BO_ 2565900538 Cert_EOL_FA: 18 TesterMh
 SG_ Cert_EOL_FA_Unused : 0|8@1- (1,0) [-128|127] ""  PCM

BO_ 2565900362 Cert_EOL_4A: 19 PCM
 SG_ Cert_EOL_4A_Unused : 0|8@1- (1,0) [-128|127] "" Vector__XXX

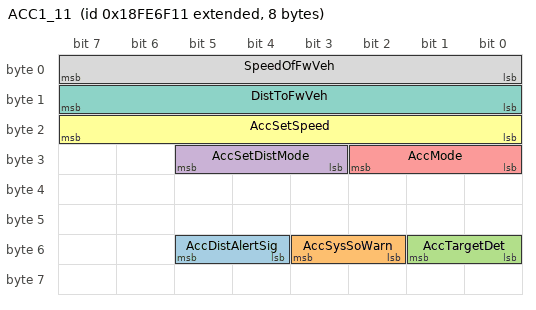
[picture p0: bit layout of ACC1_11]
BO_ 2566811409 ACC1_11: 8 NODE_11
 SG_ AccDistAlertSig : 52|2@1+ (1,0) [0|3] ""  PCM
 SG_ AccSysSoWarn : 50|2@1+ (1,0) [0|3] ""  PCM
 SG_ AccTargetDet : 48|2@1+ (1,0) [0|3] ""  PCM
 SG_ AccSetDistMode : 27|3@1+ (1,0) [0|7] ""  PCM
 SG_ AccMode : 24|3@1+ (1,0) [0|7] ""  PCM
 SG_ AccSetSpeed : 16|8@1+ (1,0) [0|250] "km/h"  PCM
 SG_ DistToFwVeh : 8|8@1+ (1,0) [0|250] "m"  PCM
 SG_ SpeedOfFwVeh : 0|8@1+ (1,0) [0|250] "km/h"  PCM

BO_ 2566803745 ACC2_21: 8 BCM
 SG_ ReqAccDistMode : 5|3@1+ (1,0) [0|7] ""  PCM
 SG_ AccUseDem : 0|2@1+ (1,0) [0|3] ""  PCM

BO_ 2565406464 ACKM_00: 8 ECM
 SG_ Pgn_Ack m0 : 40|24@1+ (1,0) [0|16777215] "binary"  PCM
 SG_ Pgn_Nack m1 : 40|24@1+ (1,0) [0|16777215] "binary"  PCM
 SG_ Pgn_Ad m2 : 40|24@1+ (1,0) [0|16777215] "binary"  PCM
 SG_ Pgn_Busy m3 : 40|24@1+ (1,0) [0|16777215] "binary"  PCM
 SG_ CtrlByte_Ackm M : 0|8@1+ (1,0) [0|255] "binary"  PCM

BO_ 2565406467 ACKM_03: 8 AI_G5_TCM
 SG_ Pgn_Ack_E8FF03 m0 : 40|24@1+ (1,0) [0|16777215] "binary"  PCM
 SG_ Pgn_Nack_E8FF03 m1 : 40|24@1+ (1,0) [0|16777215] "binary"  PCM
 SG_ Pgn_Ad_E8FF03 m2 : 40|24@1+ (1,0) [0|16777215] "binary"  PCM
 SG_ Pgn_Busy_E8FF03 m3 : 40|24@1+ (1,0) [0|16777215] "binary"  PCM
 SG_ AddrAckd m0 : 32|8@1+ (1,0) [0|255] ""  PCM
 SG_ AddrNack m1 : 32|8@1+ (1,0) [0|255] ""  PCM
 SG_ AddrAccessDenied m2 : 32|8@1+ (1,0) [0|255] ""  PCM
 SG_ AddrBusy m3 : 32|8@1+ (1,0) [0|255] ""  PCM
 SG_ GrpFunctVal_Ack m0 : 8|8@1+ (1,0) [0|250] "binary"  PCM
 SG_ GrpFunctVal_Nack m1 : 8|8@1+ (1,0) [0|250] "binary"  PCM
 SG_ CtrlByte_Ackm_E8FF03 M : 0|8@1+ (1,0) [0|255] "binary"  PCM

BO_ 2565406471 ACKM_07: 8 NODE_7
 SG_ Pgn_Ack_E8FF07 m0 : 40|24@1+ (1,0) [0|16777215] "binary"  PCM
 SG_ Pgn_Nack_E8FF07 m1 : 40|24@1+ (1,0) [0|16777215] "binary"  PCM
 SG_ Pgn_Ad_E8FF07 m2 : 40|24@1+ (1,0) [0|16777215] "binary"  PCM
 SG_ Pgn_Busy_E8FF07 m3 : 40|24@1+ (1,0) [0|16777215] "binary"  PCM
 SG_ AddrAckd_E8FF07 m0 : 32|8@1+ (1,0) [0|255] ""  PCM
 SG_ AddrNack_E8FF07 m1 : 32|8@1+ (1,0) [0|255] ""  PCM
 SG_ AddrAccessDenied_E8FF07 m2 : 32|8@1+ (1,0) [0|255] ""  PCM
 SG_ AddrBusy_E8FF07 m3 : 32|8@1+ (1,0) [0|255] ""  PCM
 SG_ CtrlByte_Ackm_E8FF07 M : 0|8@1+ (1,0) [0|255] "binary"  PCM

BO_ 2565406490 ACKM_1A: 8 ECS
 SG_ Pgn_Ack_E8FF1A m0 : 40|24@1+ (1,0) [0|16777215] "binary"  PCM
 SG_ Pgn_Nack_E8FF1A m1 : 40|24@1+ (1,0) [0|16777215] "binary"  PCM
 SG_ Pgn_Ad_E8FF1A m2 : 40|24@1+ (1,0) [0|16777215] "binary"  PCM
 SG_ Pgn_Busy_E8FF1A m3 : 40|24@1+ (1,0) [0|16777215] "binary"  PCM
 SG_ AddrAckd_E8FF1A m0 : 32|8@1+ (1,0) [0|255] ""  PCM
 SG_ AddrNack_E8FF1A m1 : 32|8@1+ (1,0) [0|255] ""  PCM
 SG_ AddrAccessDenied_E8FF1A m2 : 32|8@1+ (1,0) [0|255] ""  PCM
 SG_ AddrBusy_E8FF1A m3 : 32|8@1+ (1,0) [0|255] ""  PCM
 SG_ CtrlByte_Ackm_E8FF1A M : 0|8@1+ (1,0) [0|255] "binary"  PCM

BO_ 2565406493 ACKM_1D: 8 SGW
 SG_ Pgn_Ack_E8FF1D m0 : 40|24@1+ (1,0) [0|16777215] "binary"  PCM
 SG_ Pgn_Nack_E8FF1D m1 : 40|24@1+ (1,0) [0|16777215] "binary"  PCM
 SG_ Pgn_Ad_E8FF1D m2 : 40|24@1+ (1,0) [0|16777215] "binary"  PCM
 SG_ Pgn_Busy_E8FF1D m3 : 40|24@1+ (1,0) [0|16777215] "binary"  PCM
 SG_ AddrAckd_E8FF1D m0 : 32|8@1+ (1,0) [0|255] ""  PCM
 SG_ AddrNack_E8FF1D m1 : 32|8@1+ (1,0) [0|255] ""  PCM
 SG_ AddrAccessDenied_E8FF1D m2 : 32|8@1+ (1,0) [0|255] ""  PCM
 SG_ AddrBusy_E8FF1D m3 : 32|8@1+ (1,0) [0|255] ""  PCM
 SG_ CtrlByte_Ackm_E8FF1D M : 0|8@1+ (1,0) [0|255] "binary"  PCM

BO_ 2565406497 ACKM_21: 8 BCM
 SG_ Pgn_Ack_E8FF21 m0 : 40|24@1+ (1,0) [0|16777215] "binary"  PCM
 SG_ Pgn_Nack_E8FF21 m1 : 40|24@1+ (1,0) [0|16777215] "binary"  PCM
 SG_ Pgn_Ad_E8FF21 m2 : 40|24@1+ (1,0) [0|16777215] "binary"  PCM
 SG_ Pgn_Busy_E8FF21 m3 : 40|24@1+ (1,0) [0|16777215] "binary"  PCM
 SG_ AddrAckd_E8FF21 m0 : 32|8@1+ (1,0) [0|255] ""  PCM
 SG_ AddrNack_E8FF21 m1 : 32|8@1+ (1,0) [0|255] ""  PCM
 SG_ AddrAccessDenied_E8FF21 m2 : 32|8@1+ (1,0) [0|255] ""  PCM
 SG_ AddrBusy_E8FF21 m3 : 32|8@1+ (1,0) [0|255] ""  PCM
 SG_ CtrlByte_Ackm_E8FF21 M : 0|8@1+ (1,0) [0|255] "binary"  PCM

BO_ 2565406500 ACKM_24: 8 NODE_24
 SG_ Pgn_Ack_E8FF24 m0 : 40|24@1+ (1,0) [0|16777215] "binary"  PCM
 SG_ Pgn_Nack_E8FF24 m1 : 40|24@1+ (1,0) [0|16777215] "binary"  PCM
 SG_ Pgn_Ad_E8FF24 m2 : 40|24@1+ (1,0) [0|16777215] "binary"  PCM
 SG_ Pgn_Busy_E8FF24 m3 : 40|24@1+ (1,0) [0|16777215] "binary"  PCM
 SG_ AddrAckd_E8FF24 m0 : 32|8@1+ (1,0) [0|255] ""  PCM
 SG_ AddrNack_E8FF24 m1 : 32|8@1+ (1,0) [0|255] ""  PCM
 SG_ AddrAccessDenied_E8FF24 m2 : 32|8@1+ (1,0) [0|255] ""  PCM
 SG_ AddrBusy_E8FF24 m3 : 32|8@1+ (1,0) [0|255] ""  PCM
 SG_ CtrlByte_Ackm_E8FF24 M : 0|8@1+ (1,0) [0|255] "binary"  PCM

BO_ 2565406503 ACKM_27: 8 VCM
 SG_ Pgn_Ack_E8FF27 m0 : 40|24@1+ (1,0) [0|16777215] "binary"  PCM
 SG_ Pgn_Nack_E8FF27 m1 : 40|24@1+ (1,0) [0|16777215] "binary"  PCM
 SG_ Pgn_Ad_E8FF27 m2 : 40|24@1+ (1,0) [0|16777215] "binary"  PCM
 SG_ Pgn_Busy_E8FF27 m3 : 40|24@1+ (1,0) [0|16777215] "binary"  PCM
 SG_ AddrAckd_E8FF27 m0 : 32|8@1+ (1,0) [0|255] ""  PCM
 SG_ AddrNack_E8FF27 m1 : 32|8@1+ (1,0) [0|255] ""  PCM
 SG_ AddrAccessDenied_E8FF27 m2 : 32|8@1+ (1,0) [0|255] ""  PCM
 SG_ AddrBusy_E8FF27 m3 : 32|8@1+ (1,0) [0|255] ""  PCM
 SG_ CtrlByte_Ackm_E8FF27 M : 0|8@1+ (1,0) [0|255] "binary"  PCM

BO_ 2565406515 ACKM_33: 8 OptiTire
 SG_ Pgn_Ack_E8FF33 m0 : 40|24@1+ (1,0) [0|16777215] "binary"  PCM
 SG_ Pgn_Nack_E8FF33 m1 : 40|24@1+ (1,0) [0|16777215] "binary"  PCM
 SG_ Pgn_Ad_E8FF33 m2 : 40|24@1+ (1,0) [0|16777215] "binary"  PCM
 SG_ Pgn_Busy_E8FF33 m3 : 40|24@1+ (1,0) [0|16777215] "binary"  PCM
 SG_ CtrlByte_Ackm_E8FF33 M : 0|8@1+ (1,0) [0|255] "binary"  PCM

BO_ 2565406529 ACKM_41: 8 NIS_RDR
 SG_ Pgn_Ack_E8FF41 m0 : 40|24@1+ (1,0) [0|16777215] "binary"  PCM
 SG_ Pgn_Nack_E8FF41 m1 : 40|24@1+ (1,0) [0|16777215] "binary"  PCM
 SG_ Pgn_Ad_E8FF41 m2 : 40|24@1+ (1,0) [0|16777215] "binary"  PCM
 SG_ Pgn_Busy_E8FF41 m3 : 40|24@1+ (1,0) [0|16777215] "binary"  PCM
 SG_ AddrAckd_E8FF41 m0 : 32|8@1+ (1,0) [0|255] ""  PCM
 SG_ AddrNack_E8FF41 m1 : 32|8@1+ (1,0) [0|255] ""  PCM
 SG_ AddrAccessDenied_E8FF41 m2 : 32|8@1+ (1,0) [0|255] ""  PCM
 SG_ AddrBusy_E8FF41 m3 : 32|8@1+ (1,0) [0|255] ""  PCM
 SG_ CtrlByte_Ackm_E8FF41 M : 0|8@1+ (1,0) [0|255] "binary"  PCM

BO_ 2565406537 ACKM_49: 8 NODE_49
 SG_ Pgn_Ack_E8FF49 m0 : 40|24@1+ (1,0) [0|16777215] "binary"  PCM
 SG_ Pgn_Nack_E8FF49 m1 : 40|24@1+ (1,0) [0|16777215] "binary"  PCM
 SG_ Pgn_Ad_E8FF49 m2 : 40|24@1+ (1,0) [0|16777215] "binary"  PCM
 SG_ Pgn_Busy_E8FF49 m3 : 40|24@1+ (1,0) [0|16777215] "binary"  PCM
 SG_ AddrAckd_E8FF49 m0 : 32|8@1+ (1,0) [0|255] ""  PCM
 SG_ AddrNack_E8FF49 m1 : 32|8@1+ (1,0) [0|255] ""  PCM
 SG_ AddrAccessDenied_E8FF49 m2 : 32|8@1+ (1,0) [0|255] ""  PCM
 SG_ AddrBusy_E8FF49 m3 : 32|8@1+ (1,0) [0|255] ""  PCM
 SG_ CtrlByte_Ackm_E8FF49 M : 0|8@1+ (1,0) [0|255] "binary"  PCM

BO_ 2565406538 ACKM_4A: 8 PCM
 SG_ Pgn_Ack_E8FF4A m0 : 40|24@1+ (1,0) [0|16777215] "binary" Vector__XXX
 SG_ Pgn_Nack_E8FF4A m1 : 40|24@1+ (1,0) [0|16777215] "binary" Vector__XXX
 SG_ Pgn_Ad_E8FF4A m2 : 40|24@1+ (1,0) [0|16777215] "binary" Vector__XXX
 SG_ Pgn_Busy_E8FF4A m3 : 40|24@1+ (1,0) [0|16777215] "binary" Vector__XXX
 SG_ AddrAckd_E8FF4A m0 : 32|8@1+ (1,0) [0|255] "" Vector__XXX
 SG_ AddrNack_E8FF4A m1 : 32|8@1+ (1,0) [0|255] "" Vector__XXX
 SG_ AddrAccessDenied_E8FF4A m2 : 32|8@1+ (1,0) [0|255] "" Vector__XXX
 SG_ AddrBusy_E8FF4A m3 : 32|8@1+ (1,0) [0|255] "" Vector__XXX
 SG_ CtrlByte_Ackm_E8FF4A M : 0|8@1+ (1,0) [0|255] "binary" Vector__XXX

BO_ 2565406588 ACKM_7C: 8 NODE_7C
 SG_ Pgn_Ack_E8FF7C m0 : 40|24@1+ (1,0) [0|16777215] "binary"  PCM
 SG_ Pgn_Nack_E8FF7C m1 : 40|24@1+ (1,0) [0|16777215] "binary"  PCM
 SG_ Pgn_Ad_E8FF7C m2 : 40|24@1+ (1,0) [0|16777215] "binary"  PCM
 SG_ Pgn_Busy_E8FF7C m3 : 40|24@1+ (1,0) [0|16777215] "binary"  PCM
 SG_ AddrAckd_E8FF7C m0 : 32|8@1+ (1,0) [0|255] ""  PCM
 SG_ AddrNack_E8FF7C m1 : 32|8@1+ (1,0) [0|255] ""  PCM
 SG_ AddrAccessDenied_E8FF7C m2 : 32|8@1+ (1,0) [0|255] ""  PCM
 SG_ AddrBusy_E8FF7C m3 : 32|8@1+ (1,0) [0|255] ""  PCM
 SG_ CtrlByte_Ackm_E8FF7C M : 0|8@1+ (1,0) [0|255] "binary"  PCM

BO_ 2565406598 ACKM_86: 8 NODE_86
 SG_ Pgn_Ack_E8FF86 m0 : 40|24@1+ (1,0) [0|16777215] "binary"  PCM
 SG_ Pgn_Nack_E8FF86 m1 : 40|24@1+ (1,0) [0|16777215] "binary"  PCM
 SG_ Pgn_Ad_E8FF86 m2 : 40|24@1+ (1,0) [0|16777215] "binary"  PCM
 SG_ Pgn_Busy_E8FF86 m3 : 40|24@1+ (1,0) [0|16777215] "binary"  PCM
 SG_ AddrAckd_E8FF86 m0 : 32|8@1+ (1,0) [0|255] ""  PCM
 SG_ AddrNack_E8FF86 m1 : 32|8@1+ (1,0) [0|255] ""  PCM
 SG_ AddrAccessDenied_E8FF86 m2 : 32|8@1+ (1,0) [0|255] ""  PCM
 SG_ AddrBusy_E8FF86 m3 : 32|8@1+ (1,0) [0|255] ""  PCM
 SG_ CtrlByte_Ackm_E8FF86 M : 0|8@1+ (1,0) [0|255] "binary"  PCM

BO_ 2565406599 ACKM_87: 8 NODE_87
 SG_ Pgn_Ack_E8FF87 m0 : 40|24@1+ (1,0) [0|16777215] "binary"  PCM
 SG_ Pgn_Nack_E8FF87 m1 : 40|24@1+ (1,0) [0|16777215] "binary"  PCM
 SG_ Pgn_Ad_E8FF87 m2 : 40|24@1+ (1,0) [0|16777215] "binary"  PCM
 SG_ Pgn_Busy_E8FF87 m3 : 40|24@1+ (1,0) [0|16777215] "binary"  PCM
 SG_ AddrAckd_E8FF87 m0 : 32|8@1+ (1,0) [0|255] ""  PCM
 SG_ AddrNack_E8FF87 m1 : 32|8@1+ (1,0) [0|255] ""  PCM
 SG_ AddrAccessDenied_E8FF87 m2 : 32|8@1+ (1,0) [0|255] ""  PCM
 SG_ AddrBusy_E8FF87 m3 : 32|8@1+ (1,0) [0|255] ""  PCM
 SG_ CtrlByte_Ackm_E8FF87 M : 0|8@1+ (1,0) [0|255] "binary"  PCM

BO_ 2565406702 ACKM_EE: 8 DTCO
 SG_ Pgn_Ack_E8FFEE m0 : 40|24@1+ (1,0) [0|16777215] "binary"  PCM
 SG_ Pgn_Nack_E8FFEE m1 : 40|24@1+ (1,0) [0|16777215] "binary"  PCM
 SG_ Pgn_Ad_E8FFEE m2 : 40|24@1+ (1,0) [0|16777215] "binary"  PCM
 SG_ Pgn_Busy_E8FFEE m3 : 40|24@1+ (1,0) [0|16777215] "binary"  PCM
 SG_ AddrAckd_E8FFEE m0 : 32|8@1+ (1,0) [0|255] ""  PCM
 SG_ AddrNack_E8FFEE m1 : 32|8@1+ (1,0) [0|255] ""  PCM
 SG_ AddrAccessDenied_E8FFEE m2 : 32|8@1+ (1,0) [0|255] ""  PCM
 SG_ AddrBusy_E8FFEE m3 : 32|8@1+ (1,0) [0|255] ""  PCM
 SG_ CtrlByte_Ackm_E8FFEE M : 0|8@1+ (1,0) [0|255] "binary"  PCM

BO_ 2565406703 ACKM_EF: 8 NODE_EF
 SG_ Pgn_Ack_E8FFEF m0 : 40|24@1+ (1,0) [0|16777215] "binary"  PCM
 SG_ Pgn_Nack_E8FFEF m1 : 40|24@1+ (1,0) [0|16777215] "binary"  PCM
 SG_ Pgn_Ad_E8FFEF m2 : 40|24@1+ (1,0) [0|16777215] "binary"  PCM
 SG_ Pgn_Busy_E8FFEF m3 : 40|24@1+ (1,0) [0|16777215] "binary"  PCM
 SG_ AddrAckd_E8FFEF m0 : 32|8@1+ (1,0) [0|255] ""  PCM
 SG_ AddrNack_E8FFEF m1 : 32|8@1+ (1,0) [0|255] ""  PCM
 SG_ AddrAccessDenied_E8FFEF m2 : 32|8@1+ (1,0) [0|255] ""  PCM
 SG_ AddrBusy_E8FFEF m3 : 32|8@1+ (1,0) [0|255] ""  PCM
 SG_ CtrlByte_Ackm_E8FFEF M : 0|8@1+ (1,0) [0|255] "binary"  PCM

BO_ 2565406706 ACKM_F2: 8 NODE_F2
 SG_ Pgn_Ack_E8FFF2 m0 : 40|24@1+ (1,0) [0|16777215] "binary"  PCM
 SG_ Pgn_Nack_E8FFF2 m1 : 40|24@1+ (1,0) [0|16777215] "binary"  PCM
 SG_ Pgn_Ad_E8FFF2 m2 : 40|24@1+ (1,0) [0|16777215] "binary"  PCM
 SG_ Pgn_Busy_E8FFF2 m3 : 40|24@1+ (1,0) [0|16777215] "binary"  PCM
 SG_ AddrAckd_E8FFF2 m0 : 32|8@1+ (1,0) [0|255] ""  PCM
 SG_ AddrNack_E8FFF2 m1 : 32|8@1+ (1,0) [0|255] ""  PCM
 SG_ AddrAccessDenied_E8FFF2 m2 : 32|8@1+ (1,0) [0|255] ""  PCM
 SG_ AddrBusy_E8FFF2 m3 : 32|8@1+ (1,0) [0|255] ""  PCM
 SG_ CtrlByte_Ackm_E8FFF2 M : 0|8@1+ (1,0) [0|255] "binary"  PCM

BO_ 2565406707 ACKM_F3: 8 NODE_F3
 SG_ Pgn_Ack_E8FFF3 m0 : 40|24@1+ (1,0) [0|16777215] "binary"  PCM
 SG_ Pgn_Nack_E8FFF3 m1 : 40|24@1+ (1,0) [0|16777215] "binary"  PCM
 SG_ Pgn_Ad_E8FFF3 m2 : 40|24@1+ (1,0) [0|16777215] "binary"  PCM
 SG_ Pgn_Busy_E8FFF3 m3 : 40|24@1+ (1,0) [0|16777215] "binary"  PCM
 SG_ AddrAckd_E8FFF3 m0 : 32|8@1+ (1,0) [0|255] ""  PCM
 SG_ AddrNack_E8FFF3 m1 : 32|8@1+ (1,0) [0|255] ""  PCM
 SG_ AddrAccessDenied_E8FFF3 m2 : 32|8@1+ (1,0) [0|255] ""  PCM
 SG_ AddrBusy_E8FFF3 m3 : 32|8@1+ (1,0) [0|255] ""  PCM
 SG_ CtrlByte_Ackm_E8FFF3 M : 0|8@1+ (1,0) [0|255] "binary"  PCM

BO_ 2565406708 ACKM_F4: 8 NODE_F4
 SG_ Pgn_Ack_E8FFF4 m0 : 40|24@1+ (1,0) [0|16777215] "binary"  PCM
 SG_ Pgn_Nack_E8FFF4 m1 : 40|24@1+ (1,0) [0|16777215] "binary"  PCM
 SG_ Pgn_Ad_E8FFF4 m2 : 40|24@1+ (1,0) [0|16777215] "binary"  PCM
 SG_ Pgn_Busy_E8FFF4 m3 : 40|24@1+ (1,0) [0|16777215] "binary"  PCM
 SG_ AddrAckd_E8FFF4 m0 : 32|8@1+ (1,0) [0|255] ""  PCM
 SG_ AddrNack_E8FFF4 m1 : 32|8@1+ (1,0) [0|255] ""  PCM
 SG_ AddrAccessDenied_E8FFF4 m2 : 32|8@1+ (1,0) [0|255] ""  PCM
 SG_ AddrBusy_E8FFF4 m3 : 32|8@1+ (1,0) [0|255] ""  PCM
 SG_ CtrlByte_Ackm_E8FFF4 M : 0|8@1+ (1,0) [0|255] "binary"  PCM

CM_ SG_ 2566811409 AccSetDistMode "- 101b when ACC is not selected
-  Used Distance Modes #1 (000b), #3 (010b), #5 (100b)";
CM_ SG_ 2566803745 ReqAccDistMode "- Memorisation and toggle logic in the source device
-  Used Distance Modes #1 (000b), #3 (010b), #5 (100b)";
CM_ SG_ 2566803745 AccUseDem "- 10b used for Error Indicator
-  Memorisation and toggle logic in the source device";
CM_ BO_ 2565406464 "- NACK required as a response to a destination specific request that cannot be served, ACK/NACK not permitted for a global request (SAE J1939/21).";
CM_ SG_ 2565406464 Pgn_Ack "- Value Table filled with the most commonly used PGNs in Iveco applications, ECU implementation may differ";
CM_ SG_ 2565406464 Pgn_Nack "- Value Table filled with the most commonly used PGNs in Iveco applications, ECU implementation may differ";
CM_ SG_ 2565406464 Pgn_Ad "- Value Table filled with the most commonly used PGNs in Iveco applications, ECU implementation may differ";
CM_ SG_ 2565406464 Pgn_Busy "- Value Table filled with the most commonly used PGNs in Iveco applications, ECU implementation may differ";
CM_ BO_ 2565406467 "- NACK required as a response to a destination specific request that cannot be served, ACK/NACK not permitted for a global request (SAE J1939/21).";
CM_ SG_ 2565406467 Pgn_Ack_E8FF03 "- Value Table filled with the most commonly used PGNs in Iveco applications, ECU implementation may differ";
CM_ SG_ 2565406467 Pgn_Nack_E8FF03 "- Value Table filled with the most commonly used PGNs in Iveco applications, ECU implementation may differ";
CM_ SG_ 2565406467 Pgn_Ad_E8FF03 "- Value Table filled with the most commonly used PGNs in Iveco applications, ECU implementation may differ";
CM_ SG_ 2565406467 Pgn_Busy_E8FF03 "- Value Table filled with the most commonly used PGNs in Iveco applications, ECU implementation may differ";
CM_ BO_ 2565406490 "- NACK required as a response to a destination specific request that cannot be served, ACK/NACK not permitted for a global request (SAE J1939/21).";
CM_ SG_ 2565406490 Pgn_Ack_E8FF1A "- Value Table filled with the most commonly used PGNs in Iveco applications, ECU implementation may differ";
CM_ SG_ 2565406490 Pgn_Nack_E8FF1A "- Value Table filled with the most commonly used PGNs in Iveco applications, ECU implementation may differ";
CM_ SG_ 2565406490 Pgn_Ad_E8FF1A "- Value Table filled with the most commonly used PGNs in Iveco applications, ECU implementation may differ";
CM_ SG_ 2565406490 Pgn_Busy_E8FF1A "- Value Table filled with the most commonly used PGNs in Iveco applications, ECU implementation may differ";
CM_ BO_ 2565406493 "- NACK required as a response to a destination specific request that cannot be served, ACK/NACK not permitted for a global request (SAE J1939/21).";
CM_ SG_ 2565406493 Pgn_Ack_E8FF1D "- Value Table filled with the most commonly used PGNs in Iveco applications, ECU implementation may differ";
CM_ SG_ 2565406493 Pgn_Nack_E8FF1D "- Value Table filled with the most commonly used PGNs in Iveco applications, ECU implementation may differ";
CM_ SG_ 2565406493 Pgn_Ad_E8FF1D "- Value Table filled with the most commonly used PGNs in Iveco applications, ECU implementation may differ";
CM_ SG_ 2565406493 Pgn_Busy_E8FF1D "- Value Table filled with the most commonly used PGNs in Iveco applications, ECU implementation may differ";
CM_ BO_ 2565406497 "- NACK required as a response to a destination specific request that cannot be served, ACK/NACK not permitted for a global request (SAE J1939/21).";
CM_ SG_ 2565406497 Pgn_Ack_E8FF21 "- Value Table filled with the most commonly used PGNs in Iveco applications, ECU implementation may differ";
CM_ SG_ 2565406497 Pgn_Nack_E8FF21 "- Value Table filled with the most commonly used PGNs in Iveco applications, ECU implementation may differ";
CM_ SG_ 2565406497 Pgn_Ad_E8FF21 "- Value Table filled with the most commonly used PGNs in Iveco applications, ECU implementation may differ";
CM_ SG_ 2565406497 Pgn_Busy_E8FF21 "- Value Table filled with the most commonly used PGNs in Iveco applications, ECU implementation may differ";
CM_ BO_ 2565406503 "- NACK required as a response to a destination specific request that cannot be served, ACK/NACK not permitted for a global request (SAE J1939/21).";
CM_ SG_ 2565406503 Pgn_Ack_E8FF27 "- Value Table filled with the most commonly used PGNs in Iveco applications, ECU implementation may differ";
CM_ SG_ 2565406503 Pgn_Nack_E8FF27 "- Value Table filled with the most commonly used PGNs in Iveco applications, ECU implementation may differ";
CM_ SG_ 2565406503 Pgn_Ad_E8FF27 "- Value Table filled with the most commonly used PGNs in Iveco applications, ECU implementation may differ";
CM_ SG_ 2565406503 Pgn_Busy_E8FF27 "- Value Table filled with the most commonly used PGNs in Iveco applications, ECU implementation may differ";
CM_ BO_ 2565406515 "- NACK required as a response to a destination specific request that cannot be served, ACK/NACK not permitted for a global request (SAE J1939/21).";
CM_ SG_ 2565406515 Pgn_Ack_E8FF33 "- Value Table filled with the most commonly used PGNs in Iveco applications, ECU implementation may differ";
CM_ SG_ 2565406515 Pgn_Nack_E8FF33 "- Value Table filled with the most commonly used PGNs in Iveco applications, ECU implementation may differ";
CM_ SG_ 2565406515 Pgn_Ad_E8FF33 "- Value Table filled with the most commonly used PGNs in Iveco applications, ECU implementation may differ";
CM_ SG_ 2565406515 Pgn_Busy_E8FF33 "- Value Table filled with the most commonly used PGNs in Iveco applications, ECU implementation may differ";
CM_ BO_ 2565406538 "- NACK required as a response to a destination specific request that cannot be served, ACK/NACK not permitted for a global request (SAE J1939/21).";
CM_ SG_ 2565406538 Pgn_Ack_E8FF4A "- Value Table filled with the most commonly used PGNs in Iveco applications, ECU implementation may differ";
CM_ SG_ 2565406538 Pgn_Nack_E8FF4A "- Value Table filled with the most commonly used PGNs in Iveco applications, ECU implementation may differ";
CM_ SG_ 2565406538 Pgn_Ad_E8FF4A "- Value Table filled with the most commonly used PGNs in Iveco applications, ECU implementation may differ";
CM_ SG_ 2565406538 Pgn_Busy_E8FF4A "- Value Table filled with the most commonly used PGNs in Iveco applications, ECU implementation may differ";
CM_ SG_ 2565406588 Pgn_Ack_E8FF7C "- Value Table filled with the most commonly used PGNs in Iveco applications, ECU implementation may differ";
CM_ SG_ 2565406588 Pgn_Nack_E8FF7C "- Value Table filled with the most commonly used PGNs in Iveco applications, ECU implementation may differ";
CM_ SG_ 2565406588 Pgn_Ad_E8FF7C "- Value Table filled with the most commonly used PGNs in Iveco applications, ECU implementation may differ";
CM_ SG_ 2565406588 Pgn_Busy_E8FF7C "- Value Table filled with the most commonly used PGNs in Iveco applications, ECU implementation may differ";
CM_ BO_ 2565406702 "- NACK required as a response to a destination specific request that cannot be served, ACK/NACK not permitted for a global request (SAE J1939/21).";
CM_ SG_ 2565406702 Pgn_Ack_E8FFEE "- Value Table filled with the most commonly used PGNs in Iveco applications, ECU implementation may differ";
CM_ SG_ 2565406702 Pgn_Nack_E8FFEE "- Value Table filled with the most commonly used PGNs in Iveco applications, ECU implementation may differ";
CM_ SG_ 2565406702 Pgn_Ad_E8FFEE "- Value Table filled with the most commonly used PGNs in Iveco applications, ECU implementation may differ";
CM_ SG_ 2565406702 Pgn_Busy_E8FFEE "- Value Table filled with the most commonly used PGNs in Iveco applications, ECU implementation may differ";
CM_ BO_ 2565406703 "- NACK required as a response to a destination specific request that cannot be served, ACK/NACK not permitted for a global request (SAE J1939/21).";
CM_ SG_ 2565406703 Pgn_Ack_E8FFEF "- Value Table filled with the most commonly used PGNs in Iveco applications, ECU implementation may differ";
CM_ SG_ 2565406703 Pgn_Nack_E8FFEF "- Value Table filled with the most commonly used PGNs in Iveco applications, ECU implementation may differ";
CM_ SG_ 2565406703 Pgn_Ad_E8FFEF "- Value Table filled with the most commonly used PGNs in Iveco applications, ECU implementation may differ";
CM_ SG_ 2565406703 Pgn_Busy_E8FFEF "- Value Table filled with the most commonly used PGNs in Iveco applications, ECU implementation may differ";
CM_ BO_ 2565406706 "- NACK required as a response to a destination specific request that cannot be served, ACK/NACK not permitted for a global request (SAE J1939/21).";
CM_ SG_ 2565406706 Pgn_Ack_E8FFF2 "- Value Table filled with the most commonly used PGNs in Iveco applications, ECU implementation may differ";
CM_ SG_ 2565406706 Pgn_Nack_E8FFF2 "- Value Table filled with the most commonly used PGNs in Iveco applications, ECU implementation may differ";
CM_ SG_ 2565406706 Pgn_Ad_E8FFF2 "- Value Table filled with the most commonly used PGNs in Iveco applications, ECU implementation may differ";
CM_ SG_ 2565406706 Pgn_Busy_E8FFF2 "- Value Table filled with the most commonly used PGNs in Iveco applications, ECU implementation may differ";
CM_ BO_ 2565406707 "- NACK required as a response to a destination specific request that cannot be served, ACK/NACK not permitted for a global request (SAE J1939/21).";
CM_ SG_ 2565406707 Pgn_Ack_E8FFF3 "- Value Table filled with the most commonly used PGNs in Iveco applications, ECU implementation may differ";
CM_ SG_ 2565406707 Pgn_Nack_E8FFF3 "- Value Table filled with the most commonly used PGNs in Iveco applications, ECU implementation may differ";
CM_ SG_ 2565406707 Pgn_Ad_E8FFF3 "- Value Table filled with the most commonly used PGNs in Iveco applications, ECU implementation may differ";
CM_ SG_ 2565406707 Pgn_Busy_E8FFF3 "- Value Table filled with the most commonly used PGNs in Iveco applications, ECU implementation may differ";
CM_ BO_ 2565406708 "- NACK required as a response to a destination specific request that cannot be served, ACK/NACK not permitted for a global request (SAE J1939/21).";
CM_ SG_ 2565406708 Pgn_Ack_E8FFF4 "- Value Table filled with the most commonly used PGNs in Iveco applications, ECU implementation may differ";
CM_ SG_ 2565406708 Pgn_Nack_E8FFF4 "- Value Table filled with the most commonly used PGNs in Iveco applications, ECU implementation may differ";
CM_ SG_ 2565406708 Pgn_Ad_E8FFF4 "- Value Table filled with the most commonly used PGNs in Iveco applications, ECU implementation may differ";
CM_ SG_ 2565406708 Pgn_Busy_E8FFF4 "- Value Table filled with the most commonly used PGNs in Iveco applications, ECU implementation may differ";
BA_DEF_ BO_  "CI_MsgDefinition" STRING ;
BA_DEF_ BO_  "CI_MsgId" INT 0 2147483647;
BA_DEF_ BO_  "CI_MsgName" STRING ;
BA_DEF_ BO_  "GenMsgCycleTime" INT 0 3600000;
BA_DEF_ BO_  "GenMsgCycleTimeFast" INT 0 3600000;
BA_DEF_ BO_  "GenMsgDelayTime" INT 0 3600000;
BA_DEF_ BO_  "GenMsgILSupport" ENUM  "No","Yes";
BA_DEF_ BO_  "GenMsgNrOfRepetition" INT 0 1000000;
BA_DEF_ BO_  "GenMsgRequestable" INT 0 1;
BA_DEF_ BO_  "GenMsgSendType" ENUM  "cyclic","NotUsed","NotUsed","NotUsed","NotUsed","NotUsed","NotUsed","IfActive","noMsgSendType";
BA_DEF_ BO_  "GenMsgStartDelayTime" INT 0 100000;
BA_DEF_ BO_  "TpJ1939VarDlc" ENUM  "No","Yes";
BA_DEF_ BO_  "VFrameFormat" ENUM  "StandardCAN","ExtendedCAN","reserved","J1939PG";
BA_DEF_ SG_  "CI_ParId" STRING ;
BA_DEF_ SG_  "CI_SigId" INT 0 2147483647;
BA_DEF_ SG_  "CI_SigName" STRING ;
BA_DEF_ SG_  "GenSigEVName" STRING ;
BA_DEF_ SG_  "GenSigILSupport" ENUM  "No","Yes";
BA_DEF_ SG_  "GenSigInactiveValue" INT 0 2147483647;
BA_DEF_ SG_  "GenSigSendType" ENUM  "Cyclic","OnWrite","OnWriteWithRepetition","OnChange","OnChangeWithRepetition","IfActive","IfActiveWithRepetition","NoSigSendType";
BA_DEF_ SG_  "GenSigStartValue" INT 0 2147483647;
BA_DEF_ SG_  "GenSigTimeoutTime_PCM" INT 0 3600000;
BA_DEF_ SG_  "GenSigTimeoutTime_SGW" INT 0 3600000;
BA_DEF_ SG_  "SPN" INT 0 524287;
BA_DEF_ SG_  "SigType" ENUM  "Default","Range","RangeSigned","ASCII","Discrete","Control","ReferencePGN","DTC","StringDelimiter","StringLength","StringLengthControl";
BA_DEF_ BU_  "ECU" STRING ;
BA_DEF_ BU_  "ILUsed" ENUM  "No","Yes";
BA_DEF_ BU_  "NmJ1939ECUInstance" INT 0 7;
BA_DEF_ BU_  "NmJ1939IdentityNumber" INT 0 2097151;
BA_DEF_ BU_  "NmStationAddress" INT 0 255;
BA_DEF_ BU_  "NodeLayerModules" STRING ;
BA_DEF_  "Baudrate" INT 0 1000000;
BA_DEF_  "BusType" STRING ;
BA_DEF_  "CI_CcdVersion" STRING ;
BA_DEF_  "Manufacturer" STRING ;
BA_DEF_  "ProtocolType" STRING ;
BA_DEF_DEF_  "CI_MsgDefinition" "";
BA_DEF_DEF_  "CI_MsgId" 0;
BA_DEF_DEF_  "CI_MsgName" "";
BA_DEF_DEF_  "GenMsgCycleTime" 0;
BA_DEF_DEF_  "GenMsgCycleTimeFast" 0;
BA_DEF_DEF_  "GenMsgDelayTime" 1;
BA_DEF_DEF_  "GenMsgILSupport" "Yes";
BA_DEF_DEF_  "GenMsgNrOfRepetition" 0;
BA_DEF_DEF_  "GenMsgRequestable" 0;
BA_DEF_DEF_  "GenMsgSendType" "noMsgSendType";
BA_DEF_DEF_  "GenMsgStartDelayTime" 0;
BA_DEF_DEF_  "TpJ1939VarDlc" "No";
BA_DEF_DEF_  "VFrameFormat" "J1939PG";
BA_DEF_DEF_  "CI_ParId" "";
BA_DEF_DEF_  "CI_SigId" 0;
BA_DEF_DEF_  "CI_SigName" "";
BA_DEF_DEF_  "GenSigEVName" "Env@Nodename_@Signame";
BA_DEF_DEF_  "GenSigILSupport" "Yes";
BA_DEF_DEF_  "GenSigInactiveValue" 0;
BA_DEF_DEF_  "GenSigSendType" "NoSigSendType";
BA_DEF_DEF_  "GenSigStartValue" 0;
BA_DEF_DEF_  "GenSigTimeoutTime_PCM" 0;
BA_DEF_DEF_  "GenSigTimeoutTime_SGW" 0;
BA_DEF_DEF_  "SPN" 0;
BA_DEF_DEF_  "SigType" "Default";
BA_DEF_DEF_  "ECU" "";
BA_DEF_DEF_  "ILUsed" "Yes";
BA_DEF_DEF_  "NmJ1939ECUInstance" 0;
BA_DEF_DEF_  "NmJ1939IdentityNumber" 0;
BA_DEF_DEF_  "NmStationAddress" 254;
BA_DEF_DEF_  "NodeLayerModules" "J1939_IL.dll";
BA_DEF_DEF_  "Baudrate" 0;
BA_DEF_DEF_  "BusType" "";
BA_DEF_DEF_  "CI_CcdVersion" "";
BA_DEF_DEF_  "Manufacturer" "";
BA_DEF_DEF_  "ProtocolType" "";
BA_ "Baudrate" 500000;
BA_ "BusType" "CAN";
BA_ "CI_CcdVersion" "AE";
BA_ "Manufacturer" "Vector";
BA_ "ProtocolType" "J1939";
BA_ "ECU" BU_ PCM "PCM";
BA_ "NmJ1939ECUInstance" BU_ PCM 1;
BA_ "NmJ1939IdentityNumber" BU_ PCM 74;
BA_ "NmStationAddress" BU_ PCM 74;
BA_ "NmStationAddress" BU_ SGW 29;
BA_ "NmStationAddress" BU_ NODE_11 17;
BA_ "NmStationAddress" BU_ BCM 33;
BA_ "NmStationAddress" BU_ ECM 0;
BA_ "NmStationAddress" BU_ AI_G5_TCM 3;
BA_ "NmStationAddress" BU_ NODE_7 7;
BA_ "NmStationAddress" BU_ ECS 26;
BA_ "NmStationAddress" BU_ NODE_24 36;
BA_ "NmStationAddress" BU_ VCM 39;
BA_ "NmStationAddress" BU_ OptiTire 51;
BA_ "NmStationAddress" BU_ NIS_RDR 65;
BA_ "NmStationAddress" BU_ NODE_49 73;
BA_ "NmStationAddress" BU_ NODE_7C 124;
BA_ "NmStationAddress" BU_ NODE_86 134;
BA_ "NmStationAddress" BU_ NODE_87 135;
BA_ "NmStationAddress" BU_ DTCO 238;
BA_ "NmStationAddress" BU_ NODE_EF 239;
BA_ "NmStationAddress" BU_ NODE_F2 242;
BA_ "NmStationAddress" BU_ NODE_F3 243;
BA_ "NmStationAddress" BU_ NODE_F4 244;
BA_ "NmStationAddress" BU_ NODE_F5 245;
BA_ "NmStationAddress" BU_ NODE_F6 246;
BA_ "NmStationAddress" BU_ LDW 42;
BA_ "NmStationAddress" BU_ ICC 23;
BA_ "NmStationAddress" BU_ ECAS 47;
BA_ "NmStationAddress" BU_ NODE_6 6;
BA_ "NmStationAddress" BU_ AEBS 160;
BA_ "NmStationAddress" BU_ PCM_ISA 28;
BA_ "NmStationAddress" BU_ Airbag 83;
BA_ "NmStationAddress" BU_ BSM 11;
BA_ "NmStationAddress" BU_ NODE_5 5;
BA_ "NmStationAddress" BU_ CDC 48;
BA_ "NmStationAddress" BU_ SCU 77;
BA_ "NmStationAddress" BU_ PAM 120;
BA_ "NmStationAddress" BU_ ACM 25;
BA_ "NmStationAddress" BU_ EST54_IRCS 16;
BA_ "NmStationAddress" BU_ NODE_13 19;
BA_ "NmStationAddress" BU_ EM_PTO 114;
BA_ "NmStationAddress" BU_ NODE_81 129;
BA_ "NmStationAddress" BU_ RSRRM 156;
BA_ "NmStationAddress" BU_ ADCU 158;
BA_ "NmStationAddress" BU_ NODE_9F 159;
BA_ "NmStationAddress" BU_ ALM 201;
BA_ "NmStationAddress" BU_ BC2 229;
BA_ "NmStationAddress" BU_ NODE_F1 241;
BA_ "NmStationAddress" BU_ TesterMh 250;
BA_ "NmStationAddress" BU_ NODE_3D 61;
BA_ "NmStationAddress" BU_ AHW 68;
BA_ "NmStationAddress" BU_ NODE_54 84;
BA_ "NmStationAddress" BU_ Mirror 233;
BA_ "NmStationAddress" BU_ NODE_ED 237;
BA_ "NmStationAddress" BU_ NODE_FB 251;
BA_ "NmStationAddress" BU_ NODE_96 150;
BA_ "NmStationAddress" BU_ Tbox 125;
BA_ "NmStationAddress" BU_ NODE_40 64;
BA_ "NmStationAddress" BU_ NODE_1 1;
BA_ "NmStationAddress" BU_ NODE_18 24;
BA_ "NmStationAddress" BU_ NODE_FD 253;
BA_ "NmStationAddress" BU_ RADAR_ACC 252;
BA_ "NmStationAddress" BU_ MCDS 236;
BA_ "NmStationAddress" BU_ NODE_EB 235;
BA_ "NmStationAddress" BU_ MCSL 234;
BA_ "NmStationAddress" BU_ NODE_E8 232;
BA_ "NmStationAddress" BU_ NODE_E7 231;
BA_ "NmStationAddress" BU_ NODE_BF 191;
BA_ "NmStationAddress" BU_ NODE_C8 200;
BA_ "NmStationAddress" BU_ SAS 228;
BA_ "NmStationAddress" BU_ NODE_E3 227;
BA_ "NmStationAddress" BU_ NODE_E2 226;
BA_ "NmStationAddress" BU_ NODE_E1 225;
BA_ "NmStationAddress" BU_ NODE_E0 224;
BA_ "NmStationAddress" BU_ NODE_DF 223;
BA_ "NmStationAddress" BU_ NODE_DE 222;
BA_ "NmStationAddress" BU_ NODE_DD 221;
BA_ "NmStationAddress" BU_ NODE_DC 220;
BA_ "NmStationAddress" BU_ NODE_DB 219;
BA_ "NmStationAddress" BU_ NODE_DA 218;
BA_ "NmStationAddress" BU_ NODE_D9 217;
BA_ "NmStationAddress" BU_ NODE_D8 216;
BA_ "NmStationAddress" BU_ NODE_D7 215;
BA_ "NmStationAddress" BU_ NODE_D6 214;
BA_ "NmStationAddress" BU_ NODE_D5 213;
BA_ "NmStationAddress" BU_ NODE_D4 212;
BA_ "NmStationAddress" BU_ NODE_D1 209;
BA_ "NmStationAddress" BU_ NODE_D0 208;
BA_ "NmStationAddress" BU_ NODE_CF 207;
BA_ "NmStationAddress" BU_ NODE_CB 203;
BA_ "NmStationAddress" BU_ NODE_CA 202;
BA_ "NmStationAddress" BU_ NODE_C7 199;
BA_ "NmStationAddress" BU_ NODE_C6 198;
BA_ "NmStationAddress" BU_ NODE_C4 196;
BA_ "NmStationAddress" BU_ NODE_C3 195;
BA_ "NmStationAddress" BU_ NODE_C2 194;
BA_ "NmStationAddress" BU_ NODE_C1 193;
BA_ "NmStationAddress" BU_ NODE_C0 192;
BA_ "NmStationAddress" BU_ NODE_BD 189;
BA_ "NmStationAddress" BU_ NODE_BB 187;
BA_ "NmStationAddress" BU_ NODE_BA 186;
BA_ "NmStationAddress" BU_ NODE_B9 185;
BA_ "NmStationAddress" BU_ NODE_B8 184;
BA_ "NmStationAddress" BU_ NODE_B7 183;
BA_ "NmStationAddress" BU_ NODE_B6 182;
BA_ "NmStationAddress" BU_ NODE_B2 178;
BA_ "NmStationAddress" BU_ NODE_B5 181;
BA_ "NmStationAddress" BU_ NODE_B1 177;
BA_ "NmStationAddress" BU_ NODE_BC 188;
BA_ "NmStationAddress" BU_ NODE_D3 211;
BA_ "NmStationAddress" BU_ NODE_D2 210;
BA_ "NmStationAddress" BU_ NODE_C5 197;
BA_ "NmStationAddress" BU_ NODE_E6 230;
BA_ "NmStationAddress" BU_ NODE_CE 206;
BA_ "NmStationAddress" BU_ NODE_CD 205;
BA_ "NmStationAddress" BU_ NODE_B4 180;
BA_ "NmStationAddress" BU_ NODE_B3 179;
BA_ "CI_MsgDefinition" BO_ 2566811409 "J1939DA";
BA_ "CI_MsgId" BO_ 2566811409 10666;
BA_ "CI_MsgName" BO_ 2566811409 "ACC1_11 - Adaptive Cruise Control 1";
BA_ "GenMsgCycleTime" BO_ 2566811409 100;
BA_ "GenMsgCycleTimeFast" BO_ 2566811409 100;
BA_ "GenMsgDelayTime" BO_ 2566811409 20;
BA_ "GenMsgSendType" BO_ 2566811409 0;
BA_ "GenMsgStartDelayTime" BO_ 2566811409 76;
BA_ "CI_MsgDefinition" BO_ 2566803745 "J1939DA";
BA_ "CI_MsgId" BO_ 2566803745 10714;
BA_ "CI_MsgName" BO_ 2566803745 "ACC2_21 - Adaptive Cruise Control, Operator Input";
BA_ "GenMsgCycleTime" BO_ 2566803745 250;
BA_ "GenMsgCycleTimeFast" BO_ 2566803745 250;
BA_ "GenMsgDelayTime" BO_ 2566803745 125;
BA_ "GenMsgSendType" BO_ 2566803745 0;
BA_ "GenMsgStartDelayTime" BO_ 2566803745 108;
BA_ "CI_MsgDefinition" BO_ 2565406464 "J1939-21";
BA_ "CI_MsgId" BO_ 2565406464 27077;
BA_ "CI_MsgName" BO_ 2565406464 "ACKM_00 - Acknowledgment Message";
BA_ "CI_MsgDefinition" BO_ 2565406467 "J1939-21";
BA_ "CI_MsgId" BO_ 2565406467 27103;
BA_ "CI_MsgName" BO_ 2565406467 "ACKM_03 - Acknowledgment Message";
BA_ "CI_MsgDefinition" BO_ 2565406471 "J1939-21";
BA_ "CI_MsgId" BO_ 2565406471 38572;
BA_ "CI_MsgName" BO_ 2565406471 "ACKM_07 - Acknowledgment Message";
BA_ "CI_MsgDefinition" BO_ 2565406490 "J1939-21";
BA_ "CI_MsgId" BO_ 2565406490 35151;
BA_ "CI_MsgName" BO_ 2565406490 "ACKM_1A - Acknowledgment Message";
BA_ "CI_MsgDefinition" BO_ 2565406493 "J1939-21";
BA_ "CI_MsgId" BO_ 2565406493 27247;
BA_ "CI_MsgName" BO_ 2565406493 "ACKM_1D - Acknowledgment Message";
BA_ "CI_MsgDefinition" BO_ 2565406497 "J1939-21";
BA_ "CI_MsgId" BO_ 2565406497 27261;
BA_ "CI_MsgName" BO_ 2565406497 "ACKM_21 - Acknowledgment Message";
BA_ "CI_MsgDefinition" BO_ 2565406500 "J1939-21";
BA_ "CI_MsgId" BO_ 2565406500 38586;
BA_ "CI_MsgName" BO_ 2565406500 "ACKM_24 - Acknowledgment Message";
BA_ "CI_MsgDefinition" BO_ 2565406503 "J1939-21";
BA_ "CI_MsgId" BO_ 2565406503 27281;
BA_ "CI_MsgName" BO_ 2565406503 "ACKM_27 - Acknowledgment Message";
BA_ "CI_MsgDefinition" BO_ 2565406515 "J1939-21";
BA_ "CI_MsgId" BO_ 2565406515 27329;
BA_ "CI_MsgName" BO_ 2565406515 "ACKM_33 - Acknowledgment Message";
BA_ "CI_MsgDefinition" BO_ 2565406529 "J1939-21";
BA_ "CI_MsgId" BO_ 2565406529 27357;
BA_ "CI_MsgName" BO_ 2565406529 "ACKM_41 - Acknowledgment Message";
BA_ "CI_MsgDefinition" BO_ 2565406537 "J1939-21";
BA_ "CI_MsgId" BO_ 2565406537 35165;
BA_ "CI_MsgName" BO_ 2565406537 "ACKM_49 - Acknowledgment Message";
BA_ "CI_MsgDefinition" BO_ 2565406538 "J1939-21";
BA_ "CI_MsgId" BO_ 2565406538 27433;
BA_ "CI_MsgName" BO_ 2565406538 "ACKM_4A - Acknowledgment Message";
BA_ "CI_MsgDefinition" BO_ 2565406588 "J1939-21";
BA_ "CI_MsgId" BO_ 2565406588 36834;
BA_ "CI_MsgName" BO_ 2565406588 "ACKM_7C - Acknowledgment Message";
BA_ "CI_MsgDefinition" BO_ 2565406598 "J1939-21";
BA_ "CI_MsgId" BO_ 2565406598 40597;
BA_ "CI_MsgName" BO_ 2565406598 "ACKM_86 - Acknowledgment Message";
BA_ "CI_MsgDefinition" BO_ 2565406599 "J1939-21";
BA_ "CI_MsgId" BO_ 2565406599 40611;
BA_ "CI_MsgName" BO_ 2565406599 "ACKM_87 - Acknowledgment Message";
BA_ "CI_MsgDefinition" BO_ 2565406702 "J1939-21";
BA_ "CI_MsgId" BO_ 2565406702 27609;
BA_ "CI_MsgName" BO_ 2565406702 "ACKM_EE - Acknowledgment Message";
BA_ "CI_MsgDefinition" BO_ 2565406703 "J1939-21";
BA_ "CI_MsgId" BO_ 2565406703 34514;
BA_ "CI_MsgName" BO_ 2565406703 "ACKM_EF - Acknowledgment Message";
BA_ "CI_MsgDefinition" BO_ 2565406706 "J1939-21";
BA_ "CI_MsgId" BO_ 2565406706 39089;
BA_ "CI_MsgName" BO_ 2565406706 "ACKM_F2 - Acknowledgment Message";
BA_ "CI_MsgDefinition" BO_ 2565406707 "J1939-21";
BA_ "CI_MsgId" BO_ 2565406707 32891;
BA_ "CI_MsgName" BO_ 2565406707 "ACKM_F3 - Acknowledgment Message";
BA_ "CI_MsgDefinition" BO_ 2565406708 "J1939-21";
BA_ "CI_MsgId" BO_ 2565406708 32905;
BA_ "CI_MsgName" BO_ 2565406708 "ACKM_F4 - Acknowledgment Message";
BA_ "CI_ParId" SG_ 2566811409 AccDistAlertSig "1796";
BA_ "CI_SigId" SG_ 2566811409 AccDistAlertSig 10673;
BA_ "CI_SigName" SG_ 2566811409 AccDistAlertSig "ACC Distance Alert Signal";
BA_ "GenSigSendType" SG_ 2566811409 AccDistAlertSig 3;
BA_ "GenSigTimeoutTime_PCM" SG_ 2566811409 AccDistAlertSig 500;
BA_ "SPN" SG_ 2566811409 AccDistAlertSig 1796;
BA_ "SigType" SG_ 2566811409 AccDistAlertSig 4;
BA_ "CI_ParId" SG_ 2566811409 AccSysSoWarn "1797";
BA_ "CI_SigId" SG_ 2566811409 AccSysSoWarn 10674;
BA_ "CI_SigName" SG_ 2566811409 AccSysSoWarn "ACC System Shutoff Warning";
BA_ "GenSigSendType" SG_ 2566811409 AccSysSoWarn 3;
BA_ "GenSigTimeoutTime_PCM" SG_ 2566811409 AccSysSoWarn 500;
BA_ "SPN" SG_ 2566811409 AccSysSoWarn 1797;
BA_ "SigType" SG_ 2566811409 AccSysSoWarn 4;
BA_ "CI_ParId" SG_ 2566811409 AccTargetDet "1798";
BA_ "CI_SigId" SG_ 2566811409 AccTargetDet 10675;
BA_ "CI_SigName" SG_ 2566811409 AccTargetDet "ACC Target Detected";
BA_ "GenSigSendType" SG_ 2566811409 AccTargetDet 3;
BA_ "GenSigTimeoutTime_PCM" SG_ 2566811409 AccTargetDet 500;
BA_ "SPN" SG_ 2566811409 AccTargetDet 1798;
BA_ "SigType" SG_ 2566811409 AccTargetDet 4;
BA_ "CI_ParId" SG_ 2566811409 AccSetDistMode "1589";
BA_ "CI_SigId" SG_ 2566811409 AccSetDistMode 10671;
BA_ "CI_SigName" SG_ 2566811409 AccSetDistMode "Adaptive cruise control set distance mode";
BA_ "GenSigSendType" SG_ 2566811409 AccSetDistMode 3;
BA_ "GenSigTimeoutTime_PCM" SG_ 2566811409 AccSetDistMode 500;
BA_ "SPN" SG_ 2566811409 AccSetDistMode 1589;
BA_ "CI_ParId" SG_ 2566811409 AccMode "1590";
BA_ "CI_SigId" SG_ 2566811409 AccMode 10670;
BA_ "CI_SigName" SG_ 2566811409 AccMode "Adaptive Cruise Control Mode";
BA_ "GenSigSendType" SG_ 2566811409 AccMode 3;
BA_ "GenSigTimeoutTime_PCM" SG_ 2566811409 AccMode 500;
BA_ "SPN" SG_ 2566811409 AccMode 1590;
BA_ "CI_ParId" SG_ 2566811409 AccSetSpeed "1588";
BA_ "CI_SigId" SG_ 2566811409 AccSetSpeed 10669;
BA_ "CI_SigName" SG_ 2566811409 AccSetSpeed "Adaptive Cruise Control Set Speed";
BA_ "GenSigSendType" SG_ 2566811409 AccSetSpeed 3;
BA_ "GenSigTimeoutTime_PCM" SG_ 2566811409 AccSetSpeed 500;
BA_ "SPN" SG_ 2566811409 AccSetSpeed 1588;
BA_ "SigType" SG_ 2566811409 AccSetSpeed 1;
BA_ "CI_ParId" SG_ 2566811409 DistToFwVeh "1587";
BA_ "CI_SigId" SG_ 2566811409 DistToFwVeh 10668;
BA_ "CI_SigName" SG_ 2566811409 DistToFwVeh "Distance to forward vehicle";
BA_ "GenSigSendType" SG_ 2566811409 DistToFwVeh 3;
BA_ "GenSigTimeoutTime_PCM" SG_ 2566811409 DistToFwVeh 500;
BA_ "SPN" SG_ 2566811409 DistToFwVeh 1587;
BA_ "SigType" SG_ 2566811409 DistToFwVeh 1;
BA_ "CI_ParId" SG_ 2566811409 SpeedOfFwVeh "1586";
BA_ "CI_SigId" SG_ 2566811409 SpeedOfFwVeh 10667;
BA_ "CI_SigName" SG_ 2566811409 SpeedOfFwVeh "Speed of forward vehicle";
BA_ "GenSigSendType" SG_ 2566811409 SpeedOfFwVeh 3;
BA_ "GenSigTimeoutTime_PCM" SG_ 2566811409 SpeedOfFwVeh 500;
BA_ "SPN" SG_ 2566811409 SpeedOfFwVeh 1586;
BA_ "SigType" SG_ 2566811409 SpeedOfFwVeh 1;
BA_ "CI_ParId" SG_ 2566803745 ReqAccDistMode "1799";
BA_ "CI_SigId" SG_ 2566803745 ReqAccDistMode 10716;
BA_ "CI_SigName" SG_ 2566803745 ReqAccDistMode "Requested ACC Distance Mode";
BA_ "GenSigTimeoutTime_PCM" SG_ 2566803745 ReqAccDistMode 1250;
BA_ "SPN" SG_ 2566803745 ReqAccDistMode 1799;
BA_ "CI_ParId" SG_ 2566803745 AccUseDem "5023";
BA_ "CI_SigId" SG_ 2566803745 AccUseDem 10715;
BA_ "CI_SigName" SG_ 2566803745 AccUseDem "ACC usage demand";
BA_ "GenSigTimeoutTime_PCM" SG_ 2566803745 AccUseDem 1250;
BA_ "SPN" SG_ 2566803745 AccUseDem 5023;
BA_ "SigType" SG_ 2566803745 AccUseDem 4;
BA_ "CI_ParId" SG_ 2565406464 Pgn_Ack "2543";
BA_ "CI_SigId" SG_ 2565406464 Pgn_Ack 27087;
BA_ "CI_SigName" SG_ 2565406464 Pgn_Ack "Parameter Group Number (ACK)";
BA_ "SPN" SG_ 2565406464 Pgn_Ack 2543;
BA_ "CI_ParId" SG_ 2565406464 Pgn_Nack "2545";
BA_ "CI_SigId" SG_ 2565406464 Pgn_Nack 27088;
BA_ "CI_SigName" SG_ 2565406464 Pgn_Nack "Parameter Group Number (NACK)";
BA_ "SPN" SG_ 2565406464 Pgn_Nack 2545;
BA_ "CI_ParId" SG_ 2565406464 Pgn_Ad "2547";
BA_ "CI_SigId" SG_ 2565406464 Pgn_Ad 27089;
BA_ "CI_SigName" SG_ 2565406464 Pgn_Ad "Parameter Group Number (NACK_AD)";
BA_ "SPN" SG_ 2565406464 Pgn_Ad 2547;
BA_ "CI_ParId" SG_ 2565406464 Pgn_Busy "2549";
BA_ "CI_SigId" SG_ 2565406464 Pgn_Busy 27090;
BA_ "CI_SigName" SG_ 2565406464 Pgn_Busy "Parameter Group Number (NACK_Busy)";
BA_ "SPN" SG_ 2565406464 Pgn_Busy 2549;
BA_ "CI_ParId" SG_ 2565406464 CtrlByte_Ackm "2541";
BA_ "CI_SigId" SG_ 2565406464 CtrlByte_Ackm 27078;
BA_ "CI_SigName" SG_ 2565406464 CtrlByte_Ackm "Control Byte (ACKM)";
BA_ "SPN" SG_ 2565406464 CtrlByte_Ackm 2541;
BA_ "CI_ParId" SG_ 2565406467 Pgn_Ack_E8FF03 "2543";
BA_ "CI_SigId" SG_ 2565406467 Pgn_Ack_E8FF03 27113;
BA_ "CI_SigName" SG_ 2565406467 Pgn_Ack_E8FF03 "Parameter Group Number (ACK)";
BA_ "SPN" SG_ 2565406467 Pgn_Ack_E8FF03 2543;
BA_ "CI_ParId" SG_ 2565406467 Pgn_Nack_E8FF03 "2545";
BA_ "CI_SigId" SG_ 2565406467 Pgn_Nack_E8FF03 27114;
BA_ "CI_SigName" SG_ 2565406467 Pgn_Nack_E8FF03 "Parameter Group Number (NACK)";
BA_ "SPN" SG_ 2565406467 Pgn_Nack_E8FF03 2545;
BA_ "CI_ParId" SG_ 2565406467 Pgn_Ad_E8FF03 "2547";
BA_ "CI_SigId" SG_ 2565406467 Pgn_Ad_E8FF03 27115;
BA_ "CI_SigName" SG_ 2565406467 Pgn_Ad_E8FF03 "Parameter Group Number (NACK_AD)";
BA_ "SPN" SG_ 2565406467 Pgn_Ad_E8FF03 2547;
BA_ "CI_ParId" SG_ 2565406467 Pgn_Busy_E8FF03 "2549";
BA_ "CI_SigId" SG_ 2565406467 Pgn_Busy_E8FF03 27116;
BA_ "CI_SigName" SG_ 2565406467 Pgn_Busy_E8FF03 "Parameter Group Number (NACK_Busy)";
BA_ "SPN" SG_ 2565406467 Pgn_Busy_E8FF03 2549;
BA_ "CI_ParId" SG_ 2565406467 AddrAckd "3290";
BA_ "CI_SigId" SG_ 2565406467 AddrAckd 27109;
BA_ "CI_SigName" SG_ 2565406467 AddrAckd "Address Acknowledged";
BA_ "SPN" SG_ 2565406467 AddrAckd 3290;
BA_ "CI_ParId" SG_ 2565406467 AddrNack "3291";
BA_ "CI_SigId" SG_ 2565406467 AddrNack 27110;
BA_ "CI_SigName" SG_ 2565406467 AddrNack "Address Negative Acknowledgement";
BA_ "SPN" SG_ 2565406467 AddrNack 3291;
BA_ "CI_ParId" SG_ 2565406467 AddrAccessDenied "3292";
BA_ "CI_SigId" SG_ 2565406467 AddrAccessDenied 27111;
BA_ "CI_SigName" SG_ 2565406467 AddrAccessDenied "Address Access Denied";
BA_ "SPN" SG_ 2565406467 AddrAccessDenied 3292;
BA_ "CI_ParId" SG_ 2565406467 AddrBusy "3293";
BA_ "CI_SigId" SG_ 2565406467 AddrBusy 27112;
BA_ "CI_SigName" SG_ 2565406467 AddrBusy "Address Busy";
BA_ "SPN" SG_ 2565406467 AddrBusy 3293;
BA_ "CI_ParId" SG_ 2565406467 GrpFunctVal_Ack "2542";
BA_ "CI_SigId" SG_ 2565406467 GrpFunctVal_Ack 27105;
BA_ "CI_SigName" SG_ 2565406467 GrpFunctVal_Ack "Group Function Value (ACK)";
BA_ "SPN" SG_ 2565406467 GrpFunctVal_Ack 2542;
BA_ "CI_ParId" SG_ 2565406467 GrpFunctVal_Nack "2544";
BA_ "CI_SigId" SG_ 2565406467 GrpFunctVal_Nack 27106;
BA_ "CI_SigName" SG_ 2565406467 GrpFunctVal_Nack "Group Function Value (NACK)";
BA_ "SPN" SG_ 2565406467 GrpFunctVal_Nack 2544;
BA_ "CI_ParId" SG_ 2565406467 CtrlByte_Ackm_E8FF03 "2541";
BA_ "CI_SigId" SG_ 2565406467 CtrlByte_Ackm_E8FF03 27104;
BA_ "CI_SigName" SG_ 2565406467 CtrlByte_Ackm_E8FF03 "Control Byte (ACKM)";
BA_ "SPN" SG_ 2565406467 CtrlByte_Ackm_E8FF03 2541;
BA_ "CI_ParId" SG_ 2565406471 Pgn_Ack_E8FF07 "2543";
BA_ "CI_SigId" SG_ 2565406471 Pgn_Ack_E8FF07 38582;
BA_ "CI_SigName" SG_ 2565406471 Pgn_Ack_E8FF07 "Parameter Group Number (ACK)";
BA_ "SPN" SG_ 2565406471 Pgn_Ack_E8FF07 2543;
BA_ "CI_ParId" SG_ 2565406471 Pgn_Nack_E8FF07 "2545";
BA_ "CI_SigId" SG_ 2565406471 Pgn_Nack_E8FF07 38583;
BA_ "CI_SigName" SG_ 2565406471 Pgn_Nack_E8FF07 "Parameter Group Number (NACK)";
BA_ "SPN" SG_ 2565406471 Pgn_Nack_E8FF07 2545;
BA_ "CI_ParId" SG_ 2565406471 Pgn_Ad_E8FF07 "2547";
BA_ "CI_SigId" SG_ 2565406471 Pgn_Ad_E8FF07 38584;
BA_ "CI_SigName" SG_ 2565406471 Pgn_Ad_E8FF07 "Parameter Group Number (NACK_AD)";
BA_ "SPN" SG_ 2565406471 Pgn_Ad_E8FF07 2547;
BA_ "CI_ParId" SG_ 2565406471 Pgn_Busy_E8FF07 "2549";
BA_ "CI_SigId" SG_ 2565406471 Pgn_Busy_E8FF07 38585;
BA_ "CI_SigName" SG_ 2565406471 Pgn_Busy_E8FF07 "Parameter Group Number (NACK_Busy)";
BA_ "SPN" SG_ 2565406471 Pgn_Busy_E8FF07 2549;
BA_ "CI_ParId" SG_ 2565406471 AddrAckd_E8FF07 "3290";
BA_ "CI_SigId" SG_ 2565406471 AddrAckd_E8FF07 38578;
BA_ "CI_SigName" SG_ 2565406471 AddrAckd_E8FF07 "Address Acknowledged";
BA_ "SPN" SG_ 2565406471 AddrAckd_E8FF07 3290;
BA_ "CI_ParId" SG_ 2565406471 AddrNack_E8FF07 "3291";
BA_ "CI_SigId" SG_ 2565406471 AddrNack_E8FF07 38579;
BA_ "CI_SigName" SG_ 2565406471 AddrNack_E8FF07 "Address Negative Acknowledgement";
BA_ "SPN" SG_ 2565406471 AddrNack_E8FF07 3291;
BA_ "CI_ParId" SG_ 2565406471 AddrAccessDenied_E8FF07 "3292";
BA_ "CI_SigId" SG_ 2565406471 AddrAccessDenied_E8FF07 38580;
BA_ "CI_SigName" SG_ 2565406471 AddrAccessDenied_E8FF07 "Address Access Denied";
BA_ "SPN" SG_ 2565406471 AddrAccessDenied_E8FF07 3292;
BA_ "CI_ParId" SG_ 2565406471 AddrBusy_E8FF07 "3293";
BA_ "CI_SigId" SG_ 2565406471 AddrBusy_E8FF07 38581;
BA_ "CI_SigName" SG_ 2565406471 AddrBusy_E8FF07 "Address Busy";
BA_ "SPN" SG_ 2565406471 AddrBusy_E8FF07 3293;
BA_ "CI_ParId" SG_ 2565406471 CtrlByte_Ackm_E8FF07 "2541";
BA_ "CI_SigId" SG_ 2565406471 CtrlByte_Ackm_E8FF07 38573;
BA_ "CI_SigName" SG_ 2565406471 CtrlByte_Ackm_E8FF07 "Control Byte (ACKM)";
BA_ "SPN" SG_ 2565406471 CtrlByte_Ackm_E8FF07 2541;
BA_ "CI_ParId" SG_ 2565406490 Pgn_Ack_E8FF1A "2543";
BA_ "CI_SigId" SG_ 2565406490 Pgn_Ack_E8FF1A 35161;
BA_ "CI_SigName" SG_ 2565406490 Pgn_Ack_E8FF1A "Parameter Group Number (ACK)";
BA_ "SPN" SG_ 2565406490 Pgn_Ack_E8FF1A 2543;
BA_ "CI_ParId" SG_ 2565406490 Pgn_Nack_E8FF1A "2545";
BA_ "CI_SigId" SG_ 2565406490 Pgn_Nack_E8FF1A 35162;
BA_ "CI_SigName" SG_ 2565406490 Pgn_Nack_E8FF1A "Parameter Group Number (NACK)";
BA_ "SPN" SG_ 2565406490 Pgn_Nack_E8FF1A 2545;
BA_ "CI_ParId" SG_ 2565406490 Pgn_Ad_E8FF1A "2547";
BA_ "CI_SigId" SG_ 2565406490 Pgn_Ad_E8FF1A 35163;
BA_ "CI_SigName" SG_ 2565406490 Pgn_Ad_E8FF1A "Parameter Group Number (NACK_AD)";
BA_ "SPN" SG_ 2565406490 Pgn_Ad_E8FF1A 2547;
BA_ "CI_ParId" SG_ 2565406490 Pgn_Busy_E8FF1A "2549";
BA_ "CI_SigId" SG_ 2565406490 Pgn_Busy_E8FF1A 35164;
BA_ "CI_SigName" SG_ 2565406490 Pgn_Busy_E8FF1A "Parameter Group Number (NACK_Busy)";
BA_ "SPN" SG_ 2565406490 Pgn_Busy_E8FF1A 2549;
BA_ "CI_ParId" SG_ 2565406490 AddrAckd_E8FF1A "3290";
BA_ "CI_SigId" SG_ 2565406490 AddrAckd_E8FF1A 35157;
BA_ "CI_SigName" SG_ 2565406490 AddrAckd_E8FF1A "Address Acknowledged";
BA_ "SPN" SG_ 2565406490 AddrAckd_E8FF1A 3290;
BA_ "CI_ParId" SG_ 2565406490 AddrNack_E8FF1A "3291";
BA_ "CI_SigId" SG_ 2565406490 AddrNack_E8FF1A 35158;
BA_ "CI_SigName" SG_ 2565406490 AddrNack_E8FF1A "Address Negative Acknowledgement";
BA_ "SPN" SG_ 2565406490 AddrNack_E8FF1A 3291;
BA_ "CI_ParId" SG_ 2565406490 AddrAccessDenied_E8FF1A "3292";
BA_ "CI_SigId" SG_ 2565406490 AddrAccessDenied_E8FF1A 35159;
BA_ "CI_SigName" SG_ 2565406490 AddrAccessDenied_E8FF1A "Address Access Denied";
BA_ "SPN" SG_ 2565406490 AddrAccessDenied_E8FF1A 3292;
BA_ "CI_ParId" SG_ 2565406490 AddrBusy_E8FF1A "3293";
BA_ "CI_SigId" SG_ 2565406490 AddrBusy_E8FF1A 35160;
BA_ "CI_SigName" SG_ 2565406490 AddrBusy_E8FF1A "Address Busy";
BA_ "SPN" SG_ 2565406490 AddrBusy_E8FF1A 3293;
BA_ "CI_ParId" SG_ 2565406490 CtrlByte_Ackm_E8FF1A "2541";
BA_ "CI_SigId" SG_ 2565406490 CtrlByte_Ackm_E8FF1A 35152;
BA_ "CI_SigName" SG_ 2565406490 CtrlByte_Ackm_E8FF1A "Control Byte (ACKM)";
BA_ "SPN" SG_ 2565406490 CtrlByte_Ackm_E8FF1A 2541;
BA_ "CI_ParId" SG_ 2565406493 Pgn_Ack_E8FF1D "2543";
BA_ "CI_SigId" SG_ 2565406493 Pgn_Ack_E8FF1D 27257;
BA_ "CI_SigName" SG_ 2565406493 Pgn_Ack_E8FF1D "Parameter Group Number (ACK)";
BA_ "SPN" SG_ 2565406493 Pgn_Ack_E8FF1D 2543;
BA_ "CI_ParId" SG_ 2565406493 Pgn_Nack_E8FF1D "2545";
BA_ "CI_SigId" SG_ 2565406493 Pgn_Nack_E8FF1D 27258;
BA_ "CI_SigName" SG_ 2565406493 Pgn_Nack_E8FF1D "Parameter Group Number (NACK)";
BA_ "SPN" SG_ 2565406493 Pgn_Nack_E8FF1D 2545;
BA_ "CI_ParId" SG_ 2565406493 Pgn_Ad_E8FF1D "2547";
BA_ "CI_SigId" SG_ 2565406493 Pgn_Ad_E8FF1D 27259;
BA_ "CI_SigName" SG_ 2565406493 Pgn_Ad_E8FF1D "Parameter Group Number (NACK_AD)";
BA_ "SPN" SG_ 2565406493 Pgn_Ad_E8FF1D 2547;
BA_ "CI_ParId" SG_ 2565406493 Pgn_Busy_E8FF1D "2549";
BA_ "CI_SigId" SG_ 2565406493 Pgn_Busy_E8FF1D 27260;
BA_ "CI_SigName" SG_ 2565406493 Pgn_Busy_E8FF1D "Parameter Group Number (NACK_Busy)";
BA_ "SPN" SG_ 2565406493 Pgn_Busy_E8FF1D 2549;
BA_ "CI_ParId" SG_ 2565406493 AddrAckd_E8FF1D "3290";
BA_ "CI_SigId" SG_ 2565406493 AddrAckd_E8FF1D 27253;
BA_ "CI_SigName" SG_ 2565406493 AddrAckd_E8FF1D "Address Acknowledged";
BA_ "SPN" SG_ 2565406493 AddrAckd_E8FF1D 3290;
BA_ "CI_ParId" SG_ 2565406493 AddrNack_E8FF1D "3291";
BA_ "CI_SigId" SG_ 2565406493 AddrNack_E8FF1D 27254;
BA_ "CI_SigName" SG_ 2565406493 AddrNack_E8FF1D "Address Negative Acknowledgement";
BA_ "SPN" SG_ 2565406493 AddrNack_E8FF1D 3291;
BA_ "CI_ParId" SG_ 2565406493 AddrAccessDenied_E8FF1D "3292";
BA_ "CI_SigId" SG_ 2565406493 AddrAccessDenied_E8FF1D 27255;
BA_ "CI_SigName" SG_ 2565406493 AddrAccessDenied_E8FF1D "Address Access Denied";
BA_ "SPN" SG_ 2565406493 AddrAccessDenied_E8FF1D 3292;
BA_ "CI_ParId" SG_ 2565406493 AddrBusy_E8FF1D "3293";
BA_ "CI_SigId" SG_ 2565406493 AddrBusy_E8FF1D 27256;
BA_ "CI_SigName" SG_ 2565406493 AddrBusy_E8FF1D "Address Busy";
BA_ "SPN" SG_ 2565406493 AddrBusy_E8FF1D 3293;
BA_ "CI_ParId" SG_ 2565406493 CtrlByte_Ackm_E8FF1D "2541";
BA_ "CI_SigId" SG_ 2565406493 CtrlByte_Ackm_E8FF1D 27248;
BA_ "CI_SigName" SG_ 2565406493 CtrlByte_Ackm_E8FF1D "Control Byte (ACKM)";
BA_ "SPN" SG_ 2565406493 CtrlByte_Ackm_E8FF1D 2541;
BA_ "CI_ParId" SG_ 2565406497 Pgn_Ack_E8FF21 "2543";
BA_ "CI_SigId" SG_ 2565406497 Pgn_Ack_E8FF21 27271;
BA_ "CI_SigName" SG_ 2565406497 Pgn_Ack_E8FF21 "Parameter Group Number (ACK)";
BA_ "SPN" SG_ 2565406497 Pgn_Ack_E8FF21 2543;
BA_ "CI_ParId" SG_ 2565406497 Pgn_Nack_E8FF21 "2545";
BA_ "CI_SigId" SG_ 2565406497 Pgn_Nack_E8FF21 27272;
BA_ "CI_SigName" SG_ 2565406497 Pgn_Nack_E8FF21 "Parameter Group Number (NACK)";
BA_ "SPN" SG_ 2565406497 Pgn_Nack_E8FF21 2545;
BA_ "CI_ParId" SG_ 2565406497 Pgn_Ad_E8FF21 "2547";
BA_ "CI_SigId" SG_ 2565406497 Pgn_Ad_E8FF21 27273;
BA_ "CI_SigName" SG_ 2565406497 Pgn_Ad_E8FF21 "Parameter Group Number (NACK_AD)";
BA_ "SPN" SG_ 2565406497 Pgn_Ad_E8FF21 2547;
BA_ "CI_ParId" SG_ 2565406497 Pgn_Busy_E8FF21 "2549";
BA_ "CI_SigId" SG_ 2565406497 Pgn_Busy_E8FF21 27274;
BA_ "CI_SigName" SG_ 2565406497 Pgn_Busy_E8FF21 "Parameter Group Number (NACK_Busy)";
BA_ "SPN" SG_ 2565406497 Pgn_Busy_E8FF21 2549;
BA_ "CI_ParId" SG_ 2565406497 AddrAckd_E8FF21 "3290";
BA_ "CI_SigId" SG_ 2565406497 AddrAckd_E8FF21 27267;
BA_ "CI_SigName" SG_ 2565406497 AddrAckd_E8FF21 "Address Acknowledged";
BA_ "SPN" SG_ 2565406497 AddrAckd_E8FF21 3290;
BA_ "CI_ParId" SG_ 2565406497 AddrNack_E8FF21 "3291";
BA_ "CI_SigId" SG_ 2565406497 AddrNack_E8FF21 27268;
BA_ "CI_SigName" SG_ 2565406497 AddrNack_E8FF21 "Address Negative Acknowledgement";
BA_ "SPN" SG_ 2565406497 AddrNack_E8FF21 3291;
BA_ "CI_ParId" SG_ 2565406497 AddrAccessDenied_E8FF21 "3292";
BA_ "CI_SigId" SG_ 2565406497 AddrAccessDenied_E8FF21 27269;
BA_ "CI_SigName" SG_ 2565406497 AddrAccessDenied_E8FF21 "Address Access Denied";
BA_ "SPN" SG_ 2565406497 AddrAccessDenied_E8FF21 3292;
BA_ "CI_ParId" SG_ 2565406497 AddrBusy_E8FF21 "3293";
BA_ "CI_SigId" SG_ 2565406497 AddrBusy_E8FF21 27270;
BA_ "CI_SigName" SG_ 2565406497 AddrBusy_E8FF21 "Address Busy";
BA_ "SPN" SG_ 2565406497 AddrBusy_E8FF21 3293;
BA_ "CI_ParId" SG_ 2565406497 CtrlByte_Ackm_E8FF21 "2541";
BA_ "CI_SigId" SG_ 2565406497 CtrlByte_Ackm_E8FF21 27262;
BA_ "CI_SigName" SG_ 2565406497 CtrlByte_Ackm_E8FF21 "Control Byte (ACKM)";
BA_ "SPN" SG_ 2565406497 CtrlByte_Ackm_E8FF21 2541;
BA_ "CI_ParId" SG_ 2565406500 Pgn_Ack_E8FF24 "2543";
BA_ "CI_SigId" SG_ 2565406500 Pgn_Ack_E8FF24 38596;
BA_ "CI_SigName" SG_ 2565406500 Pgn_Ack_E8FF24 "Parameter Group Number (ACK)";
BA_ "SPN" SG_ 2565406500 Pgn_Ack_E8FF24 2543;
BA_ "CI_ParId" SG_ 2565406500 Pgn_Nack_E8FF24 "2545";
BA_ "CI_SigId" SG_ 2565406500 Pgn_Nack_E8FF24 38597;
BA_ "CI_SigName" SG_ 2565406500 Pgn_Nack_E8FF24 "Parameter Group Number (NACK)";
BA_ "SPN" SG_ 2565406500 Pgn_Nack_E8FF24 2545;
BA_ "CI_ParId" SG_ 2565406500 Pgn_Ad_E8FF24 "2547";
BA_ "CI_SigId" SG_ 2565406500 Pgn_Ad_E8FF24 38598;
BA_ "CI_SigName" SG_ 2565406500 Pgn_Ad_E8FF24 "Parameter Group Number (NACK_AD)";
BA_ "SPN" SG_ 2565406500 Pgn_Ad_E8FF24 2547;
BA_ "CI_ParId" SG_ 2565406500 Pgn_Busy_E8FF24 "2549";
BA_ "CI_SigId" SG_ 2565406500 Pgn_Busy_E8FF24 38599;
BA_ "CI_SigName" SG_ 2565406500 Pgn_Busy_E8FF24 "Parameter Group Number (NACK_Busy)";
BA_ "SPN" SG_ 2565406500 Pgn_Busy_E8FF24 2549;
BA_ "CI_ParId" SG_ 2565406500 AddrAckd_E8FF24 "3290";
BA_ "CI_SigId" SG_ 2565406500 AddrAckd_E8FF24 38592;
BA_ "CI_SigName" SG_ 2565406500 AddrAckd_E8FF24 "Address Acknowledged";
BA_ "SPN" SG_ 2565406500 AddrAckd_E8FF24 3290;
BA_ "CI_ParId" SG_ 2565406500 AddrNack_E8FF24 "3291";
BA_ "CI_SigId" SG_ 2565406500 AddrNack_E8FF24 38593;
BA_ "CI_SigName" SG_ 2565406500 AddrNack_E8FF24 "Address Negative Acknowledgement";
BA_ "SPN" SG_ 2565406500 AddrNack_E8FF24 3291;
BA_ "CI_ParId" SG_ 2565406500 AddrAccessDenied_E8FF24 "3292";
BA_ "CI_SigId" SG_ 2565406500 AddrAccessDenied_E8FF24 38594;
BA_ "CI_SigName" SG_ 2565406500 AddrAccessDenied_E8FF24 "Address Access Denied";
BA_ "SPN" SG_ 2565406500 AddrAccessDenied_E8FF24 3292;
BA_ "CI_ParId" SG_ 2565406500 AddrBusy_E8FF24 "3293";
BA_ "CI_SigId" SG_ 2565406500 AddrBusy_E8FF24 38595;
BA_ "CI_SigName" SG_ 2565406500 AddrBusy_E8FF24 "Address Busy";
BA_ "SPN" SG_ 2565406500 AddrBusy_E8FF24 3293;
BA_ "CI_ParId" SG_ 2565406500 CtrlByte_Ackm_E8FF24 "2541";
BA_ "CI_SigId" SG_ 2565406500 CtrlByte_Ackm_E8FF24 38587;
BA_ "CI_SigName" SG_ 2565406500 CtrlByte_Ackm_E8FF24 "Control Byte (ACKM)";
BA_ "SPN" SG_ 2565406500 CtrlByte_Ackm_E8FF24 2541;
BA_ "CI_ParId" SG_ 2565406503 Pgn_Ack_E8FF27 "2543";
BA_ "CI_SigId" SG_ 2565406503 Pgn_Ack_E8FF27 27291;
BA_ "CI_SigName" SG_ 2565406503 Pgn_Ack_E8FF27 "Parameter Group Number (ACK)";
BA_ "SPN" SG_ 2565406503 Pgn_Ack_E8FF27 2543;
BA_ "CI_ParId" SG_ 2565406503 Pgn_Nack_E8FF27 "2545";
BA_ "CI_SigId" SG_ 2565406503 Pgn_Nack_E8FF27 27292;
BA_ "CI_SigName" SG_ 2565406503 Pgn_Nack_E8FF27 "Parameter Group Number (NACK)";
BA_ "SPN" SG_ 2565406503 Pgn_Nack_E8FF27 2545;
BA_ "CI_ParId" SG_ 2565406503 Pgn_Ad_E8FF27 "2547";
BA_ "CI_SigId" SG_ 2565406503 Pgn_Ad_E8FF27 27293;
BA_ "CI_SigName" SG_ 2565406503 Pgn_Ad_E8FF27 "Parameter Group Number (NACK_AD)";
BA_ "SPN" SG_ 2565406503 Pgn_Ad_E8FF27 2547;
BA_ "CI_ParId" SG_ 2565406503 Pgn_Busy_E8FF27 "2549";
BA_ "CI_SigId" SG_ 2565406503 Pgn_Busy_E8FF27 27294;
BA_ "CI_SigName" SG_ 2565406503 Pgn_Busy_E8FF27 "Parameter Group Number (NACK_Busy)";
BA_ "SPN" SG_ 2565406503 Pgn_Busy_E8FF27 2549;
BA_ "CI_ParId" SG_ 2565406503 AddrAckd_E8FF27 "3290";
BA_ "CI_SigId" SG_ 2565406503 AddrAckd_E8FF27 27287;
BA_ "CI_SigName" SG_ 2565406503 AddrAckd_E8FF27 "Address Acknowledged";
BA_ "SPN" SG_ 2565406503 AddrAckd_E8FF27 3290;
BA_ "CI_ParId" SG_ 2565406503 AddrNack_E8FF27 "3291";
BA_ "CI_SigId" SG_ 2565406503 AddrNack_E8FF27 27288;
BA_ "CI_SigName" SG_ 2565406503 AddrNack_E8FF27 "Address Negative Acknowledgement";
BA_ "SPN" SG_ 2565406503 AddrNack_E8FF27 3291;
BA_ "CI_ParId" SG_ 2565406503 AddrAccessDenied_E8FF27 "3292";
BA_ "CI_SigId" SG_ 2565406503 AddrAccessDenied_E8FF27 27289;
BA_ "CI_SigName" SG_ 2565406503 AddrAccessDenied_E8FF27 "Address Access Denied";
BA_ "SPN" SG_ 2565406503 AddrAccessDenied_E8FF27 3292;
BA_ "CI_ParId" SG_ 2565406503 AddrBusy_E8FF27 "3293";
BA_ "CI_SigId" SG_ 2565406503 AddrBusy_E8FF27 27290;
BA_ "CI_SigName" SG_ 2565406503 AddrBusy_E8FF27 "Address Busy";
BA_ "SPN" SG_ 2565406503 AddrBusy_E8FF27 3293;
BA_ "CI_ParId" SG_ 2565406503 CtrlByte_Ackm_E8FF27 "2541";
BA_ "CI_SigId" SG_ 2565406503 CtrlByte_Ackm_E8FF27 27282;
BA_ "CI_SigName" SG_ 2565406503 CtrlByte_Ackm_E8FF27 "Control Byte (ACKM)";
BA_ "SPN" SG_ 2565406503 CtrlByte_Ackm_E8FF27 2541;
BA_ "CI_ParId" SG_ 2565406515 Pgn_Ack_E8FF33 "2543";
BA_ "CI_SigId" SG_ 2565406515 Pgn_Ack_E8FF33 27339;
BA_ "CI_SigName" SG_ 2565406515 Pgn_Ack_E8FF33 "Parameter Group Number (ACK)";
BA_ "SPN" SG_ 2565406515 Pgn_Ack_E8FF33 2543;
BA_ "CI_ParId" SG_ 2565406515 Pgn_Nack_E8FF33 "2545";
BA_ "CI_SigId" SG_ 2565406515 Pgn_Nack_E8FF33 27340;
BA_ "CI_SigName" SG_ 2565406515 Pgn_Nack_E8FF33 "Parameter Group Number (NACK)";
BA_ "SPN" SG_ 2565406515 Pgn_Nack_E8FF33 2545;
BA_ "CI_ParId" SG_ 2565406515 Pgn_Ad_E8FF33 "2547";
BA_ "CI_SigId" SG_ 2565406515 Pgn_Ad_E8FF33 27341;
BA_ "CI_SigName" SG_ 2565406515 Pgn_Ad_E8FF33 "Parameter Group Number (NACK_AD)";
BA_ "SPN" SG_ 2565406515 Pgn_Ad_E8FF33 2547;
BA_ "CI_ParId" SG_ 2565406515 Pgn_Busy_E8FF33 "2549";
BA_ "CI_SigId" SG_ 2565406515 Pgn_Busy_E8FF33 27342;
BA_ "CI_SigName" SG_ 2565406515 Pgn_Busy_E8FF33 "Parameter Group Number (NACK_Busy)";
BA_ "SPN" SG_ 2565406515 Pgn_Busy_E8FF33 2549;
BA_ "CI_ParId" SG_ 2565406515 CtrlByte_Ackm_E8FF33 "2541";
BA_ "CI_SigId" SG_ 2565406515 CtrlByte_Ackm_E8FF33 27330;
BA_ "CI_SigName" SG_ 2565406515 CtrlByte_Ackm_E8FF33 "Control Byte (ACKM)";
BA_ "SPN" SG_ 2565406515 CtrlByte_Ackm_E8FF33 2541;
BA_ "CI_ParId" SG_ 2565406529 Pgn_Ack_E8FF41 "2543";
BA_ "CI_SigId" SG_ 2565406529 Pgn_Ack_E8FF41 27367;
BA_ "CI_SigName" SG_ 2565406529 Pgn_Ack_E8FF41 "Parameter Group Number (ACK)";
BA_ "SPN" SG_ 2565406529 Pgn_Ack_E8FF41 2543;
BA_ "CI_ParId" SG_ 2565406529 Pgn_Nack_E8FF41 "2545";
BA_ "CI_SigId" SG_ 2565406529 Pgn_Nack_E8FF41 27368;
BA_ "CI_SigName" SG_ 2565406529 Pgn_Nack_E8FF41 "Parameter Group Number (NACK)";
BA_ "SPN" SG_ 2565406529 Pgn_Nack_E8FF41 2545;
BA_ "CI_ParId" SG_ 2565406529 Pgn_Ad_E8FF41 "2547";
BA_ "CI_SigId" SG_ 2565406529 Pgn_Ad_E8FF41 27369;
BA_ "CI_SigName" SG_ 2565406529 Pgn_Ad_E8FF41 "Parameter Group Number (NACK_AD)";
BA_ "SPN" SG_ 2565406529 Pgn_Ad_E8FF41 2547;
BA_ "CI_ParId" SG_ 2565406529 Pgn_Busy_E8FF41 "2549";
BA_ "CI_SigId" SG_ 2565406529 Pgn_Busy_E8FF41 27370;
BA_ "CI_SigName" SG_ 2565406529 Pgn_Busy_E8FF41 "Parameter Group Number (NACK_Busy)";
BA_ "SPN" SG_ 2565406529 Pgn_Busy_E8FF41 2549;
BA_ "CI_ParId" SG_ 2565406529 AddrAckd_E8FF41 "3290";
BA_ "CI_SigId" SG_ 2565406529 AddrAckd_E8FF41 27363;
BA_ "CI_SigName" SG_ 2565406529 AddrAckd_E8FF41 "Address Acknowledged";
BA_ "SPN" SG_ 2565406529 AddrAckd_E8FF41 3290;
BA_ "CI_ParId" SG_ 2565406529 AddrNack_E8FF41 "3291";
BA_ "CI_SigId" SG_ 2565406529 AddrNack_E8FF41 27364;
BA_ "CI_SigName" SG_ 2565406529 AddrNack_E8FF41 "Address Negative Acknowledgement";
BA_ "SPN" SG_ 2565406529 AddrNack_E8FF41 3291;
BA_ "CI_ParId" SG_ 2565406529 AddrAccessDenied_E8FF41 "3292";
BA_ "CI_SigId" SG_ 2565406529 AddrAccessDenied_E8FF41 27365;
BA_ "CI_SigName" SG_ 2565406529 AddrAccessDenied_E8FF41 "Address Access Denied";
BA_ "SPN" SG_ 2565406529 AddrAccessDenied_E8FF41 3292;
BA_ "CI_ParId" SG_ 2565406529 AddrBusy_E8FF41 "3293";
BA_ "CI_SigId" SG_ 2565406529 AddrBusy_E8FF41 27366;
BA_ "CI_SigName" SG_ 2565406529 AddrBusy_E8FF41 "Address Busy";
BA_ "SPN" SG_ 2565406529 AddrBusy_E8FF41 3293;
BA_ "CI_ParId" SG_ 2565406529 CtrlByte_Ackm_E8FF41 "2541";
BA_ "CI_SigId" SG_ 2565406529 CtrlByte_Ackm_E8FF41 27358;
BA_ "CI_SigName" SG_ 2565406529 CtrlByte_Ackm_E8FF41 "Control Byte (ACKM)";
BA_ "SPN" SG_ 2565406529 CtrlByte_Ackm_E8FF41 2541;
BA_ "CI_ParId" SG_ 2565406537 Pgn_Ack_E8FF49 "2543";
BA_ "CI_SigId" SG_ 2565406537 Pgn_Ack_E8FF49 35175;
BA_ "CI_SigName" SG_ 2565406537 Pgn_Ack_E8FF49 "Parameter Group Number (ACK)";
BA_ "SPN" SG_ 2565406537 Pgn_Ack_E8FF49 2543;
BA_ "CI_ParId" SG_ 2565406537 Pgn_Nack_E8FF49 "2545";
BA_ "CI_SigId" SG_ 2565406537 Pgn_Nack_E8FF49 35176;
BA_ "CI_SigName" SG_ 2565406537 Pgn_Nack_E8FF49 "Parameter Group Number (NACK)";
BA_ "SPN" SG_ 2565406537 Pgn_Nack_E8FF49 2545;
BA_ "CI_ParId" SG_ 2565406537 Pgn_Ad_E8FF49 "2547";
BA_ "CI_SigId" SG_ 2565406537 Pgn_Ad_E8FF49 35177;
BA_ "CI_SigName" SG_ 2565406537 Pgn_Ad_E8FF49 "Parameter Group Number (NACK_AD)";
BA_ "SPN" SG_ 2565406537 Pgn_Ad_E8FF49 2547;
BA_ "CI_ParId" SG_ 2565406537 Pgn_Busy_E8FF49 "2549";
BA_ "CI_SigId" SG_ 2565406537 Pgn_Busy_E8FF49 35178;
BA_ "CI_SigName" SG_ 2565406537 Pgn_Busy_E8FF49 "Parameter Group Number (NACK_Busy)";
BA_ "SPN" SG_ 2565406537 Pgn_Busy_E8FF49 2549;
BA_ "CI_ParId" SG_ 2565406537 AddrAckd_E8FF49 "3290";
BA_ "CI_SigId" SG_ 2565406537 AddrAckd_E8FF49 35171;
BA_ "CI_SigName" SG_ 2565406537 AddrAckd_E8FF49 "Address Acknowledged";
BA_ "SPN" SG_ 2565406537 AddrAckd_E8FF49 3290;
BA_ "CI_ParId" SG_ 2565406537 AddrNack_E8FF49 "3291";
BA_ "CI_SigId" SG_ 2565406537 AddrNack_E8FF49 35172;
BA_ "CI_SigName" SG_ 2565406537 AddrNack_E8FF49 "Address Negative Acknowledgement";
BA_ "SPN" SG_ 2565406537 AddrNack_E8FF49 3291;
BA_ "CI_ParId" SG_ 2565406537 AddrAccessDenied_E8FF49 "3292";
BA_ "CI_SigId" SG_ 2565406537 AddrAccessDenied_E8FF49 35173;
BA_ "CI_SigName" SG_ 2565406537 AddrAccessDenied_E8FF49 "Address Access Denied";
BA_ "SPN" SG_ 2565406537 AddrAccessDenied_E8FF49 3292;
BA_ "CI_ParId" SG_ 2565406537 AddrBusy_E8FF49 "3293";
BA_ "CI_SigId" SG_ 2565406537 AddrBusy_E8FF49 35174;
BA_ "CI_SigName" SG_ 2565406537 AddrBusy_E8FF49 "Address Busy";
BA_ "SPN" SG_ 2565406537 AddrBusy_E8FF49 3293;
BA_ "CI_ParId" SG_ 2565406537 CtrlByte_Ackm_E8FF49 "2541";
BA_ "CI_SigId" SG_ 2565406537 CtrlByte_Ackm_E8FF49 35166;
BA_ "CI_SigName" SG_ 2565406537 CtrlByte_Ackm_E8FF49 "Control Byte (ACKM)";
BA_ "SPN" SG_ 2565406537 CtrlByte_Ackm_E8FF49 2541;
BA_ "CI_ParId" SG_ 2565406538 Pgn_Ack_E8FF4A "2543";
BA_ "CI_SigId" SG_ 2565406538 Pgn_Ack_E8FF4A 27443;
BA_ "CI_SigName" SG_ 2565406538 Pgn_Ack_E8FF4A "Parameter Group Number (ACK)";
BA_ "SPN" SG_ 2565406538 Pgn_Ack_E8FF4A 2543;
BA_ "CI_ParId" SG_ 2565406538 Pgn_Nack_E8FF4A "2545";
BA_ "CI_SigId" SG_ 2565406538 Pgn_Nack_E8FF4A 27444;
BA_ "CI_SigName" SG_ 2565406538 Pgn_Nack_E8FF4A "Parameter Group Number (NACK)";
BA_ "SPN" SG_ 2565406538 Pgn_Nack_E8FF4A 2545;
BA_ "CI_ParId" SG_ 2565406538 Pgn_Ad_E8FF4A "2547";
BA_ "CI_SigId" SG_ 2565406538 Pgn_Ad_E8FF4A 27445;
BA_ "CI_SigName" SG_ 2565406538 Pgn_Ad_E8FF4A "Parameter Group Number (NACK_AD)";
BA_ "SPN" SG_ 2565406538 Pgn_Ad_E8FF4A 2547;
BA_ "CI_ParId" SG_ 2565406538 Pgn_Busy_E8FF4A "2549";
BA_ "CI_SigId" SG_ 2565406538 Pgn_Busy_E8FF4A 27446;
BA_ "CI_SigName" SG_ 2565406538 Pgn_Busy_E8FF4A "Parameter Group Number (NACK_Busy)";
BA_ "SPN" SG_ 2565406538 Pgn_Busy_E8FF4A 2549;
BA_ "CI_ParId" SG_ 2565406538 AddrAckd_E8FF4A "3290";
BA_ "CI_SigId" SG_ 2565406538 AddrAckd_E8FF4A 27439;
BA_ "CI_SigName" SG_ 2565406538 AddrAckd_E8FF4A "Address Acknowledged";
BA_ "SPN" SG_ 2565406538 AddrAckd_E8FF4A 3290;
BA_ "CI_ParId" SG_ 2565406538 AddrNack_E8FF4A "3291";
BA_ "CI_SigId" SG_ 2565406538 AddrNack_E8FF4A 27440;
BA_ "CI_SigName" SG_ 2565406538 AddrNack_E8FF4A "Address Negative Acknowledgement";
BA_ "SPN" SG_ 2565406538 AddrNack_E8FF4A 3291;
BA_ "CI_ParId" SG_ 2565406538 AddrAccessDenied_E8FF4A "3292";
BA_ "CI_SigId" SG_ 2565406538 AddrAccessDenied_E8FF4A 27441;
BA_ "CI_SigName" SG_ 2565406538 AddrAccessDenied_E8FF4A "Address Access Denied";
BA_ "SPN" SG_ 2565406538 AddrAccessDenied_E8FF4A 3292;
BA_ "CI_ParId" SG_ 2565406538 AddrBusy_E8FF4A "3293";
BA_ "CI_SigId" SG_ 2565406538 AddrBusy_E8FF4A 27442;
BA_ "CI_SigName" SG_ 2565406538 AddrBusy_E8FF4A "Address Busy";
BA_ "SPN" SG_ 2565406538 AddrBusy_E8FF4A 3293;
BA_ "CI_ParId" SG_ 2565406538 CtrlByte_Ackm_E8FF4A "2541";
BA_ "CI_SigId" SG_ 2565406538 CtrlByte_Ackm_E8FF4A 27434;
BA_ "CI_SigName" SG_ 2565406538 CtrlByte_Ackm_E8FF4A "Control Byte (ACKM)";
BA_ "SPN" SG_ 2565406538 CtrlByte_Ackm_E8FF4A 2541;
BA_ "CI_ParId" SG_ 2565406588 Pgn_Ack_E8FF7C "2543";
BA_ "CI_SigId" SG_ 2565406588 Pgn_Ack_E8FF7C 36844;
BA_ "CI_SigName" SG_ 2565406588 Pgn_Ack_E8FF7C "Parameter Group Number (ACK)";
BA_ "SPN" SG_ 2565406588 Pgn_Ack_E8FF7C 2543;
BA_ "CI_ParId" SG_ 2565406588 Pgn_Nack_E8FF7C "2545";
BA_ "CI_SigId" SG_ 2565406588 Pgn_Nack_E8FF7C 36845;
BA_ "CI_SigName" SG_ 2565406588 Pgn_Nack_E8FF7C "Parameter Group Number (NACK)";
BA_ "SPN" SG_ 2565406588 Pgn_Nack_E8FF7C 2545;
BA_ "CI_ParId" SG_ 2565406588 Pgn_Ad_E8FF7C "2547";
BA_ "CI_SigId" SG_ 2565406588 Pgn_Ad_E8FF7C 36846;
BA_ "CI_SigName" SG_ 2565406588 Pgn_Ad_E8FF7C "Parameter Group Number (NACK_AD)";
BA_ "SPN" SG_ 2565406588 Pgn_Ad_E8FF7C 2547;
BA_ "CI_ParId" SG_ 2565406588 Pgn_Busy_E8FF7C "2549";
BA_ "CI_SigId" SG_ 2565406588 Pgn_Busy_E8FF7C 36847;
BA_ "CI_SigName" SG_ 2565406588 Pgn_Busy_E8FF7C "Parameter Group Number (NACK_Busy)";
BA_ "SPN" SG_ 2565406588 Pgn_Busy_E8FF7C 2549;
BA_ "CI_ParId" SG_ 2565406588 AddrAckd_E8FF7C "3290";
BA_ "CI_SigId" SG_ 2565406588 AddrAckd_E8FF7C 36840;
BA_ "CI_SigName" SG_ 2565406588 AddrAckd_E8FF7C "Address Acknowledged";
BA_ "SPN" SG_ 2565406588 AddrAckd_E8FF7C 3290;
BA_ "CI_ParId" SG_ 2565406588 AddrNack_E8FF7C "3291";
BA_ "CI_SigId" SG_ 2565406588 AddrNack_E8FF7C 36841;
BA_ "CI_SigName" SG_ 2565406588 AddrNack_E8FF7C "Address Negative Acknowledgement";
BA_ "SPN" SG_ 2565406588 AddrNack_E8FF7C 3291;
BA_ "CI_ParId" SG_ 2565406588 AddrAccessDenied_E8FF7C "3292";
BA_ "CI_SigId" SG_ 2565406588 AddrAccessDenied_E8FF7C 36842;
BA_ "CI_SigName" SG_ 2565406588 AddrAccessDenied_E8FF7C "Address Access Denied";
BA_ "SPN" SG_ 2565406588 AddrAccessDenied_E8FF7C 3292;
BA_ "CI_ParId" SG_ 2565406588 AddrBusy_E8FF7C "3293";
BA_ "CI_SigId" SG_ 2565406588 AddrBusy_E8FF7C 36843;
BA_ "CI_SigName" SG_ 2565406588 AddrBusy_E8FF7C "Address Busy";
BA_ "SPN" SG_ 2565406588 AddrBusy_E8FF7C 3293;
BA_ "CI_ParId" SG_ 2565406588 CtrlByte_Ackm_E8FF7C "2541";
BA_ "CI_SigId" SG_ 2565406588 CtrlByte_Ackm_E8FF7C 36835;
BA_ "CI_SigName" SG_ 2565406588 CtrlByte_Ackm_E8FF7C "Control Byte (ACKM)";
BA_ "SPN" SG_ 2565406588 CtrlByte_Ackm_E8FF7C 2541;
BA_ "CI_ParId" SG_ 2565406598 Pgn_Ack_E8FF86 "2543";
BA_ "CI_SigId" SG_ 2565406598 Pgn_Ack_E8FF86 40607;
BA_ "CI_SigName" SG_ 2565406598 Pgn_Ack_E8FF86 "Parameter Group Number (ACK)";
BA_ "SPN" SG_ 2565406598 Pgn_Ack_E8FF86 2543;
BA_ "CI_ParId" SG_ 2565406598 Pgn_Nack_E8FF86 "2545";
BA_ "CI_SigId" SG_ 2565406598 Pgn_Nack_E8FF86 40608;
BA_ "CI_SigName" SG_ 2565406598 Pgn_Nack_E8FF86 "Parameter Group Number (NACK)";
BA_ "SPN" SG_ 2565406598 Pgn_Nack_E8FF86 2545;
BA_ "CI_ParId" SG_ 2565406598 Pgn_Ad_E8FF86 "2547";
BA_ "CI_SigId" SG_ 2565406598 Pgn_Ad_E8FF86 40609;
BA_ "CI_SigName" SG_ 2565406598 Pgn_Ad_E8FF86 "Parameter Group Number (NACK_AD)";
BA_ "SPN" SG_ 2565406598 Pgn_Ad_E8FF86 2547;
BA_ "CI_ParId" SG_ 2565406598 Pgn_Busy_E8FF86 "2549";
BA_ "CI_SigId" SG_ 2565406598 Pgn_Busy_E8FF86 40610;
BA_ "CI_SigName" SG_ 2565406598 Pgn_Busy_E8FF86 "Parameter Group Number (NACK_Busy)";
BA_ "SPN" SG_ 2565406598 Pgn_Busy_E8FF86 2549;
BA_ "CI_ParId" SG_ 2565406598 AddrAckd_E8FF86 "3290";
BA_ "CI_SigId" SG_ 2565406598 AddrAckd_E8FF86 40603;
BA_ "CI_SigName" SG_ 2565406598 AddrAckd_E8FF86 "Address Acknowledged";
BA_ "SPN" SG_ 2565406598 AddrAckd_E8FF86 3290;
BA_ "CI_ParId" SG_ 2565406598 AddrNack_E8FF86 "3291";
BA_ "CI_SigId" SG_ 2565406598 AddrNack_E8FF86 40604;
BA_ "CI_SigName" SG_ 2565406598 AddrNack_E8FF86 "Address Negative Acknowledgement";
BA_ "SPN" SG_ 2565406598 AddrNack_E8FF86 3291;
BA_ "CI_ParId" SG_ 2565406598 AddrAccessDenied_E8FF86 "3292";
BA_ "CI_SigId" SG_ 2565406598 AddrAccessDenied_E8FF86 40605;
BA_ "CI_SigName" SG_ 2565406598 AddrAccessDenied_E8FF86 "Address Access Denied";
BA_ "SPN" SG_ 2565406598 AddrAccessDenied_E8FF86 3292;
BA_ "CI_ParId" SG_ 2565406598 AddrBusy_E8FF86 "3293";
BA_ "CI_SigId" SG_ 2565406598 AddrBusy_E8FF86 40606;
BA_ "CI_SigName" SG_ 2565406598 AddrBusy_E8FF86 "Address Busy";
BA_ "SPN" SG_ 2565406598 AddrBusy_E8FF86 3293;
BA_ "CI_ParId" SG_ 2565406598 CtrlByte_Ackm_E8FF86 "2541";
BA_ "CI_SigId" SG_ 2565406598 CtrlByte_Ackm_E8FF86 40598;
BA_ "CI_SigName" SG_ 2565406598 CtrlByte_Ackm_E8FF86 "Control Byte (ACKM)";
BA_ "SPN" SG_ 2565406598 CtrlByte_Ackm_E8FF86 2541;
BA_ "CI_ParId" SG_ 2565406599 Pgn_Ack_E8FF87 "2543";
BA_ "CI_SigId" SG_ 2565406599 Pgn_Ack_E8FF87 40621;
BA_ "CI_SigName" SG_ 2565406599 Pgn_Ack_E8FF87 "Parameter Group Number (ACK)";
BA_ "SPN" SG_ 2565406599 Pgn_Ack_E8FF87 2543;
BA_ "CI_ParId" SG_ 2565406599 Pgn_Nack_E8FF87 "2545";
BA_ "CI_SigId" SG_ 2565406599 Pgn_Nack_E8FF87 40622;
BA_ "CI_SigName" SG_ 2565406599 Pgn_Nack_E8FF87 "Parameter Group Number (NACK)";
BA_ "SPN" SG_ 2565406599 Pgn_Nack_E8FF87 2545;
BA_ "CI_ParId" SG_ 2565406599 Pgn_Ad_E8FF87 "2547";
BA_ "CI_SigId" SG_ 2565406599 Pgn_Ad_E8FF87 40623;
BA_ "CI_SigName" SG_ 2565406599 Pgn_Ad_E8FF87 "Parameter Group Number (NACK_AD)";
BA_ "SPN" SG_ 2565406599 Pgn_Ad_E8FF87 2547;
BA_ "CI_ParId" SG_ 2565406599 Pgn_Busy_E8FF87 "2549";
BA_ "CI_SigId" SG_ 2565406599 Pgn_Busy_E8FF87 40624;
BA_ "CI_SigName" SG_ 2565406599 Pgn_Busy_E8FF87 "Parameter Group Number (NACK_Busy)";
BA_ "SPN" SG_ 2565406599 Pgn_Busy_E8FF87 2549;
BA_ "CI_ParId" SG_ 2565406599 AddrAckd_E8FF87 "3290";
BA_ "CI_SigId" SG_ 2565406599 AddrAckd_E8FF87 40617;
BA_ "CI_SigName" SG_ 2565406599 AddrAckd_E8FF87 "Address Acknowledged";
BA_ "SPN" SG_ 2565406599 AddrAckd_E8FF87 3290;
BA_ "CI_ParId" SG_ 2565406599 AddrNack_E8FF87 "3291";
BA_ "CI_SigId" SG_ 2565406599 AddrNack_E8FF87 40618;
BA_ "CI_SigName" SG_ 2565406599 AddrNack_E8FF87 "Address Negative Acknowledgement";
BA_ "SPN" SG_ 2565406599 AddrNack_E8FF87 3291;
BA_ "CI_ParId" SG_ 2565406599 AddrAccessDenied_E8FF87 "3292";
BA_ "CI_SigId" SG_ 2565406599 AddrAccessDenied_E8FF87 40619;
BA_ "CI_SigName" SG_ 2565406599 AddrAccessDenied_E8FF87 "Address Access Denied";
BA_ "SPN" SG_ 2565406599 AddrAccessDenied_E8FF87 3292;
BA_ "CI_ParId" SG_ 2565406599 AddrBusy_E8FF87 "3293";
BA_ "CI_SigId" SG_ 2565406599 AddrBusy_E8FF87 40620;
BA_ "CI_SigName" SG_ 2565406599 AddrBusy_E8FF87 "Address Busy";
BA_ "SPN" SG_ 2565406599 AddrBusy_E8FF87 3293;
BA_ "CI_ParId" SG_ 2565406599 CtrlByte_Ackm_E8FF87 "2541";
BA_ "CI_SigId" SG_ 2565406599 CtrlByte_Ackm_E8FF87 40612;
BA_ "CI_SigName" SG_ 2565406599 CtrlByte_Ackm_E8FF87 "Control Byte (ACKM)";
BA_ "SPN" SG_ 2565406599 CtrlByte_Ackm_E8FF87 2541;
BA_ "CI_ParId" SG_ 2565406702 Pgn_Ack_E8FFEE "2543";
BA_ "CI_SigId" SG_ 2565406702 Pgn_Ack_E8FFEE 27619;
BA_ "CI_SigName" SG_ 2565406702 Pgn_Ack_E8FFEE "Parameter Group Number (ACK)";
BA_ "SPN" SG_ 2565406702 Pgn_Ack_E8FFEE 2543;
BA_ "CI_ParId" SG_ 2565406702 Pgn_Nack_E8FFEE "2545";
BA_ "CI_SigId" SG_ 2565406702 Pgn_Nack_E8FFEE 27620;
BA_ "CI_SigName" SG_ 2565406702 Pgn_Nack_E8FFEE "Parameter Group Number (NACK)";
BA_ "SPN" SG_ 2565406702 Pgn_Nack_E8FFEE 2545;
BA_ "CI_ParId" SG_ 2565406702 Pgn_Ad_E8FFEE "2547";
BA_ "CI_SigId" SG_ 2565406702 Pgn_Ad_E8FFEE 27621;
BA_ "CI_SigName" SG_ 2565406702 Pgn_Ad_E8FFEE "Parameter Group Number (NACK_AD)";
BA_ "SPN" SG_ 2565406702 Pgn_Ad_E8FFEE 2547;
BA_ "CI_ParId" SG_ 2565406702 Pgn_Busy_E8FFEE "2549";
BA_ "CI_SigId" SG_ 2565406702 Pgn_Busy_E8FFEE 27622;
BA_ "CI_SigName" SG_ 2565406702 Pgn_Busy_E8FFEE "Parameter Group Number (NACK_Busy)";
BA_ "SPN" SG_ 2565406702 Pgn_Busy_E8FFEE 2549;
BA_ "CI_ParId" SG_ 2565406702 AddrAckd_E8FFEE "3290";
BA_ "CI_SigId" SG_ 2565406702 AddrAckd_E8FFEE 27615;
BA_ "CI_SigName" SG_ 2565406702 AddrAckd_E8FFEE "Address Acknowledged";
BA_ "SPN" SG_ 2565406702 AddrAckd_E8FFEE 3290;
BA_ "CI_ParId" SG_ 2565406702 AddrNack_E8FFEE "3291";
BA_ "CI_SigId" SG_ 2565406702 AddrNack_E8FFEE 27616;
BA_ "CI_SigName" SG_ 2565406702 AddrNack_E8FFEE "Address Negative Acknowledgement";
BA_ "SPN" SG_ 2565406702 AddrNack_E8FFEE 3291;
BA_ "CI_ParId" SG_ 2565406702 AddrAccessDenied_E8FFEE "3292";
BA_ "CI_SigId" SG_ 2565406702 AddrAccessDenied_E8FFEE 27617;
BA_ "CI_SigName" SG_ 2565406702 AddrAccessDenied_E8FFEE "Address Access Denied";
BA_ "SPN" SG_ 2565406702 AddrAccessDenied_E8FFEE 3292;
BA_ "CI_ParId" SG_ 2565406702 AddrBusy_E8FFEE "3293";
BA_ "CI_SigId" SG_ 2565406702 AddrBusy_E8FFEE 27618;
BA_ "CI_SigName" SG_ 2565406702 AddrBusy_E8FFEE "Address Busy";
BA_ "SPN" SG_ 2565406702 AddrBusy_E8FFEE 3293;
BA_ "CI_ParId" SG_ 2565406702 CtrlByte_Ackm_E8FFEE "2541";
BA_ "CI_SigId" SG_ 2565406702 CtrlByte_Ackm_E8FFEE 27610;
BA_ "CI_SigName" SG_ 2565406702 CtrlByte_Ackm_E8FFEE "Control Byte (ACKM)";
BA_ "SPN" SG_ 2565406702 CtrlByte_Ackm_E8FFEE 2541;
BA_ "CI_ParId" SG_ 2565406703 Pgn_Ack_E8FFEF "2543";
BA_ "CI_SigId" SG_ 2565406703 Pgn_Ack_E8FFEF 34524;
BA_ "CI_SigName" SG_ 2565406703 Pgn_Ack_E8FFEF "Parameter Group Number (ACK)";
BA_ "SPN" SG_ 2565406703 Pgn_Ack_E8FFEF 2543;
BA_ "CI_ParId" SG_ 2565406703 Pgn_Nack_E8FFEF "2545";
BA_ "CI_SigId" SG_ 2565406703 Pgn_Nack_E8FFEF 34525;
BA_ "CI_SigName" SG_ 2565406703 Pgn_Nack_E8FFEF "Parameter Group Number (NACK)";
BA_ "SPN" SG_ 2565406703 Pgn_Nack_E8FFEF 2545;
BA_ "CI_ParId" SG_ 2565406703 Pgn_Ad_E8FFEF "2547";
BA_ "CI_SigId" SG_ 2565406703 Pgn_Ad_E8FFEF 34526;
BA_ "CI_SigName" SG_ 2565406703 Pgn_Ad_E8FFEF "Parameter Group Number (NACK_AD)";
BA_ "SPN" SG_ 2565406703 Pgn_Ad_E8FFEF 2547;
BA_ "CI_ParId" SG_ 2565406703 Pgn_Busy_E8FFEF "2549";
BA_ "CI_SigId" SG_ 2565406703 Pgn_Busy_E8FFEF 34527;
BA_ "CI_SigName" SG_ 2565406703 Pgn_Busy_E8FFEF "Parameter Group Number (NACK_Busy)";
BA_ "SPN" SG_ 2565406703 Pgn_Busy_E8FFEF 2549;
BA_ "CI_ParId" SG_ 2565406703 AddrAckd_E8FFEF "3290";
BA_ "CI_SigId" SG_ 2565406703 AddrAckd_E8FFEF 34520;
BA_ "CI_SigName" SG_ 2565406703 AddrAckd_E8FFEF "Address Acknowledged";
BA_ "SPN" SG_ 2565406703 AddrAckd_E8FFEF 3290;
BA_ "CI_ParId" SG_ 2565406703 AddrNack_E8FFEF "3291";
BA_ "CI_SigId" SG_ 2565406703 AddrNack_E8FFEF 34521;
BA_ "CI_SigName" SG_ 2565406703 AddrNack_E8FFEF "Address Negative Acknowledgement";
BA_ "SPN" SG_ 2565406703 AddrNack_E8FFEF 3291;
BA_ "CI_ParId" SG_ 2565406703 AddrAccessDenied_E8FFEF "3292";
BA_ "CI_SigId" SG_ 2565406703 AddrAccessDenied_E8FFEF 34522;
BA_ "CI_SigName" SG_ 2565406703 AddrAccessDenied_E8FFEF "Address Access Denied";
BA_ "SPN" SG_ 2565406703 AddrAccessDenied_E8FFEF 3292;
BA_ "CI_ParId" SG_ 2565406703 AddrBusy_E8FFEF "3293";
BA_ "CI_SigId" SG_ 2565406703 AddrBusy_E8FFEF 34523;
BA_ "CI_SigName" SG_ 2565406703 AddrBusy_E8FFEF "Address Busy";
BA_ "SPN" SG_ 2565406703 AddrBusy_E8FFEF 3293;
BA_ "CI_ParId" SG_ 2565406703 CtrlByte_Ackm_E8FFEF "2541";
BA_ "CI_SigId" SG_ 2565406703 CtrlByte_Ackm_E8FFEF 34515;
BA_ "CI_SigName" SG_ 2565406703 CtrlByte_Ackm_E8FFEF "Control Byte (ACKM)";
BA_ "SPN" SG_ 2565406703 CtrlByte_Ackm_E8FFEF 2541;
BA_ "CI_ParId" SG_ 2565406706 Pgn_Ack_E8FFF2 "2543";
BA_ "CI_SigId" SG_ 2565406706 Pgn_Ack_E8FFF2 39099;
BA_ "CI_SigName" SG_ 2565406706 Pgn_Ack_E8FFF2 "Parameter Group Number (ACK)";
BA_ "SPN" SG_ 2565406706 Pgn_Ack_E8FFF2 2543;
BA_ "CI_ParId" SG_ 2565406706 Pgn_Nack_E8FFF2 "2545";
BA_ "CI_SigId" SG_ 2565406706 Pgn_Nack_E8FFF2 39100;
BA_ "CI_SigName" SG_ 2565406706 Pgn_Nack_E8FFF2 "Parameter Group Number (NACK)";
BA_ "SPN" SG_ 2565406706 Pgn_Nack_E8FFF2 2545;
BA_ "CI_ParId" SG_ 2565406706 Pgn_Ad_E8FFF2 "2547";
BA_ "CI_SigId" SG_ 2565406706 Pgn_Ad_E8FFF2 39101;
BA_ "CI_SigName" SG_ 2565406706 Pgn_Ad_E8FFF2 "Parameter Group Number (NACK_AD)";
BA_ "SPN" SG_ 2565406706 Pgn_Ad_E8FFF2 2547;
BA_ "CI_ParId" SG_ 2565406706 Pgn_Busy_E8FFF2 "2549";
BA_ "CI_SigId" SG_ 2565406706 Pgn_Busy_E8FFF2 39102;
BA_ "CI_SigName" SG_ 2565406706 Pgn_Busy_E8FFF2 "Parameter Group Number (NACK_Busy)";
BA_ "SPN" SG_ 2565406706 Pgn_Busy_E8FFF2 2549;
BA_ "CI_ParId" SG_ 2565406706 AddrAckd_E8FFF2 "3290";
BA_ "CI_SigId" SG_ 2565406706 AddrAckd_E8FFF2 39095;
BA_ "CI_SigName" SG_ 2565406706 AddrAckd_E8FFF2 "Address Acknowledged";
BA_ "SPN" SG_ 2565406706 AddrAckd_E8FFF2 3290;
BA_ "CI_ParId" SG_ 2565406706 AddrNack_E8FFF2 "3291";
BA_ "CI_SigId" SG_ 2565406706 AddrNack_E8FFF2 39096;
BA_ "CI_SigName" SG_ 2565406706 AddrNack_E8FFF2 "Address Negative Acknowledgement";
BA_ "SPN" SG_ 2565406706 AddrNack_E8FFF2 3291;
BA_ "CI_ParId" SG_ 2565406706 AddrAccessDenied_E8FFF2 "3292";
BA_ "CI_SigId" SG_ 2565406706 AddrAccessDenied_E8FFF2 39097;
BA_ "CI_SigName" SG_ 2565406706 AddrAccessDenied_E8FFF2 "Address Access Denied";
BA_ "SPN" SG_ 2565406706 AddrAccessDenied_E8FFF2 3292;
BA_ "CI_ParId" SG_ 2565406706 AddrBusy_E8FFF2 "3293";
BA_ "CI_SigId" SG_ 2565406706 AddrBusy_E8FFF2 39098;
BA_ "CI_SigName" SG_ 2565406706 AddrBusy_E8FFF2 "Address Busy";
BA_ "SPN" SG_ 2565406706 AddrBusy_E8FFF2 3293;
BA_ "CI_ParId" SG_ 2565406706 CtrlByte_Ackm_E8FFF2 "2541";
BA_ "CI_SigId" SG_ 2565406706 CtrlByte_Ackm_E8FFF2 39090;
BA_ "CI_SigName" SG_ 2565406706 CtrlByte_Ackm_E8FFF2 "Control Byte (ACKM)";
BA_ "SPN" SG_ 2565406706 CtrlByte_Ackm_E8FFF2 2541;
BA_ "CI_ParId" SG_ 2565406707 Pgn_Ack_E8FFF3 "2543";
BA_ "CI_SigId" SG_ 2565406707 Pgn_Ack_E8FFF3 32901;
BA_ "CI_SigName" SG_ 2565406707 Pgn_Ack_E8FFF3 "Parameter Group Number (ACK)";
BA_ "SPN" SG_ 2565406707 Pgn_Ack_E8FFF3 2543;
BA_ "CI_ParId" SG_ 2565406707 Pgn_Nack_E8FFF3 "2545";
BA_ "CI_SigId" SG_ 2565406707 Pgn_Nack_E8FFF3 32902;
BA_ "CI_SigName" SG_ 2565406707 Pgn_Nack_E8FFF3 "Parameter Group Number (NACK)";
BA_ "SPN" SG_ 2565406707 Pgn_Nack_E8FFF3 2545;
BA_ "CI_ParId" SG_ 2565406707 Pgn_Ad_E8FFF3 "2547";
BA_ "CI_SigId" SG_ 2565406707 Pgn_Ad_E8FFF3 32903;
BA_ "CI_SigName" SG_ 2565406707 Pgn_Ad_E8FFF3 "Parameter Group Number (NACK_AD)";
BA_ "SPN" SG_ 2565406707 Pgn_Ad_E8FFF3 2547;
BA_ "CI_ParId" SG_ 2565406707 Pgn_Busy_E8FFF3 "2549";
BA_ "CI_SigId" SG_ 2565406707 Pgn_Busy_E8FFF3 32904;
BA_ "CI_SigName" SG_ 2565406707 Pgn_Busy_E8FFF3 "Parameter Group Number (NACK_Busy)";
BA_ "SPN" SG_ 2565406707 Pgn_Busy_E8FFF3 2549;
BA_ "CI_ParId" SG_ 2565406707 AddrAckd_E8FFF3 "3290";
BA_ "CI_SigId" SG_ 2565406707 AddrAckd_E8FFF3 32897;
BA_ "CI_SigName" SG_ 2565406707 AddrAckd_E8FFF3 "Address Acknowledged";
BA_ "SPN" SG_ 2565406707 AddrAckd_E8FFF3 3290;
BA_ "CI_ParId" SG_ 2565406707 AddrNack_E8FFF3 "3291";
BA_ "CI_SigId" SG_ 2565406707 AddrNack_E8FFF3 32898;
BA_ "CI_SigName" SG_ 2565406707 AddrNack_E8FFF3 "Address Negative Acknowledgement";
BA_ "SPN" SG_ 2565406707 AddrNack_E8FFF3 3291;
BA_ "CI_ParId" SG_ 2565406707 AddrAccessDenied_E8FFF3 "3292";
BA_ "CI_SigId" SG_ 2565406707 AddrAccessDenied_E8FFF3 32899;
BA_ "CI_SigName" SG_ 2565406707 AddrAccessDenied_E8FFF3 "Address Access Denied";
BA_ "SPN" SG_ 2565406707 AddrAccessDenied_E8FFF3 3292;
BA_ "CI_ParId" SG_ 2565406707 AddrBusy_E8FFF3 "3293";
BA_ "CI_SigId" SG_ 2565406707 AddrBusy_E8FFF3 32900;
BA_ "CI_SigName" SG_ 2565406707 AddrBusy_E8FFF3 "Address Busy";
BA_ "SPN" SG_ 2565406707 AddrBusy_E8FFF3 3293;
BA_ "CI_ParId" SG_ 2565406707 CtrlByte_Ackm_E8FFF3 "2541";
BA_ "CI_SigId" SG_ 2565406707 CtrlByte_Ackm_E8FFF3 32892;
BA_ "CI_SigName" SG_ 2565406707 CtrlByte_Ackm_E8FFF3 "Control Byte (ACKM)";
BA_ "SPN" SG_ 2565406707 CtrlByte_Ackm_E8FFF3 2541;
BA_ "CI_ParId" SG_ 2565406708 Pgn_Ack_E8FFF4 "2543";
BA_ "CI_SigId" SG_ 2565406708 Pgn_Ack_E8FFF4 32915;
BA_ "CI_SigName" SG_ 2565406708 Pgn_Ack_E8FFF4 "Parameter Group Number (ACK)";
BA_ "SPN" SG_ 2565406708 Pgn_Ack_E8FFF4 2543;
BA_ "CI_ParId" SG_ 2565406708 Pgn_Nack_E8FFF4 "2545";
BA_ "CI_SigId" SG_ 2565406708 Pgn_Nack_E8FFF4 32916;
BA_ "CI_SigName" SG_ 2565406708 Pgn_Nack_E8FFF4 "Parameter Group Number (NACK)";
BA_ "SPN" SG_ 2565406708 Pgn_Nack_E8FFF4 2545;
BA_ "CI_ParId" SG_ 2565406708 Pgn_Ad_E8FFF4 "2547";
BA_ "CI_SigId" SG_ 2565406708 Pgn_Ad_E8FFF4 32917;
BA_ "CI_SigName" SG_ 2565406708 Pgn_Ad_E8FFF4 "Parameter Group Number (NACK_AD)";
BA_ "SPN" SG_ 2565406708 Pgn_Ad_E8FFF4 2547;
BA_ "CI_ParId" SG_ 2565406708 Pgn_Busy_E8FFF4 "2549";
BA_ "CI_SigId" SG_ 2565406708 Pgn_Busy_E8FFF4 32918;
BA_ "CI_SigName" SG_ 2565406708 Pgn_Busy_E8FFF4 "Parameter Group Number (NACK_Busy)";
BA_ "SPN" SG_ 2565406708 Pgn_Busy_E8FFF4 2549;
BA_ "CI_ParId" SG_ 2565406708 AddrAckd_E8FFF4 "3290";
BA_ "CI_SigId" SG_ 2565406708 AddrAckd_E8FFF4 32911;
BA_ "CI_SigName" SG_ 2565406708 AddrAckd_E8FFF4 "Address Acknowledged";
BA_ "SPN" SG_ 2565406708 AddrAckd_E8FFF4 3290;
BA_ "CI_ParId" SG_ 2565406708 AddrNack_E8FFF4 "3291";
BA_ "CI_SigId" SG_ 2565406708 AddrNack_E8FFF4 32912;
BA_ "CI_SigName" SG_ 2565406708 AddrNack_E8FFF4 "Address Negative Acknowledgement";
BA_ "SPN" SG_ 2565406708 AddrNack_E8FFF4 3291;
BA_ "CI_ParId" SG_ 2565406708 AddrAccessDenied_E8FFF4 "3292";
BA_ "CI_SigId" SG_ 2565406708 AddrAccessDenied_E8FFF4 32913;
BA_ "CI_SigName" SG_ 2565406708 AddrAccessDenied_E8FFF4 "Address Access Denied";
BA_ "SPN" SG_ 2565406708 AddrAccessDenied_E8FFF4 3292;
BA_ "CI_ParId" SG_ 2565406708 AddrBusy_E8FFF4 "3293";
BA_ "CI_SigId" SG_ 2565406708 AddrBusy_E8FFF4 32914;
BA_ "CI_SigName" SG_ 2565406708 AddrBusy_E8FFF4 "Address Busy";
BA_ "SPN" SG_ 2565406708 AddrBusy_E8FFF4 3293;
BA_ "CI_ParId" SG_ 2565406708 CtrlByte_Ackm_E8FFF4 "2541";
BA_ "CI_SigId" SG_ 2565406708 CtrlByte_Ackm_E8FFF4 32906;
BA_ "CI_SigName" SG_ 2565406708 CtrlByte_Ackm_E8FFF4 "Control Byte (ACKM)";
BA_ "SPN" SG_ 2565406708 CtrlByte_Ackm_E8FFF4 2541;
VAL_ 2566811409 AccDistAlertSig 0 "ACC DAS Not Active" 1 "ACC DAS Active" 2 "Reserved" 3 "Take no action" ;
VAL_ 2566811409 AccSysSoWarn 0 "ACC SSOW Not Active" 1 "ACC SSOW Active" 2 "Reserved" 3 "Take no action" ;
VAL_ 2566811409 AccTargetDet 0 "No targets detected" 1 "Target detected" 2 "Reserved" 3 "Take no action" ;
VAL_ 2566811409 AccSetDistMode 0 "Mode #1, largest distance" 1 "Mode #2" 2 "Mode #3" 3 "Mode #4" 4 "Mode #5,shortest distance" 5 "Conventional CC mode" 6 "Error condition" 7 "Not Available/not valid" ;
VAL_ 2566811409 AccMode 0 "Off, Standby, enabled" 1 "Speed control active" 2 "Distance control active" 3 "Overtake mode" 4 "Hold mode" 5 "Finish mode" 6 "Disabled or error condition" 7 "Not Available/not valid" ;
VAL_ 2566811409 DistToFwVeh 255 "no vehicle detected" ;
VAL_ 2566811409 SpeedOfFwVeh 255 "no vehicle detected" ;
VAL_ 2566803745 ReqAccDistMode 0 "Mode #1, largest distance" 1 "Mode #2" 2 "Mode #3" 3 "Mode #4" 4 "Mode #5, shortest distance" 5 "Not defined" 6 "Error condition" 7 "Not Available" ;
VAL_ 2566803745 AccUseDem 0 "Not using ACC keeping" 1 "Using ACC distance keeping" 2 "Reserved" 3 "Don't Care" ;
VAL_ 2565406464 Pgn_Ack 37120 "VLSI1" 40448 "DM29" 41216 "DM33" 41728 "DM31" 41984 "DM30" 47360 "PLLT (Plan List Lifetime)" 47872 "PLD (Plan List Distance)" 49408 "DM21" 49664 "DM20" 49920 "DM22" 53504 "MaintBcIc" 54016 "DM19" 60928 "ACL" 61184 "STOD" 64341 "HVESP3HIST" 64342 "HVESP3CFG" 64343 "HVESP2HIST" 64344 "HVESP2CFG" 64345 "HVESP1HIST" 64346 "HVESP1CFG" 64529 "TGFI" 64579 "TCSI" 64582 "TSIS" 64583 "MTI" 64605 "HVESSCFG" 64606 "HVESSHIST" 64653 "PII" 64701 "A1SCRSI2" 64782 "AT1OGC2" 64784 "AT1IGC2" 64839 "TML" 64879 "EEC8" 64896 "DM28" 64905 "VDS2" 64906 "J2012" 64912 "AETC" 64920 "AT1HI1" 64949 "DM23" 64950 "DM24" 64951 "DM25" 64952 "DM26" 64953 "TPRI" 64965 "ECUID" 64981 "EEC5" 65039 "LC" 65099 "TCFG2" 65109 "GFD" 65127 "CCC" 65131 "DI" 65136 "CVW" 65144 "TP1" 65145 "TP2" 65146 "TP3" 65195 "ETC6" 65196 "EBC4" 65199 "GFC" 65201 "EH" 65202 "GFI1" 65203 "LFI1" 65208 "GTFI" 65212 "CBI" 65214 "EEC4" 65216 "SERV" 65219 "ETC5" 65221 "ETC4" 65223 "ETC3" 65227 "DM02" 65228 "DM03" 65229 "DM04" 65230 "DM05" 65231 "DM06" 65234 "DM10" 65235 "DM11" 65236 "DM12" 65242 "SOFT" 65244 "IO" 65248 "VD" 65250 "TCFG" 65253 "HOURS" 65254 "TD" 65255 "VH" 65256 "VDS" 65257 "LFC1" 65258 "VW" 65259 "CI" 65260 "VI" 65261 "CCSS" 65284 "PB_DriversConsentOnPersonalData" 65340 "PB_HVESSCFG" 65376 "VehCfg" 65413 "PB_3CT" 65482 "PB_ID1" 65484 "PB_VNS" 65502 "Av2" 65520 "SCh" 65521 "DIS" 65524 "PB_IVA" ;
VAL_ 2565406464 Pgn_Nack 37120 "VLSI1" 40448 "DM29" 41216 "DM33" 41728 "DM31" 41984 "DM30" 47360 "PLLT (Plan List Lifetime)" 47872 "PLD (Plan List Distance)" 49408 "DM21" 49664 "DM20" 49920 "DM22" 53504 "MaintBcIc" 54016 "DM19" 60928 "ACL" 61184 "STOD" 64341 "HVESP3HIST" 64342 "HVESP3CFG" 64343 "HVESP2HIST" 64344 "HVESP2CFG" 64345 "HVESP1HIST" 64346 "HVESP1CFG" 64529 "TGFI" 64579 "TCSI" 64582 "TSIS" 64583 "MTI" 64605 "HVESSCFG" 64606 "HVESSHIST" 64653 "PII" 64701 "A1SCRSI2" 64782 "AT1OGC2" 64784 "AT1IGC2" 64839 "TML" 64879 "EEC8" 64896 "DM28" 64905 "VDS2" 64906 "J2012" 64912 "AETC" 64920 "AT1HI1" 64949 "DM23" 64950 "DM24" 64951 "DM25" 64952 "DM26" 64953 "TPRI" 64965 "ECUID" 64981 "EEC5" 65039 "LC" 65099 "TCFG2" 65109 "GFD" 65127 "CCC" 65131 "DI" 65136 "CVW" 65144 "TP1" 65145 "TP2" 65146 "TP3" 65195 "ETC6" 65196 "EBC4" 65199 "GFC" 65201 "EH" 65202 "GFI1" 65203 "LFI1" 65208 "GTFI" 65212 "CBI" 65214 "EEC4" 65216 "SERV" 65219 "ETC5" 65221 "ETC4" 65223 "ETC3" 65227 "DM02" 65228 "DM03" 65229 "DM04" 65230 "DM05" 65231 "DM06" 65234 "DM10" 65235 "DM11" 65236 "DM12" 65242 "SOFT" 65244 "IO" 65248 "VD" 65250 "TCFG" 65253 "HOURS" 65254 "TD" 65255 "VH" 65256 "VDS" 65257 "LFC1" 65258 "VW" 65259 "CI" 65260 "VI" 65261 "CCSS" 65284 "PB_DriversConsentOnPersonalData" 65340 "PB_HVESSCFG" 65376 "VehCfg" 65413 "PB_3CT" 65482 "PB_ID1" 65484 "PB_VNS" 65502 "Av2" 65520 "SCh" 65521 "DIS" 65524 "PB_IVA" ;
VAL_ 2565406464 Pgn_Ad 37120 "VLSI1" 40448 "DM29" 41216 "DM33" 41728 "DM31" 41984 "DM30" 47360 "PLLT (Plan List Lifetime)" 47872 "PLD (Plan List Distance)" 49408 "DM21" 49664 "DM20" 49920 "DM22" 53504 "MaintBcIc" 54016 "DM19" 60928 "ACL" 61184 "STOD" 64341 "HVESP3HIST" 64342 "HVESP3CFG" 64343 "HVESP2HIST" 64344 "HVESP2CFG" 64345 "HVESP1HIST" 64346 "HVESP1CFG" 64529 "TGFI" 64579 "TCSI" 64582 "TSIS" 64583 "MTI" 64605 "HVESSCFG" 64606 "HVESSHIST" 64653 "PII" 64701 "A1SCRSI2" 64782 "AT1OGC2" 64784 "AT1IGC2" 64839 "TML" 64879 "EEC8" 64896 "DM28" 64905 "VDS2" 64906 "J2012" 64912 "AETC" 64920 "AT1HI1" 64949 "DM23" 64950 "DM24" 64951 "DM25" 64952 "DM26" 64953 "TPRI" 64965 "ECUID" 64981 "EEC5" 65039 "LC" 65099 "TCFG2" 65109 "GFD" 65127 "CCC" 65131 "DI" 65136 "CVW" 65144 "TP1" 65145 "TP2" 65146 "TP3" 65195 "ETC6" 65196 "EBC4" 65199 "GFC" 65201 "EH" 65202 "GFI1" 65203 "LFI1" 65208 "GTFI" 65212 "CBI" 65214 "EEC4" 65216 "SERV" 65219 "ETC5" 65221 "ETC4" 65223 "ETC3" 65227 "DM02" 65228 "DM03" 65229 "DM04" 65230 "DM05" 65231 "DM06" 65234 "DM10" 65235 "DM11" 65236 "DM12" 65242 "SOFT" 65244 "IO" 65248 "VD" 65250 "TCFG" 65253 "HOURS" 65254 "TD" 65255 "VH" 65256 "VDS" 65257 "LFC1" 65258 "VW" 65259 "CI" 65260 "VI" 65261 "CCSS" 65284 "PB_DriversConsentOnPersonalData" 65340 "PB_HVESSCFG" 65376 "VehCfg" 65413 "PB_3CT" 65482 "PB_ID1" 65484 "PB_VNS" 65502 "Av2" 65520 "SCh" 65521 "DIS" 65524 "PB_IVA" ;
VAL_ 2565406464 Pgn_Busy 37120 "VLSI1" 40448 "DM29" 41216 "DM33" 41728 "DM31" 41984 "DM30" 47360 "PLLT (Plan List Lifetime)" 47872 "PLD (Plan List Distance)" 49408 "DM21" 49664 "DM20" 49920 "DM22" 53504 "MaintBcIc" 54016 "DM19" 60928 "ACL" 61184 "STOD" 64341 "HVESP3HIST" 64342 "HVESP3CFG" 64343 "HVESP2HIST" 64344 "HVESP2CFG" 64345 "HVESP1HIST" 64346 "HVESP1CFG" 64529 "TGFI" 64579 "TCSI" 64582 "TSIS" 64583 "MTI" 64605 "HVESSCFG" 64606 "HVESSHIST" 64653 "PII" 64701 "A1SCRSI2" 64782 "AT1OGC2" 64784 "AT1IGC2" 64839 "TML" 64879 "EEC8" 64896 "DM28" 64905 "VDS2" 64906 "J2012" 64912 "AETC" 64920 "AT1HI1" 64949 "DM23" 64950 "DM24" 64951 "DM25" 64952 "DM26" 64953 "TPRI" 64965 "ECUID" 64981 "EEC5" 65039 "LC" 65099 "TCFG2" 65109 "GFD" 65127 "CCC" 65131 "DI" 65136 "CVW" 65144 "TP1" 65145 "TP2" 65146 "TP3" 65195 "ETC6" 65196 "EBC4" 65199 "GFC" 65201 "EH" 65202 "GFI1" 65203 "LFI1" 65208 "GTFI" 65212 "CBI" 65214 "EEC4" 65216 "SERV" 65219 "ETC5" 65221 "ETC4" 65223 "ETC3" 65227 "DM02" 65228 "DM03" 65229 "DM04" 65230 "DM05" 65231 "DM06" 65234 "DM10" 65235 "DM11" 65236 "DM12" 65242 "SOFT" 65244 "IO" 65248 "VD" 65250 "TCFG" 65253 "HOURS" 65254 "TD" 65255 "VH" 65256 "VDS" 65257 "LFC1" 65258 "VW" 65259 "CI" 65260 "VI" 65261 "CCSS" 65284 "PB_DriversConsentOnPersonalData" 65340 "PB_HVESSCFG" 65376 "VehCfg" 65413 "PB_3CT" 65482 "PB_ID1" 65484 "PB_VNS" 65502 "Av2" 65520 "SCh" 65521 "DIS" 65524 "PB_IVA" ;
VAL_ 2565406467 Pgn_Ack_E8FF03 37120 "VLSI1" 40448 "DM29" 41216 "DM33" 41728 "DM31" 41984 "DM30" 47360 "PLLT (Plan List Lifetime)" 47872 "PLD (Plan List Distance)" 49408 "DM21" 49664 "DM20" 49920 "DM22" 53504 "MaintBcIc" 54016 "DM19" 60928 "ACL" 61184 "STOD" 64341 "HVESP3HIST" 64342 "HVESP3CFG" 64343 "HVESP2HIST" 64344 "HVESP2CFG" 64345 "HVESP1HIST" 64346 "HVESP1CFG" 64529 "TGFI" 64579 "TCSI" 64582 "TSIS" 64583 "MTI" 64605 "HVESSCFG" 64606 "HVESSHIST" 64653 "PII" 64701 "A1SCRSI2" 64782 "AT1OGC2" 64784 "AT1IGC2" 64839 "TML" 64879 "EEC8" 64896 "DM28" 64905 "VDS2" 64906 "J2012" 64912 "AETC" 64920 "AT1HI1" 64949 "DM23" 64950 "DM24" 64951 "DM25" 64952 "DM26" 64953 "TPRI" 64965 "ECUID" 64981 "EEC5" 65039 "LC" 65099 "TCFG2" 65109 "GFD" 65127 "CCC" 65131 "DI" 65136 "CVW" 65144 "TP1" 65145 "TP2" 65146 "TP3" 65195 "ETC6" 65196 "EBC4" 65199 "GFC" 65201 "EH" 65202 "GFI1" 65203 "LFI1" 65208 "GTFI" 65212 "CBI" 65214 "EEC4" 65216 "SERV" 65219 "ETC5" 65221 "ETC4" 65223 "ETC3" 65227 "DM02" 65228 "DM03" 65229 "DM04" 65230 "DM05" 65231 "DM06" 65234 "DM10" 65235 "DM11" 65236 "DM12" 65242 "SOFT" 65244 "IO" 65248 "VD" 65250 "TCFG" 65253 "HOURS" 65254 "TD" 65255 "VH" 65256 "VDS" 65257 "LFC1" 65258 "VW" 65259 "CI" 65260 "VI" 65261 "CCSS" 65284 "PB_DriversConsentOnPersonalData" 65340 "PB_HVESSCFG" 65376 "VehCfg" 65413 "PB_3CT" 65482 "PB_ID1" 65484 "PB_VNS" 65502 "Av2" 65520 "SCh" 65521 "DIS" 65524 "PB_IVA" ;
VAL_ 2565406467 Pgn_Nack_E8FF03 37120 "VLSI1" 40448 "DM29" 41216 "DM33" 41728 "DM31" 41984 "DM30" 47360 "PLLT (Plan List Lifetime)" 47872 "PLD (Plan List Distance)" 49408 "DM21" 49664 "DM20" 49920 "DM22" 53504 "MaintBcIc" 54016 "DM19" 60928 "ACL" 61184 "STOD" 64341 "HVESP3HIST" 64342 "HVESP3CFG" 64343 "HVESP2HIST" 64344 "HVESP2CFG" 64345 "HVESP1HIST" 64346 "HVESP1CFG" 64529 "TGFI" 64579 "TCSI" 64582 "TSIS" 64583 "MTI" 64605 "HVESSCFG" 64606 "HVESSHIST" 64653 "PII" 64701 "A1SCRSI2" 64782 "AT1OGC2" 64784 "AT1IGC2" 64839 "TML" 64879 "EEC8" 64896 "DM28" 64905 "VDS2" 64906 "J2012" 64912 "AETC" 64920 "AT1HI1" 64949 "DM23" 64950 "DM24" 64951 "DM25" 64952 "DM26" 64953 "TPRI" 64965 "ECUID" 64981 "EEC5" 65039 "LC" 65099 "TCFG2" 65109 "GFD" 65127 "CCC" 65131 "DI" 65136 "CVW" 65144 "TP1" 65145 "TP2" 65146 "TP3" 65195 "ETC6" 65196 "EBC4" 65199 "GFC" 65201 "EH" 65202 "GFI1" 65203 "LFI1" 65208 "GTFI" 65212 "CBI" 65214 "EEC4" 65216 "SERV" 65219 "ETC5" 65221 "ETC4" 65223 "ETC3" 65227 "DM02" 65228 "DM03" 65229 "DM04" 65230 "DM05" 65231 "DM06" 65234 "DM10" 65235 "DM11" 65236 "DM12" 65242 "SOFT" 65244 "IO" 65248 "VD" 65250 "TCFG" 65253 "HOURS" 65254 "TD" 65255 "VH" 65256 "VDS" 65257 "LFC1" 65258 "VW" 65259 "CI" 65260 "VI" 65261 "CCSS" 65284 "PB_DriversConsentOnPersonalData" 65340 "PB_HVESSCFG" 65376 "VehCfg" 65413 "PB_3CT" 65482 "PB_ID1" 65484 "PB_VNS" 65502 "Av2" 65520 "SCh" 65521 "DIS" 65524 "PB_IVA" ;
VAL_ 2565406467 Pgn_Ad_E8FF03 37120 "VLSI1" 40448 "DM29" 41216 "DM33" 41728 "DM31" 41984 "DM30" 47360 "PLLT (Plan List Lifetime)" 47872 "PLD (Plan List Distance)" 49408 "DM21" 49664 "DM20" 49920 "DM22" 53504 "MaintBcIc" 54016 "DM19" 60928 "ACL" 61184 "STOD" 64341 "HVESP3HIST" 64342 "HVESP3CFG" 64343 "HVESP2HIST" 64344 "HVESP2CFG" 64345 "HVESP1HIST" 64346 "HVESP1CFG" 64529 "TGFI" 64579 "TCSI" 64582 "TSIS" 64583 "MTI" 64605 "HVESSCFG" 64606 "HVESSHIST" 64653 "PII" 64701 "A1SCRSI2" 64782 "AT1OGC2" 64784 "AT1IGC2" 64839 "TML" 64879 "EEC8" 64896 "DM28" 64905 "VDS2" 64906 "J2012" 64912 "AETC" 64920 "AT1HI1" 64949 "DM23" 64950 "DM24" 64951 "DM25" 64952 "DM26" 64953 "TPRI" 64965 "ECUID" 64981 "EEC5" 65039 "LC" 65099 "TCFG2" 65109 "GFD" 65127 "CCC" 65131 "DI" 65136 "CVW" 65144 "TP1" 65145 "TP2" 65146 "TP3" 65195 "ETC6" 65196 "EBC4" 65199 "GFC" 65201 "EH" 65202 "GFI1" 65203 "LFI1" 65208 "GTFI" 65212 "CBI" 65214 "EEC4" 65216 "SERV" 65219 "ETC5" 65221 "ETC4" 65223 "ETC3" 65227 "DM02" 65228 "DM03" 65229 "DM04" 65230 "DM05" 65231 "DM06" 65234 "DM10" 65235 "DM11" 65236 "DM12" 65242 "SOFT" 65244 "IO" 65248 "VD" 65250 "TCFG" 65253 "HOURS" 65254 "TD" 65255 "VH" 65256 "VDS" 65257 "LFC1" 65258 "VW" 65259 "CI" 65260 "VI" 65261 "CCSS" 65284 "PB_DriversConsentOnPersonalData" 65340 "PB_HVESSCFG" 65376 "VehCfg" 65413 "PB_3CT" 65482 "PB_ID1" 65484 "PB_VNS" 65502 "Av2" 65520 "SCh" 65521 "DIS" 65524 "PB_IVA" ;
VAL_ 2565406467 Pgn_Busy_E8FF03 37120 "VLSI1" 40448 "DM29" 41216 "DM33" 41728 "DM31" 41984 "DM30" 47360 "PLLT (Plan List Lifetime)" 47872 "PLD (Plan List Distance)" 49408 "DM21" 49664 "DM20" 49920 "DM22" 53504 "MaintBcIc" 54016 "DM19" 60928 "ACL" 61184 "STOD" 64341 "HVESP3HIST" 64342 "HVESP3CFG" 64343 "HVESP2HIST" 64344 "HVESP2CFG" 64345 "HVESP1HIST" 64346 "HVESP1CFG" 64529 "TGFI" 64579 "TCSI" 64582 "TSIS" 64583 "MTI" 64605 "HVESSCFG" 64606 "HVESSHIST" 64653 "PII" 64701 "A1SCRSI2" 64782 "AT1OGC2" 64784 "AT1IGC2" 64839 "TML" 64879 "EEC8" 64896 "DM28" 64905 "VDS2" 64906 "J2012" 64912 "AETC" 64920 "AT1HI1" 64949 "DM23" 64950 "DM24" 64951 "DM25" 64952 "DM26" 64953 "TPRI" 64965 "ECUID" 64981 "EEC5" 65039 "LC" 65099 "TCFG2" 65109 "GFD" 65127 "CCC" 65131 "DI" 65136 "CVW" 65144 "TP1" 65145 "TP2" 65146 "TP3" 65195 "ETC6" 65196 "EBC4" 65199 "GFC" 65201 "EH" 65202 "GFI1" 65203 "LFI1" 65208 "GTFI" 65212 "CBI" 65214 "EEC4" 65216 "SERV" 65219 "ETC5" 65221 "ETC4" 65223 "ETC3" 65227 "DM02" 65228 "DM03" 65229 "DM04" 65230 "DM05" 65231 "DM06" 65234 "DM10" 65235 "DM11" 65236 "DM12" 65242 "SOFT" 65244 "IO" 65248 "VD" 65250 "TCFG" 65253 "HOURS" 65254 "TD" 65255 "VH" 65256 "VDS" 65257 "LFC1" 65258 "VW" 65259 "CI" 65260 "VI" 65261 "CCSS" 65284 "PB_DriversConsentOnPersonalData" 65340 "PB_HVESSCFG" 65376 "VehCfg" 65413 "PB_3CT" 65482 "PB_ID1" 65484 "PB_VNS" 65502 "Av2" 65520 "SCh" 65521 "DIS" 65524 "PB_IVA" ;
VAL_ 2565406471 Pgn_Ack_E8FF07 37120 "VLSI1" 40448 "DM29" 41216 "DM33" 41728 "DM31" 41984 "DM30" 47360 "PLLT (Plan List Lifetime)" 47872 "PLD (Plan List Distance)" 49408 "DM21" 49664 "DM20" 49920 "DM22" 53504 "MaintBcIc" 54016 "DM19" 60928 "ACL" 61184 "STOD" 64341 "HVESP3HIST" 64342 "HVESP3CFG" 64343 "HVESP2HIST" 64344 "HVESP2CFG" 64345 "HVESP1HIST" 64346 "HVESP1CFG" 64529 "TGFI" 64579 "TCSI" 64582 "TSIS" 64583 "MTI" 64605 "HVESSCFG" 64606 "HVESSHIST" 64653 "PII" 64701 "A1SCRSI2" 64782 "AT1OGC2" 64784 "AT1IGC2" 64839 "TML" 64879 "EEC8" 64896 "DM28" 64905 "VDS2" 64906 "J2012" 64912 "AETC" 64920 "AT1HI1" 64949 "DM23" 64950 "DM24" 64951 "DM25" 64952 "DM26" 64953 "TPRI" 64965 "ECUID" 64981 "EEC5" 65039 "LC" 65099 "TCFG2" 65109 "GFD" 65127 "CCC" 65131 "DI" 65136 "CVW" 65144 "TP1" 65145 "TP2" 65146 "TP3" 65195 "ETC6" 65196 "EBC4" 65199 "GFC" 65201 "EH" 65202 "GFI1" 65203 "LFI1" 65208 "GTFI" 65212 "CBI" 65214 "EEC4" 65216 "SERV" 65219 "ETC5" 65221 "ETC4" 65223 "ETC3" 65227 "DM02" 65228 "DM03" 65229 "DM04" 65230 "DM05" 65231 "DM06" 65234 "DM10" 65235 "DM11" 65236 "DM12" 65242 "SOFT" 65244 "IO" 65248 "VD" 65250 "TCFG" 65253 "HOURS" 65254 "TD" 65255 "VH" 65256 "VDS" 65257 "LFC1" 65258 "VW" 65259 "CI" 65260 "VI" 65261 "CCSS" 65284 "PB_DriversConsentOnPersonalData" 65340 "PB_HVESSCFG" 65376 "VehCfg" 65413 "PB_3CT" 65482 "PB_ID1" 65484 "PB_VNS" 65502 "Av2" 65520 "SCh" 65521 "DIS" 65524 "PB_IVA" ;
VAL_ 2565406471 Pgn_Nack_E8FF07 37120 "VLSI1" 40448 "DM29" 41216 "DM33" 41728 "DM31" 41984 "DM30" 47360 "PLLT (Plan List Lifetime)" 47872 "PLD (Plan List Distance)" 49408 "DM21" 49664 "DM20" 49920 "DM22" 53504 "MaintBcIc" 54016 "DM19" 60928 "ACL" 61184 "STOD" 64341 "HVESP3HIST" 64342 "HVESP3CFG" 64343 "HVESP2HIST" 64344 "HVESP2CFG" 64345 "HVESP1HIST" 64346 "HVESP1CFG" 64529 "TGFI" 64579 "TCSI" 64582 "TSIS" 64583 "MTI" 64605 "HVESSCFG" 64606 "HVESSHIST" 64653 "PII" 64701 "A1SCRSI2" 64782 "AT1OGC2" 64784 "AT1IGC2" 64839 "TML" 64879 "EEC8" 64896 "DM28" 64905 "VDS2" 64906 "J2012" 64912 "AETC" 64920 "AT1HI1" 64949 "DM23" 64950 "DM24" 64951 "DM25" 64952 "DM26" 64953 "TPRI" 64965 "ECUID" 64981 "EEC5" 65039 "LC" 65099 "TCFG2" 65109 "GFD" 65127 "CCC" 65131 "DI" 65136 "CVW" 65144 "TP1" 65145 "TP2" 65146 "TP3" 65195 "ETC6" 65196 "EBC4" 65199 "GFC" 65201 "EH" 65202 "GFI1" 65203 "LFI1" 65208 "GTFI" 65212 "CBI" 65214 "EEC4" 65216 "SERV" 65219 "ETC5" 65221 "ETC4" 65223 "ETC3" 65227 "DM02" 65228 "DM03" 65229 "DM04" 65230 "DM05" 65231 "DM06" 65234 "DM10" 65235 "DM11" 65236 "DM12" 65242 "SOFT" 65244 "IO" 65248 "VD" 65250 "TCFG" 65253 "HOURS" 65254 "TD" 65255 "VH" 65256 "VDS" 65257 "LFC1" 65258 "VW" 65259 "CI" 65260 "VI" 65261 "CCSS" 65284 "PB_DriversConsentOnPersonalData" 65340 "PB_HVESSCFG" 65376 "VehCfg" 65413 "PB_3CT" 65482 "PB_ID1" 65484 "PB_VNS" 65502 "Av2" 65520 "SCh" 65521 "DIS" 65524 "PB_IVA" ;
VAL_ 2565406471 Pgn_Ad_E8FF07 37120 "VLSI1" 40448 "DM29" 41216 "DM33" 41728 "DM31" 41984 "DM30" 47360 "PLLT (Plan List Lifetime)" 47872 "PLD (Plan List Distance)" 49408 "DM21" 49664 "DM20" 49920 "DM22" 53504 "MaintBcIc" 54016 "DM19" 60928 "ACL" 61184 "STOD" 64341 "HVESP3HIST" 64342 "HVESP3CFG" 64343 "HVESP2HIST" 64344 "HVESP2CFG" 64345 "HVESP1HIST" 64346 "HVESP1CFG" 64529 "TGFI" 64579 "TCSI" 64582 "TSIS" 64583 "MTI" 64605 "HVESSCFG" 64606 "HVESSHIST" 64653 "PII" 64701 "A1SCRSI2" 64782 "AT1OGC2" 64784 "AT1IGC2" 64839 "TML" 64879 "EEC8" 64896 "DM28" 64905 "VDS2" 64906 "J2012" 64912 "AETC" 64920 "AT1HI1" 64949 "DM23" 64950 "DM24" 64951 "DM25" 64952 "DM26" 64953 "TPRI" 64965 "ECUID" 64981 "EEC5" 65039 "LC" 65099 "TCFG2" 65109 "GFD" 65127 "CCC" 65131 "DI" 65136 "CVW" 65144 "TP1" 65145 "TP2" 65146 "TP3" 65195 "ETC6" 65196 "EBC4" 65199 "GFC" 65201 "EH" 65202 "GFI1" 65203 "LFI1" 65208 "GTFI" 65212 "CBI" 65214 "EEC4" 65216 "SERV" 65219 "ETC5" 65221 "ETC4" 65223 "ETC3" 65227 "DM02" 65228 "DM03" 65229 "DM04" 65230 "DM05" 65231 "DM06" 65234 "DM10" 65235 "DM11" 65236 "DM12" 65242 "SOFT" 65244 "IO" 65248 "VD" 65250 "TCFG" 65253 "HOURS" 65254 "TD" 65255 "VH" 65256 "VDS" 65257 "LFC1" 65258 "VW" 65259 "CI" 65260 "VI" 65261 "CCSS" 65284 "PB_DriversConsentOnPersonalData" 65340 "PB_HVESSCFG" 65376 "VehCfg" 65413 "PB_3CT" 65482 "PB_ID1" 65484 "PB_VNS" 65502 "Av2" 65520 "SCh" 65521 "DIS" 65524 "PB_IVA" ;
VAL_ 2565406471 Pgn_Busy_E8FF07 37120 "VLSI1" 40448 "DM29" 41216 "DM33" 41728 "DM31" 41984 "DM30" 47360 "PLLT (Plan List Lifetime)" 47872 "PLD (Plan List Distance)" 49408 "DM21" 49664 "DM20" 49920 "DM22" 53504 "MaintBcIc" 54016 "DM19" 60928 "ACL" 61184 "STOD" 64341 "HVESP3HIST" 64342 "HVESP3CFG" 64343 "HVESP2HIST" 64344 "HVESP2CFG" 64345 "HVESP1HIST" 64346 "HVESP1CFG" 64529 "TGFI" 64579 "TCSI" 64582 "TSIS" 64583 "MTI" 64605 "HVESSCFG" 64606 "HVESSHIST" 64653 "PII" 64701 "A1SCRSI2" 64782 "AT1OGC2" 64784 "AT1IGC2" 64839 "TML" 64879 "EEC8" 64896 "DM28" 64905 "VDS2" 64906 "J2012" 64912 "AETC" 64920 "AT1HI1" 64949 "DM23" 64950 "DM24" 64951 "DM25" 64952 "DM26" 64953 "TPRI" 64965 "ECUID" 64981 "EEC5" 65039 "LC" 65099 "TCFG2" 65109 "GFD" 65127 "CCC" 65131 "DI" 65136 "CVW" 65144 "TP1" 65145 "TP2" 65146 "TP3" 65195 "ETC6" 65196 "EBC4" 65199 "GFC" 65201 "EH" 65202 "GFI1" 65203 "LFI1" 65208 "GTFI" 65212 "CBI" 65214 "EEC4" 65216 "SERV" 65219 "ETC5" 65221 "ETC4" 65223 "ETC3" 65227 "DM02" 65228 "DM03" 65229 "DM04" 65230 "DM05" 65231 "DM06" 65234 "DM10" 65235 "DM11" 65236 "DM12" 65242 "SOFT" 65244 "IO" 65248 "VD" 65250 "TCFG" 65253 "HOURS" 65254 "TD" 65255 "VH" 65256 "VDS" 65257 "LFC1" 65258 "VW" 65259 "CI" 65260 "VI" 65261 "CCSS" 65284 "PB_DriversConsentOnPersonalData" 65340 "PB_HVESSCFG" 65376 "VehCfg" 65413 "PB_3CT" 65482 "PB_ID1" 65484 "PB_VNS" 65502 "Av2" 65520 "SCh" 65521 "DIS" 65524 "PB_IVA" ;
VAL_ 2565406490 Pgn_Ack_E8FF1A 37120 "VLSI1" 40448 "DM29" 41216 "DM33" 41728 "DM31" 41984 "DM30" 47360 "PLLT (Plan List Lifetime)" 47872 "PLD (Plan List Distance)" 49408 "DM21" 49664 "DM20" 49920 "DM22" 53504 "MaintBcIc" 54016 "DM19" 60928 "ACL" 61184 "STOD" 64341 "HVESP3HIST" 64342 "HVESP3CFG" 64343 "HVESP2HIST" 64344 "HVESP2CFG" 64345 "HVESP1HIST" 64346 "HVESP1CFG" 64529 "TGFI" 64579 "TCSI" 64582 "TSIS" 64583 "MTI" 64605 "HVESSCFG" 64606 "HVESSHIST" 64653 "PII" 64701 "A1SCRSI2" 64782 "AT1OGC2" 64784 "AT1IGC2" 64839 "TML" 64879 "EEC8" 64896 "DM28" 64905 "VDS2" 64906 "J2012" 64912 "AETC" 64920 "AT1HI1" 64949 "DM23" 64950 "DM24" 64951 "DM25" 64952 "DM26" 64953 "TPRI" 64965 "ECUID" 64981 "EEC5" 65039 "LC" 65099 "TCFG2" 65109 "GFD" 65127 "CCC" 65131 "DI" 65136 "CVW" 65144 "TP1" 65145 "TP2" 65146 "TP3" 65195 "ETC6" 65196 "EBC4" 65199 "GFC" 65201 "EH" 65202 "GFI1" 65203 "LFI1" 65208 "GTFI" 65212 "CBI" 65214 "EEC4" 65216 "SERV" 65219 "ETC5" 65221 "ETC4" 65223 "ETC3" 65227 "DM02" 65228 "DM03" 65229 "DM04" 65230 "DM05" 65231 "DM06" 65234 "DM10" 65235 "DM11" 65236 "DM12" 65242 "SOFT" 65244 "IO" 65248 "VD" 65250 "TCFG" 65253 "HOURS" 65254 "TD" 65255 "VH" 65256 "VDS" 65257 "LFC1" 65258 "VW" 65259 "CI" 65260 "VI" 65261 "CCSS" 65284 "PB_DriversConsentOnPersonalData" 65340 "PB_HVESSCFG" 65376 "VehCfg" 65413 "PB_3CT" 65482 "PB_ID1" 65484 "PB_VNS" 65502 "Av2" 65520 "SCh" 65521 "DIS" 65524 "PB_IVA" ;
VAL_ 2565406490 Pgn_Nack_E8FF1A 37120 "VLSI1" 40448 "DM29" 41216 "DM33" 41728 "DM31" 41984 "DM30" 47360 "PLLT (Plan List Lifetime)" 47872 "PLD (Plan List Distance)" 49408 "DM21" 49664 "DM20" 49920 "DM22" 53504 "MaintBcIc" 54016 "DM19" 60928 "ACL" 61184 "STOD" 64341 "HVESP3HIST" 64342 "HVESP3CFG" 64343 "HVESP2HIST" 64344 "HVESP2CFG" 64345 "HVESP1HIST" 64346 "HVESP1CFG" 64529 "TGFI" 64579 "TCSI" 64582 "TSIS" 64583 "MTI" 64605 "HVESSCFG" 64606 "HVESSHIST" 64653 "PII" 64701 "A1SCRSI2" 64782 "AT1OGC2" 64784 "AT1IGC2" 64839 "TML" 64879 "EEC8" 64896 "DM28" 64905 "VDS2" 64906 "J2012" 64912 "AETC" 64920 "AT1HI1" 64949 "DM23" 64950 "DM24" 64951 "DM25" 64952 "DM26" 64953 "TPRI" 64965 "ECUID" 64981 "EEC5" 65039 "LC" 65099 "TCFG2" 65109 "GFD" 65127 "CCC" 65131 "DI" 65136 "CVW" 65144 "TP1" 65145 "TP2" 65146 "TP3" 65195 "ETC6" 65196 "EBC4" 65199 "GFC" 65201 "EH" 65202 "GFI1" 65203 "LFI1" 65208 "GTFI" 65212 "CBI" 65214 "EEC4" 65216 "SERV" 65219 "ETC5" 65221 "ETC4" 65223 "ETC3" 65227 "DM02" 65228 "DM03" 65229 "DM04" 65230 "DM05" 65231 "DM06" 65234 "DM10" 65235 "DM11" 65236 "DM12" 65242 "SOFT" 65244 "IO" 65248 "VD" 65250 "TCFG" 65253 "HOURS" 65254 "TD" 65255 "VH" 65256 "VDS" 65257 "LFC1" 65258 "VW" 65259 "CI" 65260 "VI" 65261 "CCSS" 65284 "PB_DriversConsentOnPersonalData" 65340 "PB_HVESSCFG" 65376 "VehCfg" 65413 "PB_3CT" 65482 "PB_ID1" 65484 "PB_VNS" 65502 "Av2" 65520 "SCh" 65521 "DIS" 65524 "PB_IVA" ;
VAL_ 2565406490 Pgn_Ad_E8FF1A 37120 "VLSI1" 40448 "DM29" 41216 "DM33" 41728 "DM31" 41984 "DM30" 47360 "PLLT (Plan List Lifetime)" 47872 "PLD (Plan List Distance)" 49408 "DM21" 49664 "DM20" 49920 "DM22" 53504 "MaintBcIc" 54016 "DM19" 60928 "ACL" 61184 "STOD" 64341 "HVESP3HIST" 64342 "HVESP3CFG" 64343 "HVESP2HIST" 64344 "HVESP2CFG" 64345 "HVESP1HIST" 64346 "HVESP1CFG" 64529 "TGFI" 64579 "TCSI" 64582 "TSIS" 64583 "MTI" 64605 "HVESSCFG" 64606 "HVESSHIST" 64653 "PII" 64701 "A1SCRSI2" 64782 "AT1OGC2" 64784 "AT1IGC2" 64839 "TML" 64879 "EEC8" 64896 "DM28" 64905 "VDS2" 64906 "J2012" 64912 "AETC" 64920 "AT1HI1" 64949 "DM23" 64950 "DM24" 64951 "DM25" 64952 "DM26" 64953 "TPRI" 64965 "ECUID" 64981 "EEC5" 65039 "LC" 65099 "TCFG2" 65109 "GFD" 65127 "CCC" 65131 "DI" 65136 "CVW" 65144 "TP1" 65145 "TP2" 65146 "TP3" 65195 "ETC6" 65196 "EBC4" 65199 "GFC" 65201 "EH" 65202 "GFI1" 65203 "LFI1" 65208 "GTFI" 65212 "CBI" 65214 "EEC4" 65216 "SERV" 65219 "ETC5" 65221 "ETC4" 65223 "ETC3" 65227 "DM02" 65228 "DM03" 65229 "DM04" 65230 "DM05" 65231 "DM06" 65234 "DM10" 65235 "DM11" 65236 "DM12" 65242 "SOFT" 65244 "IO" 65248 "VD" 65250 "TCFG" 65253 "HOURS" 65254 "TD" 65255 "VH" 65256 "VDS" 65257 "LFC1" 65258 "VW" 65259 "CI" 65260 "VI" 65261 "CCSS" 65284 "PB_DriversConsentOnPersonalData" 65340 "PB_HVESSCFG" 65376 "VehCfg" 65413 "PB_3CT" 65482 "PB_ID1" 65484 "PB_VNS" 65502 "Av2" 65520 "SCh" 65521 "DIS" 65524 "PB_IVA" ;
VAL_ 2565406490 Pgn_Busy_E8FF1A 37120 "VLSI1" 40448 "DM29" 41216 "DM33" 41728 "DM31" 41984 "DM30" 47360 "PLLT (Plan List Lifetime)" 47872 "PLD (Plan List Distance)" 49408 "DM21" 49664 "DM20" 49920 "DM22" 53504 "MaintBcIc" 54016 "DM19" 60928 "ACL" 61184 "STOD" 64341 "HVESP3HIST" 64342 "HVESP3CFG" 64343 "HVESP2HIST" 64344 "HVESP2CFG" 64345 "HVESP1HIST" 64346 "HVESP1CFG" 64529 "TGFI" 64579 "TCSI" 64582 "TSIS" 64583 "MTI" 64605 "HVESSCFG" 64606 "HVESSHIST" 64653 "PII" 64701 "A1SCRSI2" 64782 "AT1OGC2" 64784 "AT1IGC2" 64839 "TML" 64879 "EEC8" 64896 "DM28" 64905 "VDS2" 64906 "J2012" 64912 "AETC" 64920 "AT1HI1" 64949 "DM23" 64950 "DM24" 64951 "DM25" 64952 "DM26" 64953 "TPRI" 64965 "ECUID" 64981 "EEC5" 65039 "LC" 65099 "TCFG2" 65109 "GFD" 65127 "CCC" 65131 "DI" 65136 "CVW" 65144 "TP1" 65145 "TP2" 65146 "TP3" 65195 "ETC6" 65196 "EBC4" 65199 "GFC" 65201 "EH" 65202 "GFI1" 65203 "LFI1" 65208 "GTFI" 65212 "CBI" 65214 "EEC4" 65216 "SERV" 65219 "ETC5" 65221 "ETC4" 65223 "ETC3" 65227 "DM02" 65228 "DM03" 65229 "DM04" 65230 "DM05" 65231 "DM06" 65234 "DM10" 65235 "DM11" 65236 "DM12" 65242 "SOFT" 65244 "IO" 65248 "VD" 65250 "TCFG" 65253 "HOURS" 65254 "TD" 65255 "VH" 65256 "VDS" 65257 "LFC1" 65258 "VW" 65259 "CI" 65260 "VI" 65261 "CCSS" 65284 "PB_DriversConsentOnPersonalData" 65340 "PB_HVESSCFG" 65376 "VehCfg" 65413 "PB_3CT" 65482 "PB_ID1" 65484 "PB_VNS" 65502 "Av2" 65520 "SCh" 65521 "DIS" 65524 "PB_IVA" ;
VAL_ 2565406493 Pgn_Ack_E8FF1D 37120 "VLSI1" 40448 "DM29" 41216 "DM33" 41728 "DM31" 41984 "DM30" 47360 "PLLT (Plan List Lifetime)" 47872 "PLD (Plan List Distance)" 49408 "DM21" 49664 "DM20" 49920 "DM22" 53504 "MaintBcIc" 54016 "DM19" 60928 "ACL" 61184 "STOD" 64341 "HVESP3HIST" 64342 "HVESP3CFG" 64343 "HVESP2HIST" 64344 "HVESP2CFG" 64345 "HVESP1HIST" 64346 "HVESP1CFG" 64529 "TGFI" 64579 "TCSI" 64582 "TSIS" 64583 "MTI" 64605 "HVESSCFG" 64606 "HVESSHIST" 64653 "PII" 64701 "A1SCRSI2" 64782 "AT1OGC2" 64784 "AT1IGC2" 64839 "TML" 64879 "EEC8" 64896 "DM28" 64905 "VDS2" 64906 "J2012" 64912 "AETC" 64920 "AT1HI1" 64949 "DM23" 64950 "DM24" 64951 "DM25" 64952 "DM26" 64953 "TPRI" 64965 "ECUID" 64981 "EEC5" 65039 "LC" 65099 "TCFG2" 65109 "GFD" 65127 "CCC" 65131 "DI" 65136 "CVW" 65144 "TP1" 65145 "TP2" 65146 "TP3" 65195 "ETC6" 65196 "EBC4" 65199 "GFC" 65201 "EH" 65202 "GFI1" 65203 "LFI1" 65208 "GTFI" 65212 "CBI" 65214 "EEC4" 65216 "SERV" 65219 "ETC5" 65221 "ETC4" 65223 "ETC3" 65227 "DM02" 65228 "DM03" 65229 "DM04" 65230 "DM05" 65231 "DM06" 65234 "DM10" 65235 "DM11" 65236 "DM12" 65242 "SOFT" 65244 "IO" 65248 "VD" 65250 "TCFG" 65253 "HOURS" 65254 "TD" 65255 "VH" 65256 "VDS" 65257 "LFC1" 65258 "VW" 65259 "CI" 65260 "VI" 65261 "CCSS" 65284 "PB_DriversConsentOnPersonalData" 65340 "PB_HVESSCFG" 65376 "VehCfg" 65413 "PB_3CT" 65482 "PB_ID1" 65484 "PB_VNS" 65502 "Av2" 65520 "SCh" 65521 "DIS" 65524 "PB_IVA" ;
VAL_ 2565406493 Pgn_Nack_E8FF1D 37120 "VLSI1" 40448 "DM29" 41216 "DM33" 41728 "DM31" 41984 "DM30" 47360 "PLLT (Plan List Lifetime)" 47872 "PLD (Plan List Distance)" 49408 "DM21" 49664 "DM20" 49920 "DM22" 53504 "MaintBcIc" 54016 "DM19" 60928 "ACL" 61184 "STOD" 64341 "HVESP3HIST" 64342 "HVESP3CFG" 64343 "HVESP2HIST" 64344 "HVESP2CFG" 64345 "HVESP1HIST" 64346 "HVESP1CFG" 64529 "TGFI" 64579 "TCSI" 64582 "TSIS" 64583 "MTI" 64605 "HVESSCFG" 64606 "HVESSHIST" 64653 "PII" 64701 "A1SCRSI2" 64782 "AT1OGC2" 64784 "AT1IGC2" 64839 "TML" 64879 "EEC8" 64896 "DM28" 64905 "VDS2" 64906 "J2012" 64912 "AETC" 64920 "AT1HI1" 64949 "DM23" 64950 "DM24" 64951 "DM25" 64952 "DM26" 64953 "TPRI" 64965 "ECUID" 64981 "EEC5" 65039 "LC" 65099 "TCFG2" 65109 "GFD" 65127 "CCC" 65131 "DI" 65136 "CVW" 65144 "TP1" 65145 "TP2" 65146 "TP3" 65195 "ETC6" 65196 "EBC4" 65199 "GFC" 65201 "EH" 65202 "GFI1" 65203 "LFI1" 65208 "GTFI" 65212 "CBI" 65214 "EEC4" 65216 "SERV" 65219 "ETC5" 65221 "ETC4" 65223 "ETC3" 65227 "DM02" 65228 "DM03" 65229 "DM04" 65230 "DM05" 65231 "DM06" 65234 "DM10" 65235 "DM11" 65236 "DM12" 65242 "SOFT" 65244 "IO" 65248 "VD" 65250 "TCFG" 65253 "HOURS" 65254 "TD" 65255 "VH" 65256 "VDS" 65257 "LFC1" 65258 "VW" 65259 "CI" 65260 "VI" 65261 "CCSS" 65284 "PB_DriversConsentOnPersonalData" 65340 "PB_HVESSCFG" 65376 "VehCfg" 65413 "PB_3CT" 65482 "PB_ID1" 65484 "PB_VNS" 65502 "Av2" 65520 "SCh" 65521 "DIS" 65524 "PB_IVA" ;
VAL_ 2565406493 Pgn_Ad_E8FF1D 37120 "VLSI1" 40448 "DM29" 41216 "DM33" 41728 "DM31" 41984 "DM30" 47360 "PLLT (Plan List Lifetime)" 47872 "PLD (Plan List Distance)" 49408 "DM21" 49664 "DM20" 49920 "DM22" 53504 "MaintBcIc" 54016 "DM19" 60928 "ACL" 61184 "STOD" 64341 "HVESP3HIST" 64342 "HVESP3CFG" 64343 "HVESP2HIST" 64344 "HVESP2CFG" 64345 "HVESP1HIST" 64346 "HVESP1CFG" 64529 "TGFI" 64579 "TCSI" 64582 "TSIS" 64583 "MTI" 64605 "HVESSCFG" 64606 "HVESSHIST" 64653 "PII" 64701 "A1SCRSI2" 64782 "AT1OGC2" 64784 "AT1IGC2" 64839 "TML" 64879 "EEC8" 64896 "DM28" 64905 "VDS2" 64906 "J2012" 64912 "AETC" 64920 "AT1HI1" 64949 "DM23" 64950 "DM24" 64951 "DM25" 64952 "DM26" 64953 "TPRI" 64965 "ECUID" 64981 "EEC5" 65039 "LC" 65099 "TCFG2" 65109 "GFD" 65127 "CCC" 65131 "DI" 65136 "CVW" 65144 "TP1" 65145 "TP2" 65146 "TP3" 65195 "ETC6" 65196 "EBC4" 65199 "GFC" 65201 "EH" 65202 "GFI1" 65203 "LFI1" 65208 "GTFI" 65212 "CBI" 65214 "EEC4" 65216 "SERV" 65219 "ETC5" 65221 "ETC4" 65223 "ETC3" 65227 "DM02" 65228 "DM03" 65229 "DM04" 65230 "DM05" 65231 "DM06" 65234 "DM10" 65235 "DM11" 65236 "DM12" 65242 "SOFT" 65244 "IO" 65248 "VD" 65250 "TCFG" 65253 "HOURS" 65254 "TD" 65255 "VH" 65256 "VDS" 65257 "LFC1" 65258 "VW" 65259 "CI" 65260 "VI" 65261 "CCSS" 65284 "PB_DriversConsentOnPersonalData" 65340 "PB_HVESSCFG" 65376 "VehCfg" 65413 "PB_3CT" 65482 "PB_ID1" 65484 "PB_VNS" 65502 "Av2" 65520 "SCh" 65521 "DIS" 65524 "PB_IVA" ;
VAL_ 2565406493 Pgn_Busy_E8FF1D 37120 "VLSI1" 40448 "DM29" 41216 "DM33" 41728 "DM31" 41984 "DM30" 47360 "PLLT (Plan List Lifetime)" 47872 "PLD (Plan List Distance)" 49408 "DM21" 49664 "DM20" 49920 "DM22" 53504 "MaintBcIc" 54016 "DM19" 60928 "ACL" 61184 "STOD" 64341 "HVESP3HIST" 64342 "HVESP3CFG" 64343 "HVESP2HIST" 64344 "HVESP2CFG" 64345 "HVESP1HIST" 64346 "HVESP1CFG" 64529 "TGFI" 64579 "TCSI" 64582 "TSIS" 64583 "MTI" 64605 "HVESSCFG" 64606 "HVESSHIST" 64653 "PII" 64701 "A1SCRSI2" 64782 "AT1OGC2" 64784 "AT1IGC2" 64839 "TML" 64879 "EEC8" 64896 "DM28" 64905 "VDS2" 64906 "J2012" 64912 "AETC" 64920 "AT1HI1" 64949 "DM23" 64950 "DM24" 64951 "DM25" 64952 "DM26" 64953 "TPRI" 64965 "ECUID" 64981 "EEC5" 65039 "LC" 65099 "TCFG2" 65109 "GFD" 65127 "CCC" 65131 "DI" 65136 "CVW" 65144 "TP1" 65145 "TP2" 65146 "TP3" 65195 "ETC6" 65196 "EBC4" 65199 "GFC" 65201 "EH" 65202 "GFI1" 65203 "LFI1" 65208 "GTFI" 65212 "CBI" 65214 "EEC4" 65216 "SERV" 65219 "ETC5" 65221 "ETC4" 65223 "ETC3" 65227 "DM02" 65228 "DM03" 65229 "DM04" 65230 "DM05" 65231 "DM06" 65234 "DM10" 65235 "DM11" 65236 "DM12" 65242 "SOFT" 65244 "IO" 65248 "VD" 65250 "TCFG" 65253 "HOURS" 65254 "TD" 65255 "VH" 65256 "VDS" 65257 "LFC1" 65258 "VW" 65259 "CI" 65260 "VI" 65261 "CCSS" 65284 "PB_DriversConsentOnPersonalData" 65340 "PB_HVESSCFG" 65376 "VehCfg" 65413 "PB_3CT" 65482 "PB_ID1" 65484 "PB_VNS" 65502 "Av2" 65520 "SCh" 65521 "DIS" 65524 "PB_IVA" ;
VAL_ 2565406497 Pgn_Ack_E8FF21 37120 "VLSI1" 40448 "DM29" 41216 "DM33" 41728 "DM31" 41984 "DM30" 47360 "PLLT (Plan List Lifetime)" 47872 "PLD (Plan List Distance)" 49408 "DM21" 49664 "DM20" 49920 "DM22" 53504 "MaintBcIc" 54016 "DM19" 60928 "ACL" 61184 "STOD" 64341 "HVESP3HIST" 64342 "HVESP3CFG" 64343 "HVESP2HIST" 64344 "HVESP2CFG" 64345 "HVESP1HIST" 64346 "HVESP1CFG" 64529 "TGFI" 64579 "TCSI" 64582 "TSIS" 64583 "MTI" 64605 "HVESSCFG" 64606 "HVESSHIST" 64653 "PII" 64701 "A1SCRSI2" 64782 "AT1OGC2" 64784 "AT1IGC2" 64839 "TML" 64879 "EEC8" 64896 "DM28" 64905 "VDS2" 64906 "J2012" 64912 "AETC" 64920 "AT1HI1" 64949 "DM23" 64950 "DM24" 64951 "DM25" 64952 "DM26" 64953 "TPRI" 64965 "ECUID" 64981 "EEC5" 65039 "LC" 65099 "TCFG2" 65109 "GFD" 65127 "CCC" 65131 "DI" 65136 "CVW" 65144 "TP1" 65145 "TP2" 65146 "TP3" 65195 "ETC6" 65196 "EBC4" 65199 "GFC" 65201 "EH" 65202 "GFI1" 65203 "LFI1" 65208 "GTFI" 65212 "CBI" 65214 "EEC4" 65216 "SERV" 65219 "ETC5" 65221 "ETC4" 65223 "ETC3" 65227 "DM02" 65228 "DM03" 65229 "DM04" 65230 "DM05" 65231 "DM06" 65234 "DM10" 65235 "DM11" 65236 "DM12" 65242 "SOFT" 65244 "IO" 65248 "VD" 65250 "TCFG" 65253 "HOURS" 65254 "TD" 65255 "VH" 65256 "VDS" 65257 "LFC1" 65258 "VW" 65259 "CI" 65260 "VI" 65261 "CCSS" 65284 "PB_DriversConsentOnPersonalData" 65340 "PB_HVESSCFG" 65376 "VehCfg" 65413 "PB_3CT" 65482 "PB_ID1" 65484 "PB_VNS" 65502 "Av2" 65520 "SCh" 65521 "DIS" 65524 "PB_IVA" ;
VAL_ 2565406497 Pgn_Nack_E8FF21 37120 "VLSI1" 40448 "DM29" 41216 "DM33" 41728 "DM31" 41984 "DM30" 47360 "PLLT (Plan List Lifetime)" 47872 "PLD (Plan List Distance)" 49408 "DM21" 49664 "DM20" 49920 "DM22" 53504 "MaintBcIc" 54016 "DM19" 60928 "ACL" 61184 "STOD" 64341 "HVESP3HIST" 64342 "HVESP3CFG" 64343 "HVESP2HIST" 64344 "HVESP2CFG" 64345 "HVESP1HIST" 64346 "HVESP1CFG" 64529 "TGFI" 64579 "TCSI" 64582 "TSIS" 64583 "MTI" 64605 "HVESSCFG" 64606 "HVESSHIST" 64653 "PII" 64701 "A1SCRSI2" 64782 "AT1OGC2" 64784 "AT1IGC2" 64839 "TML" 64879 "EEC8" 64896 "DM28" 64905 "VDS2" 64906 "J2012" 64912 "AETC" 64920 "AT1HI1" 64949 "DM23" 64950 "DM24" 64951 "DM25" 64952 "DM26" 64953 "TPRI" 64965 "ECUID" 64981 "EEC5" 65039 "LC" 65099 "TCFG2" 65109 "GFD" 65127 "CCC" 65131 "DI" 65136 "CVW" 65144 "TP1" 65145 "TP2" 65146 "TP3" 65195 "ETC6" 65196 "EBC4" 65199 "GFC" 65201 "EH" 65202 "GFI1" 65203 "LFI1" 65208 "GTFI" 65212 "CBI" 65214 "EEC4" 65216 "SERV" 65219 "ETC5" 65221 "ETC4" 65223 "ETC3" 65227 "DM02" 65228 "DM03" 65229 "DM04" 65230 "DM05" 65231 "DM06" 65234 "DM10" 65235 "DM11" 65236 "DM12" 65242 "SOFT" 65244 "IO" 65248 "VD" 65250 "TCFG" 65253 "HOURS" 65254 "TD" 65255 "VH" 65256 "VDS" 65257 "LFC1" 65258 "VW" 65259 "CI" 65260 "VI" 65261 "CCSS" 65284 "PB_DriversConsentOnPersonalData" 65340 "PB_HVESSCFG" 65376 "VehCfg" 65413 "PB_3CT" 65482 "PB_ID1" 65484 "PB_VNS" 65502 "Av2" 65520 "SCh" 65521 "DIS" 65524 "PB_IVA" ;
VAL_ 2565406497 Pgn_Ad_E8FF21 37120 "VLSI1" 40448 "DM29" 41216 "DM33" 41728 "DM31" 41984 "DM30" 47360 "PLLT (Plan List Lifetime)" 47872 "PLD (Plan List Distance)" 49408 "DM21" 49664 "DM20" 49920 "DM22" 53504 "MaintBcIc" 54016 "DM19" 60928 "ACL" 61184 "STOD" 64341 "HVESP3HIST" 64342 "HVESP3CFG" 64343 "HVESP2HIST" 64344 "HVESP2CFG" 64345 "HVESP1HIST" 64346 "HVESP1CFG" 64529 "TGFI" 64579 "TCSI" 64582 "TSIS" 64583 "MTI" 64605 "HVESSCFG" 64606 "HVESSHIST" 64653 "PII" 64701 "A1SCRSI2" 64782 "AT1OGC2" 64784 "AT1IGC2" 64839 "TML" 64879 "EEC8" 64896 "DM28" 64905 "VDS2" 64906 "J2012" 64912 "AETC" 64920 "AT1HI1" 64949 "DM23" 64950 "DM24" 64951 "DM25" 64952 "DM26" 64953 "TPRI" 64965 "ECUID" 64981 "EEC5" 65039 "LC" 65099 "TCFG2" 65109 "GFD" 65127 "CCC" 65131 "DI" 65136 "CVW" 65144 "TP1" 65145 "TP2" 65146 "TP3" 65195 "ETC6" 65196 "EBC4" 65199 "GFC" 65201 "EH" 65202 "GFI1" 65203 "LFI1" 65208 "GTFI" 65212 "CBI" 65214 "EEC4" 65216 "SERV" 65219 "ETC5" 65221 "ETC4" 65223 "ETC3" 65227 "DM02" 65228 "DM03" 65229 "DM04" 65230 "DM05" 65231 "DM06" 65234 "DM10" 65235 "DM11" 65236 "DM12" 65242 "SOFT" 65244 "IO" 65248 "VD" 65250 "TCFG" 65253 "HOURS" 65254 "TD" 65255 "VH" 65256 "VDS" 65257 "LFC1" 65258 "VW" 65259 "CI" 65260 "VI" 65261 "CCSS" 65284 "PB_DriversConsentOnPersonalData" 65340 "PB_HVESSCFG" 65376 "VehCfg" 65413 "PB_3CT" 65482 "PB_ID1" 65484 "PB_VNS" 65502 "Av2" 65520 "SCh" 65521 "DIS" 65524 "PB_IVA" ;
VAL_ 2565406497 Pgn_Busy_E8FF21 37120 "VLSI1" 40448 "DM29" 41216 "DM33" 41728 "DM31" 41984 "DM30" 47360 "PLLT (Plan List Lifetime)" 47872 "PLD (Plan List Distance)" 49408 "DM21" 49664 "DM20" 49920 "DM22" 53504 "MaintBcIc" 54016 "DM19" 60928 "ACL" 61184 "STOD" 64341 "HVESP3HIST" 64342 "HVESP3CFG" 64343 "HVESP2HIST" 64344 "HVESP2CFG" 64345 "HVESP1HIST" 64346 "HVESP1CFG" 64529 "TGFI" 64579 "TCSI" 64582 "TSIS" 64583 "MTI" 64605 "HVESSCFG" 64606 "HVESSHIST" 64653 "PII" 64701 "A1SCRSI2" 64782 "AT1OGC2" 64784 "AT1IGC2" 64839 "TML" 64879 "EEC8" 64896 "DM28" 64905 "VDS2" 64906 "J2012" 64912 "AETC" 64920 "AT1HI1" 64949 "DM23" 64950 "DM24" 64951 "DM25" 64952 "DM26" 64953 "TPRI" 64965 "ECUID" 64981 "EEC5" 65039 "LC" 65099 "TCFG2" 65109 "GFD" 65127 "CCC" 65131 "DI" 65136 "CVW" 65144 "TP1" 65145 "TP2" 65146 "TP3" 65195 "ETC6" 65196 "EBC4" 65199 "GFC" 65201 "EH" 65202 "GFI1" 65203 "LFI1" 65208 "GTFI" 65212 "CBI" 65214 "EEC4" 65216 "SERV" 65219 "ETC5" 65221 "ETC4" 65223 "ETC3" 65227 "DM02" 65228 "DM03" 65229 "DM04" 65230 "DM05" 65231 "DM06" 65234 "DM10" 65235 "DM11" 65236 "DM12" 65242 "SOFT" 65244 "IO" 65248 "VD" 65250 "TCFG" 65253 "HOURS" 65254 "TD" 65255 "VH" 65256 "VDS" 65257 "LFC1" 65258 "VW" 65259 "CI" 65260 "VI" 65261 "CCSS" 65284 "PB_DriversConsentOnPersonalData" 65340 "PB_HVESSCFG" 65376 "VehCfg" 65413 "PB_3CT" 65482 "PB_ID1" 65484 "PB_VNS" 65502 "Av2" 65520 "SCh" 65521 "DIS" 65524 "PB_IVA" ;
VAL_ 2565406500 Pgn_Ack_E8FF24 37120 "VLSI1" 40448 "DM29" 41216 "DM33" 41728 "DM31" 41984 "DM30" 47360 "PLLT (Plan List Lifetime)" 47872 "PLD (Plan List Distance)" 49408 "DM21" 49664 "DM20" 49920 "DM22" 53504 "MaintBcIc" 54016 "DM19" 60928 "ACL" 61184 "STOD" 64341 "HVESP3HIST" 64342 "HVESP3CFG" 64343 "HVESP2HIST" 64344 "HVESP2CFG" 64345 "HVESP1HIST" 64346 "HVESP1CFG" 64529 "TGFI" 64579 "TCSI" 64582 "TSIS" 64583 "MTI" 64605 "HVESSCFG" 64606 "HVESSHIST" 64653 "PII" 64701 "A1SCRSI2" 64782 "AT1OGC2" 64784 "AT1IGC2" 64839 "TML" 64879 "EEC8" 64896 "DM28" 64905 "VDS2" 64906 "J2012" 64912 "AETC" 64920 "AT1HI1" 64949 "DM23" 64950 "DM24" 64951 "DM25" 64952 "DM26" 64953 "TPRI" 64965 "ECUID" 64981 "EEC5" 65039 "LC" 65099 "TCFG2" 65109 "GFD" 65127 "CCC" 65131 "DI" 65136 "CVW" 65144 "TP1" 65145 "TP2" 65146 "TP3" 65195 "ETC6" 65196 "EBC4" 65199 "GFC" 65201 "EH" 65202 "GFI1" 65203 "LFI1" 65208 "GTFI" 65212 "CBI" 65214 "EEC4" 65216 "SERV" 65219 "ETC5" 65221 "ETC4" 65223 "ETC3" 65227 "DM02" 65228 "DM03" 65229 "DM04" 65230 "DM05" 65231 "DM06" 65234 "DM10" 65235 "DM11" 65236 "DM12" 65242 "SOFT" 65244 "IO" 65248 "VD" 65250 "TCFG" 65253 "HOURS" 65254 "TD" 65255 "VH" 65256 "VDS" 65257 "LFC1" 65258 "VW" 65259 "CI" 65260 "VI" 65261 "CCSS" 65284 "PB_DriversConsentOnPersonalData" 65340 "PB_HVESSCFG" 65376 "VehCfg" 65413 "PB_3CT" 65482 "PB_ID1" 65484 "PB_VNS" 65502 "Av2" 65520 "SCh" 65521 "DIS" 65524 "PB_IVA" ;
VAL_ 2565406500 Pgn_Nack_E8FF24 37120 "VLSI1" 40448 "DM29" 41216 "DM33" 41728 "DM31" 41984 "DM30" 47360 "PLLT (Plan List Lifetime)" 47872 "PLD (Plan List Distance)" 49408 "DM21" 49664 "DM20" 49920 "DM22" 53504 "MaintBcIc" 54016 "DM19" 60928 "ACL" 61184 "STOD" 64341 "HVESP3HIST" 64342 "HVESP3CFG" 64343 "HVESP2HIST" 64344 "HVESP2CFG" 64345 "HVESP1HIST" 64346 "HVESP1CFG" 64529 "TGFI" 64579 "TCSI" 64582 "TSIS" 64583 "MTI" 64605 "HVESSCFG" 64606 "HVESSHIST" 64653 "PII" 64701 "A1SCRSI2" 64782 "AT1OGC2" 64784 "AT1IGC2" 64839 "TML" 64879 "EEC8" 64896 "DM28" 64905 "VDS2" 64906 "J2012" 64912 "AETC" 64920 "AT1HI1" 64949 "DM23" 64950 "DM24" 64951 "DM25" 64952 "DM26" 64953 "TPRI" 64965 "ECUID" 64981 "EEC5" 65039 "LC" 65099 "TCFG2" 65109 "GFD" 65127 "CCC" 65131 "DI" 65136 "CVW" 65144 "TP1" 65145 "TP2" 65146 "TP3" 65195 "ETC6" 65196 "EBC4" 65199 "GFC" 65201 "EH" 65202 "GFI1" 65203 "LFI1" 65208 "GTFI" 65212 "CBI" 65214 "EEC4" 65216 "SERV" 65219 "ETC5" 65221 "ETC4" 65223 "ETC3" 65227 "DM02" 65228 "DM03" 65229 "DM04" 65230 "DM05" 65231 "DM06" 65234 "DM10" 65235 "DM11" 65236 "DM12" 65242 "SOFT" 65244 "IO" 65248 "VD" 65250 "TCFG" 65253 "HOURS" 65254 "TD" 65255 "VH" 65256 "VDS" 65257 "LFC1" 65258 "VW" 65259 "CI" 65260 "VI" 65261 "CCSS" 65284 "PB_DriversConsentOnPersonalData" 65340 "PB_HVESSCFG" 65376 "VehCfg" 65413 "PB_3CT" 65482 "PB_ID1" 65484 "PB_VNS" 65502 "Av2" 65520 "SCh" 65521 "DIS" 65524 "PB_IVA" ;
VAL_ 2565406500 Pgn_Ad_E8FF24 37120 "VLSI1" 40448 "DM29" 41216 "DM33" 41728 "DM31" 41984 "DM30" 47360 "PLLT (Plan List Lifetime)" 47872 "PLD (Plan List Distance)" 49408 "DM21" 49664 "DM20" 49920 "DM22" 53504 "MaintBcIc" 54016 "DM19" 60928 "ACL" 61184 "STOD" 64341 "HVESP3HIST" 64342 "HVESP3CFG" 64343 "HVESP2HIST" 64344 "HVESP2CFG" 64345 "HVESP1HIST" 64346 "HVESP1CFG" 64529 "TGFI" 64579 "TCSI" 64582 "TSIS" 64583 "MTI" 64605 "HVESSCFG" 64606 "HVESSHIST" 64653 "PII" 64701 "A1SCRSI2" 64782 "AT1OGC2" 64784 "AT1IGC2" 64839 "TML" 64879 "EEC8" 64896 "DM28" 64905 "VDS2" 64906 "J2012" 64912 "AETC" 64920 "AT1HI1" 64949 "DM23" 64950 "DM24" 64951 "DM25" 64952 "DM26" 64953 "TPRI" 64965 "ECUID" 64981 "EEC5" 65039 "LC" 65099 "TCFG2" 65109 "GFD" 65127 "CCC" 65131 "DI" 65136 "CVW" 65144 "TP1" 65145 "TP2" 65146 "TP3" 65195 "ETC6" 65196 "EBC4" 65199 "GFC" 65201 "EH" 65202 "GFI1" 65203 "LFI1" 65208 "GTFI" 65212 "CBI" 65214 "EEC4" 65216 "SERV" 65219 "ETC5" 65221 "ETC4" 65223 "ETC3" 65227 "DM02" 65228 "DM03" 65229 "DM04" 65230 "DM05" 65231 "DM06" 65234 "DM10" 65235 "DM11" 65236 "DM12" 65242 "SOFT" 65244 "IO" 65248 "VD" 65250 "TCFG" 65253 "HOURS" 65254 "TD" 65255 "VH" 65256 "VDS" 65257 "LFC1" 65258 "VW" 65259 "CI" 65260 "VI" 65261 "CCSS" 65284 "PB_DriversConsentOnPersonalData" 65340 "PB_HVESSCFG" 65376 "VehCfg" 65413 "PB_3CT" 65482 "PB_ID1" 65484 "PB_VNS" 65502 "Av2" 65520 "SCh" 65521 "DIS" 65524 "PB_IVA" ;
VAL_ 2565406500 Pgn_Busy_E8FF24 37120 "VLSI1" 40448 "DM29" 41216 "DM33" 41728 "DM31" 41984 "DM30" 47360 "PLLT (Plan List Lifetime)" 47872 "PLD (Plan List Distance)" 49408 "DM21" 49664 "DM20" 49920 "DM22" 53504 "MaintBcIc" 54016 "DM19" 60928 "ACL" 61184 "STOD" 64341 "HVESP3HIST" 64342 "HVESP3CFG" 64343 "HVESP2HIST" 64344 "HVESP2CFG" 64345 "HVESP1HIST" 64346 "HVESP1CFG" 64529 "TGFI" 64579 "TCSI" 64582 "TSIS" 64583 "MTI" 64605 "HVESSCFG" 64606 "HVESSHIST" 64653 "PII" 64701 "A1SCRSI2" 64782 "AT1OGC2" 64784 "AT1IGC2" 64839 "TML" 64879 "EEC8" 64896 "DM28" 64905 "VDS2" 64906 "J2012" 64912 "AETC" 64920 "AT1HI1" 64949 "DM23" 64950 "DM24" 64951 "DM25" 64952 "DM26" 64953 "TPRI" 64965 "ECUID" 64981 "EEC5" 65039 "LC" 65099 "TCFG2" 65109 "GFD" 65127 "CCC" 65131 "DI" 65136 "CVW" 65144 "TP1" 65145 "TP2" 65146 "TP3" 65195 "ETC6" 65196 "EBC4" 65199 "GFC" 65201 "EH" 65202 "GFI1" 65203 "LFI1" 65208 "GTFI" 65212 "CBI" 65214 "EEC4" 65216 "SERV" 65219 "ETC5" 65221 "ETC4" 65223 "ETC3" 65227 "DM02" 65228 "DM03" 65229 "DM04" 65230 "DM05" 65231 "DM06" 65234 "DM10" 65235 "DM11" 65236 "DM12" 65242 "SOFT" 65244 "IO" 65248 "VD" 65250 "TCFG" 65253 "HOURS" 65254 "TD" 65255 "VH" 65256 "VDS" 65257 "LFC1" 65258 "VW" 65259 "CI" 65260 "VI" 65261 "CCSS" 65284 "PB_DriversConsentOnPersonalData" 65340 "PB_HVESSCFG" 65376 "VehCfg" 65413 "PB_3CT" 65482 "PB_ID1" 65484 "PB_VNS" 65502 "Av2" 65520 "SCh" 65521 "DIS" 65524 "PB_IVA" ;
VAL_ 2565406503 Pgn_Ack_E8FF27 37120 "VLSI1" 40448 "DM29" 41216 "DM33" 41728 "DM31" 41984 "DM30" 47360 "PLLT (Plan List Lifetime)" 47872 "PLD (Plan List Distance)" 49408 "DM21" 49664 "DM20" 49920 "DM22" 53504 "MaintBcIc" 54016 "DM19" 60928 "ACL" 61184 "STOD" 64341 "HVESP3HIST" 64342 "HVESP3CFG" 64343 "HVESP2HIST" 64344 "HVESP2CFG" 64345 "HVESP1HIST" 64346 "HVESP1CFG" 64529 "TGFI" 64579 "TCSI" 64582 "TSIS" 64583 "MTI" 64605 "HVESSCFG" 64606 "HVESSHIST" 64653 "PII" 64701 "A1SCRSI2" 64782 "AT1OGC2" 64784 "AT1IGC2" 64839 "TML" 64879 "EEC8" 64896 "DM28" 64905 "VDS2" 64906 "J2012" 64912 "AETC" 64920 "AT1HI1" 64949 "DM23" 64950 "DM24" 64951 "DM25" 64952 "DM26" 64953 "TPRI" 64965 "ECUID" 64981 "EEC5" 65039 "LC" 65099 "TCFG2" 65109 "GFD" 65127 "CCC" 65131 "DI" 65136 "CVW" 65144 "TP1" 65145 "TP2" 65146 "TP3" 65195 "ETC6" 65196 "EBC4" 65199 "GFC" 65201 "EH" 65202 "GFI1" 65203 "LFI1" 65208 "GTFI" 65212 "CBI" 65214 "EEC4" 65216 "SERV" 65219 "ETC5" 65221 "ETC4" 65223 "ETC3" 65227 "DM02" 65228 "DM03" 65229 "DM04" 65230 "DM05" 65231 "DM06" 65234 "DM10" 65235 "DM11" 65236 "DM12" 65242 "SOFT" 65244 "IO" 65248 "VD" 65250 "TCFG" 65253 "HOURS" 65254 "TD" 65255 "VH" 65256 "VDS" 65257 "LFC1" 65258 "VW" 65259 "CI" 65260 "VI" 65261 "CCSS" 65284 "PB_DriversConsentOnPersonalData" 65340 "PB_HVESSCFG" 65376 "VehCfg" 65413 "PB_3CT" 65482 "PB_ID1" 65484 "PB_VNS" 65502 "Av2" 65520 "SCh" 65521 "DIS" 65524 "PB_IVA" ;
VAL_ 2565406503 Pgn_Nack_E8FF27 37120 "VLSI1" 40448 "DM29" 41216 "DM33" 41728 "DM31" 41984 "DM30" 47360 "PLLT (Plan List Lifetime)" 47872 "PLD (Plan List Distance)" 49408 "DM21" 49664 "DM20" 49920 "DM22" 53504 "MaintBcIc" 54016 "DM19" 60928 "ACL" 61184 "STOD" 64341 "HVESP3HIST" 64342 "HVESP3CFG" 64343 "HVESP2HIST" 64344 "HVESP2CFG" 64345 "HVESP1HIST" 64346 "HVESP1CFG" 64529 "TGFI" 64579 "TCSI" 64582 "TSIS" 64583 "MTI" 64605 "HVESSCFG" 64606 "HVESSHIST" 64653 "PII" 64701 "A1SCRSI2" 64782 "AT1OGC2" 64784 "AT1IGC2" 64839 "TML" 64879 "EEC8" 64896 "DM28" 64905 "VDS2" 64906 "J2012" 64912 "AETC" 64920 "AT1HI1" 64949 "DM23" 64950 "DM24" 64951 "DM25" 64952 "DM26" 64953 "TPRI" 64965 "ECUID" 64981 "EEC5" 65039 "LC" 65099 "TCFG2" 65109 "GFD" 65127 "CCC" 65131 "DI" 65136 "CVW" 65144 "TP1" 65145 "TP2" 65146 "TP3" 65195 "ETC6" 65196 "EBC4" 65199 "GFC" 65201 "EH" 65202 "GFI1" 65203 "LFI1" 65208 "GTFI" 65212 "CBI" 65214 "EEC4" 65216 "SERV" 65219 "ETC5" 65221 "ETC4" 65223 "ETC3" 65227 "DM02" 65228 "DM03" 65229 "DM04" 65230 "DM05" 65231 "DM06" 65234 "DM10" 65235 "DM11" 65236 "DM12" 65242 "SOFT" 65244 "IO" 65248 "VD" 65250 "TCFG" 65253 "HOURS" 65254 "TD" 65255 "VH" 65256 "VDS" 65257 "LFC1" 65258 "VW" 65259 "CI" 65260 "VI" 65261 "CCSS" 65284 "PB_DriversConsentOnPersonalData" 65340 "PB_HVESSCFG" 65376 "VehCfg" 65413 "PB_3CT" 65482 "PB_ID1" 65484 "PB_VNS" 65502 "Av2" 65520 "SCh" 65521 "DIS" 65524 "PB_IVA" ;
VAL_ 2565406503 Pgn_Ad_E8FF27 37120 "VLSI1" 40448 "DM29" 41216 "DM33" 41728 "DM31" 41984 "DM30" 47360 "PLLT (Plan List Lifetime)" 47872 "PLD (Plan List Distance)" 49408 "DM21" 49664 "DM20" 49920 "DM22" 53504 "MaintBcIc" 54016 "DM19" 60928 "ACL" 61184 "STOD" 64341 "HVESP3HIST" 64342 "HVESP3CFG" 64343 "HVESP2HIST" 64344 "HVESP2CFG" 64345 "HVESP1HIST" 64346 "HVESP1CFG" 64529 "TGFI" 64579 "TCSI" 64582 "TSIS" 64583 "MTI" 64605 "HVESSCFG" 64606 "HVESSHIST" 64653 "PII" 64701 "A1SCRSI2" 64782 "AT1OGC2" 64784 "AT1IGC2" 64839 "TML" 64879 "EEC8" 64896 "DM28" 64905 "VDS2" 64906 "J2012" 64912 "AETC" 64920 "AT1HI1" 64949 "DM23" 64950 "DM24" 64951 "DM25" 64952 "DM26" 64953 "TPRI" 64965 "ECUID" 64981 "EEC5" 65039 "LC" 65099 "TCFG2" 65109 "GFD" 65127 "CCC" 65131 "DI" 65136 "CVW" 65144 "TP1" 65145 "TP2" 65146 "TP3" 65195 "ETC6" 65196 "EBC4" 65199 "GFC" 65201 "EH" 65202 "GFI1" 65203 "LFI1" 65208 "GTFI" 65212 "CBI" 65214 "EEC4" 65216 "SERV" 65219 "ETC5" 65221 "ETC4" 65223 "ETC3" 65227 "DM02" 65228 "DM03" 65229 "DM04" 65230 "DM05" 65231 "DM06" 65234 "DM10" 65235 "DM11" 65236 "DM12" 65242 "SOFT" 65244 "IO" 65248 "VD" 65250 "TCFG" 65253 "HOURS" 65254 "TD" 65255 "VH" 65256 "VDS" 65257 "LFC1" 65258 "VW" 65259 "CI" 65260 "VI" 65261 "CCSS" 65284 "PB_DriversConsentOnPersonalData" 65340 "PB_HVESSCFG" 65376 "VehCfg" 65413 "PB_3CT" 65482 "PB_ID1" 65484 "PB_VNS" 65502 "Av2" 65520 "SCh" 65521 "DIS" 65524 "PB_IVA" ;
VAL_ 2565406503 Pgn_Busy_E8FF27 37120 "VLSI1" 40448 "DM29" 41216 "DM33" 41728 "DM31" 41984 "DM30" 47360 "PLLT (Plan List Lifetime)" 47872 "PLD (Plan List Distance)" 49408 "DM21" 49664 "DM20" 49920 "DM22" 53504 "MaintBcIc" 54016 "DM19" 60928 "ACL" 61184 "STOD" 64341 "HVESP3HIST" 64342 "HVESP3CFG" 64343 "HVESP2HIST" 64344 "HVESP2CFG" 64345 "HVESP1HIST" 64346 "HVESP1CFG" 64529 "TGFI" 64579 "TCSI" 64582 "TSIS" 64583 "MTI" 64605 "HVESSCFG" 64606 "HVESSHIST" 64653 "PII" 64701 "A1SCRSI2" 64782 "AT1OGC2" 64784 "AT1IGC2" 64839 "TML" 64879 "EEC8" 64896 "DM28" 64905 "VDS2" 64906 "J2012" 64912 "AETC" 64920 "AT1HI1" 64949 "DM23" 64950 "DM24" 64951 "DM25" 64952 "DM26" 64953 "TPRI" 64965 "ECUID" 64981 "EEC5" 65039 "LC" 65099 "TCFG2" 65109 "GFD" 65127 "CCC" 65131 "DI" 65136 "CVW" 65144 "TP1" 65145 "TP2" 65146 "TP3" 65195 "ETC6" 65196 "EBC4" 65199 "GFC" 65201 "EH" 65202 "GFI1" 65203 "LFI1" 65208 "GTFI" 65212 "CBI" 65214 "EEC4" 65216 "SERV" 65219 "ETC5" 65221 "ETC4" 65223 "ETC3" 65227 "DM02" 65228 "DM03" 65229 "DM04" 65230 "DM05" 65231 "DM06" 65234 "DM10" 65235 "DM11" 65236 "DM12" 65242 "SOFT" 65244 "IO" 65248 "VD" 65250 "TCFG" 65253 "HOURS" 65254 "TD" 65255 "VH" 65256 "VDS" 65257 "LFC1" 65258 "VW" 65259 "CI" 65260 "VI" 65261 "CCSS" 65284 "PB_DriversConsentOnPersonalData" 65340 "PB_HVESSCFG" 65376 "VehCfg" 65413 "PB_3CT" 65482 "PB_ID1" 65484 "PB_VNS" 65502 "Av2" 65520 "SCh" 65521 "DIS" 65524 "PB_IVA" ;
VAL_ 2565406515 Pgn_Ack_E8FF33 37120 "VLSI1" 40448 "DM29" 41216 "DM33" 41728 "DM31" 41984 "DM30" 47360 "PLLT (Plan List Lifetime)" 47872 "PLD (Plan List Distance)" 49408 "DM21" 49664 "DM20" 49920 "DM22" 53504 "MaintBcIc" 54016 "DM19" 60928 "ACL" 61184 "STOD" 64341 "HVESP3HIST" 64342 "HVESP3CFG" 64343 "HVESP2HIST" 64344 "HVESP2CFG" 64345 "HVESP1HIST" 64346 "HVESP1CFG" 64529 "TGFI" 64579 "TCSI" 64582 "TSIS" 64583 "MTI" 64605 "HVESSCFG" 64606 "HVESSHIST" 64653 "PII" 64701 "A1SCRSI2" 64782 "AT1OGC2" 64784 "AT1IGC2" 64839 "TML" 64879 "EEC8" 64896 "DM28" 64905 "VDS2" 64906 "J2012" 64912 "AETC" 64920 "AT1HI1" 64949 "DM23" 64950 "DM24" 64951 "DM25" 64952 "DM26" 64953 "TPRI" 64965 "ECUID" 64981 "EEC5" 65039 "LC" 65099 "TCFG2" 65109 "GFD" 65127 "CCC" 65131 "DI" 65136 "CVW" 65144 "TP1" 65145 "TP2" 65146 "TP3" 65195 "ETC6" 65196 "EBC4" 65199 "GFC" 65201 "EH" 65202 "GFI1" 65203 "LFI1" 65208 "GTFI" 65212 "CBI" 65214 "EEC4" 65216 "SERV" 65219 "ETC5" 65221 "ETC4" 65223 "ETC3" 65227 "DM02" 65228 "DM03" 65229 "DM04" 65230 "DM05" 65231 "DM06" 65234 "DM10" 65235 "DM11" 65236 "DM12" 65242 "SOFT" 65244 "IO" 65248 "VD" 65250 "TCFG" 65253 "HOURS" 65254 "TD" 65255 "VH" 65256 "VDS" 65257 "LFC1" 65258 "VW" 65259 "CI" 65260 "VI" 65261 "CCSS" 65284 "PB_DriversConsentOnPersonalData" 65340 "PB_HVESSCFG" 65376 "VehCfg" 65413 "PB_3CT" 65482 "PB_ID1" 65484 "PB_VNS" 65502 "Av2" 65520 "SCh" 65521 "DIS" 65524 "PB_IVA" ;
VAL_ 2565406515 Pgn_Nack_E8FF33 37120 "VLSI1" 40448 "DM29" 41216 "DM33" 41728 "DM31" 41984 "DM30" 47360 "PLLT (Plan List Lifetime)" 47872 "PLD (Plan List Distance)" 49408 "DM21" 49664 "DM20" 49920 "DM22" 53504 "MaintBcIc" 54016 "DM19" 60928 "ACL" 61184 "STOD" 64341 "HVESP3HIST" 64342 "HVESP3CFG" 64343 "HVESP2HIST" 64344 "HVESP2CFG" 64345 "HVESP1HIST" 64346 "HVESP1CFG" 64529 "TGFI" 64579 "TCSI" 64582 "TSIS" 64583 "MTI" 64605 "HVESSCFG" 64606 "HVESSHIST" 64653 "PII" 64701 "A1SCRSI2" 64782 "AT1OGC2" 64784 "AT1IGC2" 64839 "TML" 64879 "EEC8" 64896 "DM28" 64905 "VDS2" 64906 "J2012" 64912 "AETC" 64920 "AT1HI1" 64949 "DM23" 64950 "DM24" 64951 "DM25" 64952 "DM26" 64953 "TPRI" 64965 "ECUID" 64981 "EEC5" 65039 "LC" 65099 "TCFG2" 65109 "GFD" 65127 "CCC" 65131 "DI" 65136 "CVW" 65144 "TP1" 65145 "TP2" 65146 "TP3" 65195 "ETC6" 65196 "EBC4" 65199 "GFC" 65201 "EH" 65202 "GFI1" 65203 "LFI1" 65208 "GTFI" 65212 "CBI" 65214 "EEC4" 65216 "SERV" 65219 "ETC5" 65221 "ETC4" 65223 "ETC3" 65227 "DM02" 65228 "DM03" 65229 "DM04" 65230 "DM05" 65231 "DM06" 65234 "DM10" 65235 "DM11" 65236 "DM12" 65242 "SOFT" 65244 "IO" 65248 "VD" 65250 "TCFG" 65253 "HOURS" 65254 "TD" 65255 "VH" 65256 "VDS" 65257 "LFC1" 65258 "VW" 65259 "CI" 65260 "VI" 65261 "CCSS" 65284 "PB_DriversConsentOnPersonalData" 65340 "PB_HVESSCFG" 65376 "VehCfg" 65413 "PB_3CT" 65482 "PB_ID1" 65484 "PB_VNS" 65502 "Av2" 65520 "SCh" 65521 "DIS" 65524 "PB_IVA" ;
VAL_ 2565406515 Pgn_Ad_E8FF33 37120 "VLSI1" 40448 "DM29" 41216 "DM33" 41728 "DM31" 41984 "DM30" 47360 "PLLT (Plan List Lifetime)" 47872 "PLD (Plan List Distance)" 49408 "DM21" 49664 "DM20" 49920 "DM22" 53504 "MaintBcIc" 54016 "DM19" 60928 "ACL" 61184 "STOD" 64341 "HVESP3HIST" 64342 "HVESP3CFG" 64343 "HVESP2HIST" 64344 "HVESP2CFG" 64345 "HVESP1HIST" 64346 "HVESP1CFG" 64529 "TGFI" 64579 "TCSI" 64582 "TSIS" 64583 "MTI" 64605 "HVESSCFG" 64606 "HVESSHIST" 64653 "PII" 64701 "A1SCRSI2" 64782 "AT1OGC2" 64784 "AT1IGC2" 64839 "TML" 64879 "EEC8" 64896 "DM28" 64905 "VDS2" 64906 "J2012" 64912 "AETC" 64920 "AT1HI1" 64949 "DM23" 64950 "DM24" 64951 "DM25" 64952 "DM26" 64953 "TPRI" 64965 "ECUID" 64981 "EEC5" 65039 "LC" 65099 "TCFG2" 65109 "GFD" 65127 "CCC" 65131 "DI" 65136 "CVW" 65144 "TP1" 65145 "TP2" 65146 "TP3" 65195 "ETC6" 65196 "EBC4" 65199 "GFC" 65201 "EH" 65202 "GFI1" 65203 "LFI1" 65208 "GTFI" 65212 "CBI" 65214 "EEC4" 65216 "SERV" 65219 "ETC5" 65221 "ETC4" 65223 "ETC3" 65227 "DM02" 65228 "DM03" 65229 "DM04" 65230 "DM05" 65231 "DM06" 65234 "DM10" 65235 "DM11" 65236 "DM12" 65242 "SOFT" 65244 "IO" 65248 "VD" 65250 "TCFG" 65253 "HOURS" 65254 "TD" 65255 "VH" 65256 "VDS" 65257 "LFC1" 65258 "VW" 65259 "CI" 65260 "VI" 65261 "CCSS" 65284 "PB_DriversConsentOnPersonalData" 65340 "PB_HVESSCFG" 65376 "VehCfg" 65413 "PB_3CT" 65482 "PB_ID1" 65484 "PB_VNS" 65502 "Av2" 65520 "SCh" 65521 "DIS" 65524 "PB_IVA" ;
VAL_ 2565406515 Pgn_Busy_E8FF33 37120 "VLSI1" 40448 "DM29" 41216 "DM33" 41728 "DM31" 41984 "DM30" 47360 "PLLT (Plan List Lifetime)" 47872 "PLD (Plan List Distance)" 49408 "DM21" 49664 "DM20" 49920 "DM22" 53504 "MaintBcIc" 54016 "DM19" 60928 "ACL" 61184 "STOD" 64341 "HVESP3HIST" 64342 "HVESP3CFG" 64343 "HVESP2HIST" 64344 "HVESP2CFG" 64345 "HVESP1HIST" 64346 "HVESP1CFG" 64529 "TGFI" 64579 "TCSI" 64582 "TSIS" 64583 "MTI" 64605 "HVESSCFG" 64606 "HVESSHIST" 64653 "PII" 64701 "A1SCRSI2" 64782 "AT1OGC2" 64784 "AT1IGC2" 64839 "TML" 64879 "EEC8" 64896 "DM28" 64905 "VDS2" 64906 "J2012" 64912 "AETC" 64920 "AT1HI1" 64949 "DM23" 64950 "DM24" 64951 "DM25" 64952 "DM26" 64953 "TPRI" 64965 "ECUID" 64981 "EEC5" 65039 "LC" 65099 "TCFG2" 65109 "GFD" 65127 "CCC" 65131 "DI" 65136 "CVW" 65144 "TP1" 65145 "TP2" 65146 "TP3" 65195 "ETC6" 65196 "EBC4" 65199 "GFC" 65201 "EH" 65202 "GFI1" 65203 "LFI1" 65208 "GTFI" 65212 "CBI" 65214 "EEC4" 65216 "SERV" 65219 "ETC5" 65221 "ETC4" 65223 "ETC3" 65227 "DM02" 65228 "DM03" 65229 "DM04" 65230 "DM05" 65231 "DM06" 65234 "DM10" 65235 "DM11" 65236 "DM12" 65242 "SOFT" 65244 "IO" 65248 "VD" 65250 "TCFG" 65253 "HOURS" 65254 "TD" 65255 "VH" 65256 "VDS" 65257 "LFC1" 65258 "VW" 65259 "CI" 65260 "VI" 65261 "CCSS" 65284 "PB_DriversConsentOnPersonalData" 65340 "PB_HVESSCFG" 65376 "VehCfg" 65413 "PB_3CT" 65482 "PB_ID1" 65484 "PB_VNS" 65502 "Av2" 65520 "SCh" 65521 "DIS" 65524 "PB_IVA" ;
VAL_ 2565406529 Pgn_Ack_E8FF41 37120 "VLSI1" 40448 "DM29" 41216 "DM33" 41728 "DM31" 41984 "DM30" 47360 "PLLT (Plan List Lifetime)" 47872 "PLD (Plan List Distance)" 49408 "DM21" 49664 "DM20" 49920 "DM22" 53504 "MaintBcIc" 54016 "DM19" 60928 "ACL" 61184 "STOD" 64341 "HVESP3HIST" 64342 "HVESP3CFG" 64343 "HVESP2HIST" 64344 "HVESP2CFG" 64345 "HVESP1HIST" 64346 "HVESP1CFG" 64529 "TGFI" 64579 "TCSI" 64582 "TSIS" 64583 "MTI" 64605 "HVESSCFG" 64606 "HVESSHIST" 64653 "PII" 64701 "A1SCRSI2" 64782 "AT1OGC2" 64784 "AT1IGC2" 64839 "TML" 64879 "EEC8" 64896 "DM28" 64905 "VDS2" 64906 "J2012" 64912 "AETC" 64920 "AT1HI1" 64949 "DM23" 64950 "DM24" 64951 "DM25" 64952 "DM26" 64953 "TPRI" 64965 "ECUID" 64981 "EEC5" 65039 "LC" 65099 "TCFG2" 65109 "GFD" 65127 "CCC" 65131 "DI" 65136 "CVW" 65144 "TP1" 65145 "TP2" 65146 "TP3" 65195 "ETC6" 65196 "EBC4" 65199 "GFC" 65201 "EH" 65202 "GFI1" 65203 "LFI1" 65208 "GTFI" 65212 "CBI" 65214 "EEC4" 65216 "SERV" 65219 "ETC5" 65221 "ETC4" 65223 "ETC3" 65227 "DM02" 65228 "DM03" 65229 "DM04" 65230 "DM05" 65231 "DM06" 65234 "DM10" 65235 "DM11" 65236 "DM12" 65242 "SOFT" 65244 "IO" 65248 "VD" 65250 "TCFG" 65253 "HOURS" 65254 "TD" 65255 "VH" 65256 "VDS" 65257 "LFC1" 65258 "VW" 65259 "CI" 65260 "VI" 65261 "CCSS" 65284 "PB_DriversConsentOnPersonalData" 65340 "PB_HVESSCFG" 65376 "VehCfg" 65413 "PB_3CT" 65482 "PB_ID1" 65484 "PB_VNS" 65502 "Av2" 65520 "SCh" 65521 "DIS" 65524 "PB_IVA" ;
VAL_ 2565406529 Pgn_Nack_E8FF41 37120 "VLSI1" 40448 "DM29" 41216 "DM33" 41728 "DM31" 41984 "DM30" 47360 "PLLT (Plan List Lifetime)" 47872 "PLD (Plan List Distance)" 49408 "DM21" 49664 "DM20" 49920 "DM22" 53504 "MaintBcIc" 54016 "DM19" 60928 "ACL" 61184 "STOD" 64341 "HVESP3HIST" 64342 "HVESP3CFG" 64343 "HVESP2HIST" 64344 "HVESP2CFG" 64345 "HVESP1HIST" 64346 "HVESP1CFG" 64529 "TGFI" 64579 "TCSI" 64582 "TSIS" 64583 "MTI" 64605 "HVESSCFG" 64606 "HVESSHIST" 64653 "PII" 64701 "A1SCRSI2" 64782 "AT1OGC2" 64784 "AT1IGC2" 64839 "TML" 64879 "EEC8" 64896 "DM28" 64905 "VDS2" 64906 "J2012" 64912 "AETC" 64920 "AT1HI1" 64949 "DM23" 64950 "DM24" 64951 "DM25" 64952 "DM26" 64953 "TPRI" 64965 "ECUID" 64981 "EEC5" 65039 "LC" 65099 "TCFG2" 65109 "GFD" 65127 "CCC" 65131 "DI" 65136 "CVW" 65144 "TP1" 65145 "TP2" 65146 "TP3" 65195 "ETC6" 65196 "EBC4" 65199 "GFC" 65201 "EH" 65202 "GFI1" 65203 "LFI1" 65208 "GTFI" 65212 "CBI" 65214 "EEC4" 65216 "SERV" 65219 "ETC5" 65221 "ETC4" 65223 "ETC3" 65227 "DM02" 65228 "DM03" 65229 "DM04" 65230 "DM05" 65231 "DM06" 65234 "DM10" 65235 "DM11" 65236 "DM12" 65242 "SOFT" 65244 "IO" 65248 "VD" 65250 "TCFG" 65253 "HOURS" 65254 "TD" 65255 "VH" 65256 "VDS" 65257 "LFC1" 65258 "VW" 65259 "CI" 65260 "VI" 65261 "CCSS" 65284 "PB_DriversConsentOnPersonalData" 65340 "PB_HVESSCFG" 65376 "VehCfg" 65413 "PB_3CT" 65482 "PB_ID1" 65484 "PB_VNS" 65502 "Av2" 65520 "SCh" 65521 "DIS" 65524 "PB_IVA" ;
VAL_ 2565406529 Pgn_Ad_E8FF41 37120 "VLSI1" 40448 "DM29" 41216 "DM33" 41728 "DM31" 41984 "DM30" 47360 "PLLT (Plan List Lifetime)" 47872 "PLD (Plan List Distance)" 49408 "DM21" 49664 "DM20" 49920 "DM22" 53504 "MaintBcIc" 54016 "DM19" 60928 "ACL" 61184 "STOD" 64341 "HVESP3HIST" 64342 "HVESP3CFG" 64343 "HVESP2HIST" 64344 "HVESP2CFG" 64345 "HVESP1HIST" 64346 "HVESP1CFG" 64529 "TGFI" 64579 "TCSI" 64582 "TSIS" 64583 "MTI" 64605 "HVESSCFG" 64606 "HVESSHIST" 64653 "PII" 64701 "A1SCRSI2" 64782 "AT1OGC2" 64784 "AT1IGC2" 64839 "TML" 64879 "EEC8" 64896 "DM28" 64905 "VDS2" 64906 "J2012" 64912 "AETC" 64920 "AT1HI1" 64949 "DM23" 64950 "DM24" 64951 "DM25" 64952 "DM26" 64953 "TPRI" 64965 "ECUID" 64981 "EEC5" 65039 "LC" 65099 "TCFG2" 65109 "GFD" 65127 "CCC" 65131 "DI" 65136 "CVW" 65144 "TP1" 65145 "TP2" 65146 "TP3" 65195 "ETC6" 65196 "EBC4" 65199 "GFC" 65201 "EH" 65202 "GFI1" 65203 "LFI1" 65208 "GTFI" 65212 "CBI" 65214 "EEC4" 65216 "SERV" 65219 "ETC5" 65221 "ETC4" 65223 "ETC3" 65227 "DM02" 65228 "DM03" 65229 "DM04" 65230 "DM05" 65231 "DM06" 65234 "DM10" 65235 "DM11" 65236 "DM12" 65242 "SOFT" 65244 "IO" 65248 "VD" 65250 "TCFG" 65253 "HOURS" 65254 "TD" 65255 "VH" 65256 "VDS" 65257 "LFC1" 65258 "VW" 65259 "CI" 65260 "VI" 65261 "CCSS" 65284 "PB_DriversConsentOnPersonalData" 65340 "PB_HVESSCFG" 65376 "VehCfg" 65413 "PB_3CT" 65482 "PB_ID1" 65484 "PB_VNS" 65502 "Av2" 65520 "SCh" 65521 "DIS" 65524 "PB_IVA" ;
VAL_ 2565406529 Pgn_Busy_E8FF41 37120 "VLSI1" 40448 "DM29" 41216 "DM33" 41728 "DM31" 41984 "DM30" 47360 "PLLT (Plan List Lifetime)" 47872 "PLD (Plan List Distance)" 49408 "DM21" 49664 "DM20" 49920 "DM22" 53504 "MaintBcIc" 54016 "DM19" 60928 "ACL" 61184 "STOD" 64341 "HVESP3HIST" 64342 "HVESP3CFG" 64343 "HVESP2HIST" 64344 "HVESP2CFG" 64345 "HVESP1HIST" 64346 "HVESP1CFG" 64529 "TGFI" 64579 "TCSI" 64582 "TSIS" 64583 "MTI" 64605 "HVESSCFG" 64606 "HVESSHIST" 64653 "PII" 64701 "A1SCRSI2" 64782 "AT1OGC2" 64784 "AT1IGC2" 64839 "TML" 64879 "EEC8" 64896 "DM28" 64905 "VDS2" 64906 "J2012" 64912 "AETC" 64920 "AT1HI1" 64949 "DM23" 64950 "DM24" 64951 "DM25" 64952 "DM26" 64953 "TPRI" 64965 "ECUID" 64981 "EEC5" 65039 "LC" 65099 "TCFG2" 65109 "GFD" 65127 "CCC" 65131 "DI" 65136 "CVW" 65144 "TP1" 65145 "TP2" 65146 "TP3" 65195 "ETC6" 65196 "EBC4" 65199 "GFC" 65201 "EH" 65202 "GFI1" 65203 "LFI1" 65208 "GTFI" 65212 "CBI" 65214 "EEC4" 65216 "SERV" 65219 "ETC5" 65221 "ETC4" 65223 "ETC3" 65227 "DM02" 65228 "DM03" 65229 "DM04" 65230 "DM05" 65231 "DM06" 65234 "DM10" 65235 "DM11" 65236 "DM12" 65242 "SOFT" 65244 "IO" 65248 "VD" 65250 "TCFG" 65253 "HOURS" 65254 "TD" 65255 "VH" 65256 "VDS" 65257 "LFC1" 65258 "VW" 65259 "CI" 65260 "VI" 65261 "CCSS" 65284 "PB_DriversConsentOnPersonalData" 65340 "PB_HVESSCFG" 65376 "VehCfg" 65413 "PB_3CT" 65482 "PB_ID1" 65484 "PB_VNS" 65502 "Av2" 65520 "SCh" 65521 "DIS" 65524 "PB_IVA" ;
VAL_ 2565406537 Pgn_Ack_E8FF49 37120 "VLSI1" 40448 "DM29" 41216 "DM33" 41728 "DM31" 41984 "DM30" 47360 "PLLT (Plan List Lifetime)" 47872 "PLD (Plan List Distance)" 49408 "DM21" 49664 "DM20" 49920 "DM22" 53504 "MaintBcIc" 54016 "DM19" 60928 "ACL" 61184 "STOD" 64341 "HVESP3HIST" 64342 "HVESP3CFG" 64343 "HVESP2HIST" 64344 "HVESP2CFG" 64345 "HVESP1HIST" 64346 "HVESP1CFG" 64529 "TGFI" 64579 "TCSI" 64582 "TSIS" 64583 "MTI" 64605 "HVESSCFG" 64606 "HVESSHIST" 64653 "PII" 64701 "A1SCRSI2" 64782 "AT1OGC2" 64784 "AT1IGC2" 64839 "TML" 64879 "EEC8" 64896 "DM28" 64905 "VDS2" 64906 "J2012" 64912 "AETC" 64920 "AT1HI1" 64949 "DM23" 64950 "DM24" 64951 "DM25" 64952 "DM26" 64953 "TPRI" 64965 "ECUID" 64981 "EEC5" 65039 "LC" 65099 "TCFG2" 65109 "GFD" 65127 "CCC" 65131 "DI" 65136 "CVW" 65144 "TP1" 65145 "TP2" 65146 "TP3" 65195 "ETC6" 65196 "EBC4" 65199 "GFC" 65201 "EH" 65202 "GFI1" 65203 "LFI1" 65208 "GTFI" 65212 "CBI" 65214 "EEC4" 65216 "SERV" 65219 "ETC5" 65221 "ETC4" 65223 "ETC3" 65227 "DM02" 65228 "DM03" 65229 "DM04" 65230 "DM05" 65231 "DM06" 65234 "DM10" 65235 "DM11" 65236 "DM12" 65242 "SOFT" 65244 "IO" 65248 "VD" 65250 "TCFG" 65253 "HOURS" 65254 "TD" 65255 "VH" 65256 "VDS" 65257 "LFC1" 65258 "VW" 65259 "CI" 65260 "VI" 65261 "CCSS" 65284 "PB_DriversConsentOnPersonalData" 65340 "PB_HVESSCFG" 65376 "VehCfg" 65413 "PB_3CT" 65482 "PB_ID1" 65484 "PB_VNS" 65502 "Av2" 65520 "SCh" 65521 "DIS" 65524 "PB_IVA" ;
VAL_ 2565406537 Pgn_Nack_E8FF49 37120 "VLSI1" 40448 "DM29" 41216 "DM33" 41728 "DM31" 41984 "DM30" 47360 "PLLT (Plan List Lifetime)" 47872 "PLD (Plan List Distance)" 49408 "DM21" 49664 "DM20" 49920 "DM22" 53504 "MaintBcIc" 54016 "DM19" 60928 "ACL" 61184 "STOD" 64341 "HVESP3HIST" 64342 "HVESP3CFG" 64343 "HVESP2HIST" 64344 "HVESP2CFG" 64345 "HVESP1HIST" 64346 "HVESP1CFG" 64529 "TGFI" 64579 "TCSI" 64582 "TSIS" 64583 "MTI" 64605 "HVESSCFG" 64606 "HVESSHIST" 64653 "PII" 64701 "A1SCRSI2" 64782 "AT1OGC2" 64784 "AT1IGC2" 64839 "TML" 64879 "EEC8" 64896 "DM28" 64905 "VDS2" 64906 "J2012" 64912 "AETC" 64920 "AT1HI1" 64949 "DM23" 64950 "DM24" 64951 "DM25" 64952 "DM26" 64953 "TPRI" 64965 "ECUID" 64981 "EEC5" 65039 "LC" 65099 "TCFG2" 65109 "GFD" 65127 "CCC" 65131 "DI" 65136 "CVW" 65144 "TP1" 65145 "TP2" 65146 "TP3" 65195 "ETC6" 65196 "EBC4" 65199 "GFC" 65201 "EH" 65202 "GFI1" 65203 "LFI1" 65208 "GTFI" 65212 "CBI" 65214 "EEC4" 65216 "SERV" 65219 "ETC5" 65221 "ETC4" 65223 "ETC3" 65227 "DM02" 65228 "DM03" 65229 "DM04" 65230 "DM05" 65231 "DM06" 65234 "DM10" 65235 "DM11" 65236 "DM12" 65242 "SOFT" 65244 "IO" 65248 "VD" 65250 "TCFG" 65253 "HOURS" 65254 "TD" 65255 "VH" 65256 "VDS" 65257 "LFC1" 65258 "VW" 65259 "CI" 65260 "VI" 65261 "CCSS" 65284 "PB_DriversConsentOnPersonalData" 65340 "PB_HVESSCFG" 65376 "VehCfg" 65413 "PB_3CT" 65482 "PB_ID1" 65484 "PB_VNS" 65502 "Av2" 65520 "SCh" 65521 "DIS" 65524 "PB_IVA" ;
VAL_ 2565406537 Pgn_Ad_E8FF49 37120 "VLSI1" 40448 "DM29" 41216 "DM33" 41728 "DM31" 41984 "DM30" 47360 "PLLT (Plan List Lifetime)" 47872 "PLD (Plan List Distance)" 49408 "DM21" 49664 "DM20" 49920 "DM22" 53504 "MaintBcIc" 54016 "DM19" 60928 "ACL" 61184 "STOD" 64341 "HVESP3HIST" 64342 "HVESP3CFG" 64343 "HVESP2HIST" 64344 "HVESP2CFG" 64345 "HVESP1HIST" 64346 "HVESP1CFG" 64529 "TGFI" 64579 "TCSI" 64582 "TSIS" 64583 "MTI" 64605 "HVESSCFG" 64606 "HVESSHIST" 64653 "PII" 64701 "A1SCRSI2" 64782 "AT1OGC2" 64784 "AT1IGC2" 64839 "TML" 64879 "EEC8" 64896 "DM28" 64905 "VDS2" 64906 "J2012" 64912 "AETC" 64920 "AT1HI1" 64949 "DM23" 64950 "DM24" 64951 "DM25" 64952 "DM26" 64953 "TPRI" 64965 "ECUID" 64981 "EEC5" 65039 "LC" 65099 "TCFG2" 65109 "GFD" 65127 "CCC" 65131 "DI" 65136 "CVW" 65144 "TP1" 65145 "TP2" 65146 "TP3" 65195 "ETC6" 65196 "EBC4" 65199 "GFC" 65201 "EH" 65202 "GFI1" 65203 "LFI1" 65208 "GTFI" 65212 "CBI" 65214 "EEC4" 65216 "SERV" 65219 "ETC5" 65221 "ETC4" 65223 "ETC3" 65227 "DM02" 65228 "DM03" 65229 "DM04" 65230 "DM05" 65231 "DM06" 65234 "DM10" 65235 "DM11" 65236 "DM12" 65242 "SOFT" 65244 "IO" 65248 "VD" 65250 "TCFG" 65253 "HOURS" 65254 "TD" 65255 "VH" 65256 "VDS" 65257 "LFC1" 65258 "VW" 65259 "CI" 65260 "VI" 65261 "CCSS" 65284 "PB_DriversConsentOnPersonalData" 65340 "PB_HVESSCFG" 65376 "VehCfg" 65413 "PB_3CT" 65482 "PB_ID1" 65484 "PB_VNS" 65502 "Av2" 65520 "SCh" 65521 "DIS" 65524 "PB_IVA" ;
VAL_ 2565406537 Pgn_Busy_E8FF49 37120 "VLSI1" 40448 "DM29" 41216 "DM33" 41728 "DM31" 41984 "DM30" 47360 "PLLT (Plan List Lifetime)" 47872 "PLD (Plan List Distance)" 49408 "DM21" 49664 "DM20" 49920 "DM22" 53504 "MaintBcIc" 54016 "DM19" 60928 "ACL" 61184 "STOD" 64341 "HVESP3HIST" 64342 "HVESP3CFG" 64343 "HVESP2HIST" 64344 "HVESP2CFG" 64345 "HVESP1HIST" 64346 "HVESP1CFG" 64529 "TGFI" 64579 "TCSI" 64582 "TSIS" 64583 "MTI" 64605 "HVESSCFG" 64606 "HVESSHIST" 64653 "PII" 64701 "A1SCRSI2" 64782 "AT1OGC2" 64784 "AT1IGC2" 64839 "TML" 64879 "EEC8" 64896 "DM28" 64905 "VDS2" 64906 "J2012" 64912 "AETC" 64920 "AT1HI1" 64949 "DM23" 64950 "DM24" 64951 "DM25" 64952 "DM26" 64953 "TPRI" 64965 "ECUID" 64981 "EEC5" 65039 "LC" 65099 "TCFG2" 65109 "GFD" 65127 "CCC" 65131 "DI" 65136 "CVW" 65144 "TP1" 65145 "TP2" 65146 "TP3" 65195 "ETC6" 65196 "EBC4" 65199 "GFC" 65201 "EH" 65202 "GFI1" 65203 "LFI1" 65208 "GTFI" 65212 "CBI" 65214 "EEC4" 65216 "SERV" 65219 "ETC5" 65221 "ETC4" 65223 "ETC3" 65227 "DM02" 65228 "DM03" 65229 "DM04" 65230 "DM05" 65231 "DM06" 65234 "DM10" 65235 "DM11" 65236 "DM12" 65242 "SOFT" 65244 "IO" 65248 "VD" 65250 "TCFG" 65253 "HOURS" 65254 "TD" 65255 "VH" 65256 "VDS" 65257 "LFC1" 65258 "VW" 65259 "CI" 65260 "VI" 65261 "CCSS" 65284 "PB_DriversConsentOnPersonalData" 65340 "PB_HVESSCFG" 65376 "VehCfg" 65413 "PB_3CT" 65482 "PB_ID1" 65484 "PB_VNS" 65502 "Av2" 65520 "SCh" 65521 "DIS" 65524 "PB_IVA" ;
VAL_ 2565406538 Pgn_Ack_E8FF4A 37120 "VLSI1" 40448 "DM29" 41216 "DM33" 41728 "DM31" 41984 "DM30" 47360 "PLLT (Plan List Lifetime)" 47872 "PLD (Plan List Distance)" 49408 "DM21" 49664 "DM20" 49920 "DM22" 53504 "MaintBcIc" 54016 "DM19" 60928 "ACL" 61184 "STOD" 64341 "HVESP3HIST" 64342 "HVESP3CFG" 64343 "HVESP2HIST" 64344 "HVESP2CFG" 64345 "HVESP1HIST" 64346 "HVESP1CFG" 64529 "TGFI" 64579 "TCSI" 64582 "TSIS" 64583 "MTI" 64605 "HVESSCFG" 64606 "HVESSHIST" 64653 "PII" 64701 "A1SCRSI2" 64782 "AT1OGC2" 64784 "AT1IGC2" 64839 "TML" 64879 "EEC8" 64896 "DM28" 64905 "VDS2" 64906 "J2012" 64912 "AETC" 64920 "AT1HI1" 64949 "DM23" 64950 "DM24" 64951 "DM25" 64952 "DM26" 64953 "TPRI" 64965 "ECUID" 64981 "EEC5" 65039 "LC" 65099 "TCFG2" 65109 "GFD" 65127 "CCC" 65131 "DI" 65136 "CVW" 65144 "TP1" 65145 "TP2" 65146 "TP3" 65195 "ETC6" 65196 "EBC4" 65199 "GFC" 65201 "EH" 65202 "GFI1" 65203 "LFI1" 65208 "GTFI" 65212 "CBI" 65214 "EEC4" 65216 "SERV" 65219 "ETC5" 65221 "ETC4" 65223 "ETC3" 65227 "DM02" 65228 "DM03" 65229 "DM04" 65230 "DM05" 65231 "DM06" 65234 "DM10" 65235 "DM11" 65236 "DM12" 65242 "SOFT" 65244 "IO" 65248 "VD" 65250 "TCFG" 65253 "HOURS" 65254 "TD" 65255 "VH" 65256 "VDS" 65257 "LFC1" 65258 "VW" 65259 "CI" 65260 "VI" 65261 "CCSS" 65284 "PB_DriversConsentOnPersonalData" 65340 "PB_HVESSCFG" 65376 "VehCfg" 65413 "PB_3CT" 65482 "PB_ID1" 65484 "PB_VNS" 65502 "Av2" 65520 "SCh" 65521 "DIS" 65524 "PB_IVA" ;
VAL_ 2565406538 Pgn_Nack_E8FF4A 37120 "VLSI1" 40448 "DM29" 41216 "DM33" 41728 "DM31" 41984 "DM30" 47360 "PLLT (Plan List Lifetime)" 47872 "PLD (Plan List Distance)" 49408 "DM21" 49664 "DM20" 49920 "DM22" 53504 "MaintBcIc" 54016 "DM19" 60928 "ACL" 61184 "STOD" 64341 "HVESP3HIST" 64342 "HVESP3CFG" 64343 "HVESP2HIST" 64344 "HVESP2CFG" 64345 "HVESP1HIST" 64346 "HVESP1CFG" 64529 "TGFI" 64579 "TCSI" 64582 "TSIS" 64583 "MTI" 64605 "HVESSCFG" 64606 "HVESSHIST" 64653 "PII" 64701 "A1SCRSI2" 64782 "AT1OGC2" 64784 "AT1IGC2" 64839 "TML" 64879 "EEC8" 64896 "DM28" 64905 "VDS2" 64906 "J2012" 64912 "AETC" 64920 "AT1HI1" 64949 "DM23" 64950 "DM24" 64951 "DM25" 64952 "DM26" 64953 "TPRI" 64965 "ECUID" 64981 "EEC5" 65039 "LC" 65099 "TCFG2" 65109 "GFD" 65127 "CCC" 65131 "DI" 65136 "CVW" 65144 "TP1" 65145 "TP2" 65146 "TP3" 65195 "ETC6" 65196 "EBC4" 65199 "GFC" 65201 "EH" 65202 "GFI1" 65203 "LFI1" 65208 "GTFI" 65212 "CBI" 65214 "EEC4" 65216 "SERV" 65219 "ETC5" 65221 "ETC4" 65223 "ETC3" 65227 "DM02" 65228 "DM03" 65229 "DM04" 65230 "DM05" 65231 "DM06" 65234 "DM10" 65235 "DM11" 65236 "DM12" 65242 "SOFT" 65244 "IO" 65248 "VD" 65250 "TCFG" 65253 "HOURS" 65254 "TD" 65255 "VH" 65256 "VDS" 65257 "LFC1" 65258 "VW" 65259 "CI" 65260 "VI" 65261 "CCSS" 65284 "PB_DriversConsentOnPersonalData" 65340 "PB_HVESSCFG" 65376 "VehCfg" 65413 "PB_3CT" 65482 "PB_ID1" 65484 "PB_VNS" 65502 "Av2" 65520 "SCh" 65521 "DIS" 65524 "PB_IVA" ;
VAL_ 2565406538 Pgn_Ad_E8FF4A 37120 "VLSI1" 40448 "DM29" 41216 "DM33" 41728 "DM31" 41984 "DM30" 47360 "PLLT (Plan List Lifetime)" 47872 "PLD (Plan List Distance)" 49408 "DM21" 49664 "DM20" 49920 "DM22" 53504 "MaintBcIc" 54016 "DM19" 60928 "ACL" 61184 "STOD" 64341 "HVESP3HIST" 64342 "HVESP3CFG" 64343 "HVESP2HIST" 64344 "HVESP2CFG" 64345 "HVESP1HIST" 64346 "HVESP1CFG" 64529 "TGFI" 64579 "TCSI" 64582 "TSIS" 64583 "MTI" 64605 "HVESSCFG" 64606 "HVESSHIST" 64653 "PII" 64701 "A1SCRSI2" 64782 "AT1OGC2" 64784 "AT1IGC2" 64839 "TML" 64879 "EEC8" 64896 "DM28" 64905 "VDS2" 64906 "J2012" 64912 "AETC" 64920 "AT1HI1" 64949 "DM23" 64950 "DM24" 64951 "DM25" 64952 "DM26" 64953 "TPRI" 64965 "ECUID" 64981 "EEC5" 65039 "LC" 65099 "TCFG2" 65109 "GFD" 65127 "CCC" 65131 "DI" 65136 "CVW" 65144 "TP1" 65145 "TP2" 65146 "TP3" 65195 "ETC6" 65196 "EBC4" 65199 "GFC" 65201 "EH" 65202 "GFI1" 65203 "LFI1" 65208 "GTFI" 65212 "CBI" 65214 "EEC4" 65216 "SERV" 65219 "ETC5" 65221 "ETC4" 65223 "ETC3" 65227 "DM02" 65228 "DM03" 65229 "DM04" 65230 "DM05" 65231 "DM06" 65234 "DM10" 65235 "DM11" 65236 "DM12" 65242 "SOFT" 65244 "IO" 65248 "VD" 65250 "TCFG" 65253 "HOURS" 65254 "TD" 65255 "VH" 65256 "VDS" 65257 "LFC1" 65258 "VW" 65259 "CI" 65260 "VI" 65261 "CCSS" 65284 "PB_DriversConsentOnPersonalData" 65340 "PB_HVESSCFG" 65376 "VehCfg" 65413 "PB_3CT" 65482 "PB_ID1" 65484 "PB_VNS" 65502 "Av2" 65520 "SCh" 65521 "DIS" 65524 "PB_IVA" ;
VAL_ 2565406538 Pgn_Busy_E8FF4A 37120 "VLSI1" 40448 "DM29" 41216 "DM33" 41728 "DM31" 41984 "DM30" 47360 "PLLT (Plan List Lifetime)" 47872 "PLD (Plan List Distance)" 49408 "DM21" 49664 "DM20" 49920 "DM22" 53504 "MaintBcIc" 54016 "DM19" 60928 "ACL" 61184 "STOD" 64341 "HVESP3HIST" 64342 "HVESP3CFG" 64343 "HVESP2HIST" 64344 "HVESP2CFG" 64345 "HVESP1HIST" 64346 "HVESP1CFG" 64529 "TGFI" 64579 "TCSI" 64582 "TSIS" 64583 "MTI" 64605 "HVESSCFG" 64606 "HVESSHIST" 64653 "PII" 64701 "A1SCRSI2" 64782 "AT1OGC2" 64784 "AT1IGC2" 64839 "TML" 64879 "EEC8" 64896 "DM28" 64905 "VDS2" 64906 "J2012" 64912 "AETC" 64920 "AT1HI1" 64949 "DM23" 64950 "DM24" 64951 "DM25" 64952 "DM26" 64953 "TPRI" 64965 "ECUID" 64981 "EEC5" 65039 "LC" 65099 "TCFG2" 65109 "GFD" 65127 "CCC" 65131 "DI" 65136 "CVW" 65144 "TP1" 65145 "TP2" 65146 "TP3" 65195 "ETC6" 65196 "EBC4" 65199 "GFC" 65201 "EH" 65202 "GFI1" 65203 "LFI1" 65208 "GTFI" 65212 "CBI" 65214 "EEC4" 65216 "SERV" 65219 "ETC5" 65221 "ETC4" 65223 "ETC3" 65227 "DM02" 65228 "DM03" 65229 "DM04" 65230 "DM05" 65231 "DM06" 65234 "DM10" 65235 "DM11" 65236 "DM12" 65242 "SOFT" 65244 "IO" 65248 "VD" 65250 "TCFG" 65253 "HOURS" 65254 "TD" 65255 "VH" 65256 "VDS" 65257 "LFC1" 65258 "VW" 65259 "CI" 65260 "VI" 65261 "CCSS" 65284 "PB_DriversConsentOnPersonalData" 65340 "PB_HVESSCFG" 65376 "VehCfg" 65413 "PB_3CT" 65482 "PB_ID1" 65484 "PB_VNS" 65502 "Av2" 65520 "SCh" 65521 "DIS" 65524 "PB_IVA" ;
VAL_ 2565406588 Pgn_Ack_E8FF7C 37120 "VLSI1" 40448 "DM29" 41216 "DM33" 41728 "DM31" 41984 "DM30" 47360 "PLLT (Plan List Lifetime)" 47872 "PLD (Plan List Distance)" 49408 "DM21" 49664 "DM20" 49920 "DM22" 53504 "MaintBcIc" 54016 "DM19" 60928 "ACL" 61184 "STOD" 64341 "HVESP3HIST" 64342 "HVESP3CFG" 64343 "HVESP2HIST" 64344 "HVESP2CFG" 64345 "HVESP1HIST" 64346 "HVESP1CFG" 64529 "TGFI" 64579 "TCSI" 64582 "TSIS" 64583 "MTI" 64605 "HVESSCFG" 64606 "HVESSHIST" 64653 "PII" 64701 "A1SCRSI2" 64782 "AT1OGC2" 64784 "AT1IGC2" 64839 "TML" 64879 "EEC8" 64896 "DM28" 64905 "VDS2" 64906 "J2012" 64912 "AETC" 64920 "AT1HI1" 64949 "DM23" 64950 "DM24" 64951 "DM25" 64952 "DM26" 64953 "TPRI" 64965 "ECUID" 64981 "EEC5" 65039 "LC" 65099 "TCFG2" 65109 "GFD" 65127 "CCC" 65131 "DI" 65136 "CVW" 65144 "TP1" 65145 "TP2" 65146 "TP3" 65195 "ETC6" 65196 "EBC4" 65199 "GFC" 65201 "EH" 65202 "GFI1" 65203 "LFI1" 65208 "GTFI" 65212 "CBI" 65214 "EEC4" 65216 "SERV" 65219 "ETC5" 65221 "ETC4" 65223 "ETC3" 65227 "DM02" 65228 "DM03" 65229 "DM04" 65230 "DM05" 65231 "DM06" 65234 "DM10" 65235 "DM11" 65236 "DM12" 65242 "SOFT" 65244 "IO" 65248 "VD" 65250 "TCFG" 65253 "HOURS" 65254 "TD" 65255 "VH" 65256 "VDS" 65257 "LFC1" 65258 "VW" 65259 "CI" 65260 "VI" 65261 "CCSS" 65284 "PB_DriversConsentOnPersonalData" 65340 "PB_HVESSCFG" 65376 "VehCfg" 65413 "PB_3CT" 65482 "PB_ID1" 65484 "PB_VNS" 65502 "Av2" 65520 "SCh" 65521 "DIS" 65524 "PB_IVA" ;
VAL_ 2565406588 Pgn_Nack_E8FF7C 37120 "VLSI1" 40448 "DM29" 41216 "DM33" 41728 "DM31" 41984 "DM30" 47360 "PLLT (Plan List Lifetime)" 47872 "PLD (Plan List Distance)" 49408 "DM21" 49664 "DM20" 49920 "DM22" 53504 "MaintBcIc" 54016 "DM19" 60928 "ACL" 61184 "STOD" 64341 "HVESP3HIST" 64342 "HVESP3CFG" 64343 "HVESP2HIST" 64344 "HVESP2CFG" 64345 "HVESP1HIST" 64346 "HVESP1CFG" 64529 "TGFI" 64579 "TCSI" 64582 "TSIS" 64583 "MTI" 64605 "HVESSCFG" 64606 "HVESSHIST" 64653 "PII" 64701 "A1SCRSI2" 64782 "AT1OGC2" 64784 "AT1IGC2" 64839 "TML" 64879 "EEC8" 64896 "DM28" 64905 "VDS2" 64906 "J2012" 64912 "AETC" 64920 "AT1HI1" 64949 "DM23" 64950 "DM24" 64951 "DM25" 64952 "DM26" 64953 "TPRI" 64965 "ECUID" 64981 "EEC5" 65039 "LC" 65099 "TCFG2" 65109 "GFD" 65127 "CCC" 65131 "DI" 65136 "CVW" 65144 "TP1" 65145 "TP2" 65146 "TP3" 65195 "ETC6" 65196 "EBC4" 65199 "GFC" 65201 "EH" 65202 "GFI1" 65203 "LFI1" 65208 "GTFI" 65212 "CBI" 65214 "EEC4" 65216 "SERV" 65219 "ETC5" 65221 "ETC4" 65223 "ETC3" 65227 "DM02" 65228 "DM03" 65229 "DM04" 65230 "DM05" 65231 "DM06" 65234 "DM10" 65235 "DM11" 65236 "DM12" 65242 "SOFT" 65244 "IO" 65248 "VD" 65250 "TCFG" 65253 "HOURS" 65254 "TD" 65255 "VH" 65256 "VDS" 65257 "LFC1" 65258 "VW" 65259 "CI" 65260 "VI" 65261 "CCSS" 65284 "PB_DriversConsentOnPersonalData" 65340 "PB_HVESSCFG" 65376 "VehCfg" 65413 "PB_3CT" 65482 "PB_ID1" 65484 "PB_VNS" 65502 "Av2" 65520 "SCh" 65521 "DIS" 65524 "PB_IVA" ;
VAL_ 2565406588 Pgn_Ad_E8FF7C 37120 "VLSI1" 40448 "DM29" 41216 "DM33" 41728 "DM31" 41984 "DM30" 47360 "PLLT (Plan List Lifetime)" 47872 "PLD (Plan List Distance)" 49408 "DM21" 49664 "DM20" 49920 "DM22" 53504 "MaintBcIc" 54016 "DM19" 60928 "ACL" 61184 "STOD" 64341 "HVESP3HIST" 64342 "HVESP3CFG" 64343 "HVESP2HIST" 64344 "HVESP2CFG" 64345 "HVESP1HIST" 64346 "HVESP1CFG" 64529 "TGFI" 64579 "TCSI" 64582 "TSIS" 64583 "MTI" 64605 "HVESSCFG" 64606 "HVESSHIST" 64653 "PII" 64701 "A1SCRSI2" 64782 "AT1OGC2" 64784 "AT1IGC2" 64839 "TML" 64879 "EEC8" 64896 "DM28" 64905 "VDS2" 64906 "J2012" 64912 "AETC" 64920 "AT1HI1" 64949 "DM23" 64950 "DM24" 64951 "DM25" 64952 "DM26" 64953 "TPRI" 64965 "ECUID" 64981 "EEC5" 65039 "LC" 65099 "TCFG2" 65109 "GFD" 65127 "CCC" 65131 "DI" 65136 "CVW" 65144 "TP1" 65145 "TP2" 65146 "TP3" 65195 "ETC6" 65196 "EBC4" 65199 "GFC" 65201 "EH" 65202 "GFI1" 65203 "LFI1" 65208 "GTFI" 65212 "CBI" 65214 "EEC4" 65216 "SERV" 65219 "ETC5" 65221 "ETC4" 65223 "ETC3" 65227 "DM02" 65228 "DM03" 65229 "DM04" 65230 "DM05" 65231 "DM06" 65234 "DM10" 65235 "DM11" 65236 "DM12" 65242 "SOFT" 65244 "IO" 65248 "VD" 65250 "TCFG" 65253 "HOURS" 65254 "TD" 65255 "VH" 65256 "VDS" 65257 "LFC1" 65258 "VW" 65259 "CI" 65260 "VI" 65261 "CCSS" 65284 "PB_DriversConsentOnPersonalData" 65340 "PB_HVESSCFG" 65376 "VehCfg" 65413 "PB_3CT" 65482 "PB_ID1" 65484 "PB_VNS" 65502 "Av2" 65520 "SCh" 65521 "DIS" 65524 "PB_IVA" ;
VAL_ 2565406588 Pgn_Busy_E8FF7C 37120 "VLSI1" 40448 "DM29" 41216 "DM33" 41728 "DM31" 41984 "DM30" 47360 "PLLT (Plan List Lifetime)" 47872 "PLD (Plan List Distance)" 49408 "DM21" 49664 "DM20" 49920 "DM22" 53504 "MaintBcIc" 54016 "DM19" 60928 "ACL" 61184 "STOD" 64341 "HVESP3HIST" 64342 "HVESP3CFG" 64343 "HVESP2HIST" 64344 "HVESP2CFG" 64345 "HVESP1HIST" 64346 "HVESP1CFG" 64529 "TGFI" 64579 "TCSI" 64582 "TSIS" 64583 "MTI" 64605 "HVESSCFG" 64606 "HVESSHIST" 64653 "PII" 64701 "A1SCRSI2" 64782 "AT1OGC2" 64784 "AT1IGC2" 64839 "TML" 64879 "EEC8" 64896 "DM28" 64905 "VDS2" 64906 "J2012" 64912 "AETC" 64920 "AT1HI1" 64949 "DM23" 64950 "DM24" 64951 "DM25" 64952 "DM26" 64953 "TPRI" 64965 "ECUID" 64981 "EEC5" 65039 "LC" 65099 "TCFG2" 65109 "GFD" 65127 "CCC" 65131 "DI" 65136 "CVW" 65144 "TP1" 65145 "TP2" 65146 "TP3" 65195 "ETC6" 65196 "EBC4" 65199 "GFC" 65201 "EH" 65202 "GFI1" 65203 "LFI1" 65208 "GTFI" 65212 "CBI" 65214 "EEC4" 65216 "SERV" 65219 "ETC5" 65221 "ETC4" 65223 "ETC3" 65227 "DM02" 65228 "DM03" 65229 "DM04" 65230 "DM05" 65231 "DM06" 65234 "DM10" 65235 "DM11" 65236 "DM12" 65242 "SOFT" 65244 "IO" 65248 "VD" 65250 "TCFG" 65253 "HOURS" 65254 "TD" 65255 "VH" 65256 "VDS" 65257 "LFC1" 65258 "VW" 65259 "CI" 65260 "VI" 65261 "CCSS" 65284 "PB_DriversConsentOnPersonalData" 65340 "PB_HVESSCFG" 65376 "VehCfg" 65413 "PB_3CT" 65482 "PB_ID1" 65484 "PB_VNS" 65502 "Av2" 65520 "SCh" 65521 "DIS" 65524 "PB_IVA" ;
VAL_ 2565406598 Pgn_Ack_E8FF86 37120 "VLSI1" 40448 "DM29" 41216 "DM33" 41728 "DM31" 41984 "DM30" 47360 "PLLT (Plan List Lifetime)" 47872 "PLD (Plan List Distance)" 49408 "DM21" 49664 "DM20" 49920 "DM22" 53504 "MaintBcIc" 54016 "DM19" 60928 "ACL" 61184 "STOD" 64341 "HVESP3HIST" 64342 "HVESP3CFG" 64343 "HVESP2HIST" 64344 "HVESP2CFG" 64345 "HVESP1HIST" 64346 "HVESP1CFG" 64529 "TGFI" 64579 "TCSI" 64582 "TSIS" 64583 "MTI" 64605 "HVESSCFG" 64606 "HVESSHIST" 64653 "PII" 64701 "A1SCRSI2" 64782 "AT1OGC2" 64784 "AT1IGC2" 64839 "TML" 64879 "EEC8" 64896 "DM28" 64905 "VDS2" 64906 "J2012" 64912 "AETC" 64920 "AT1HI1" 64949 "DM23" 64950 "DM24" 64951 "DM25" 64952 "DM26" 64953 "TPRI" 64965 "ECUID" 64981 "EEC5" 65039 "LC" 65099 "TCFG2" 65109 "GFD" 65127 "CCC" 65131 "DI" 65136 "CVW" 65144 "TP1" 65145 "TP2" 65146 "TP3" 65195 "ETC6" 65196 "EBC4" 65199 "GFC" 65201 "EH" 65202 "GFI1" 65203 "LFI1" 65208 "GTFI" 65212 "CBI" 65214 "EEC4" 65216 "SERV" 65219 "ETC5" 65221 "ETC4" 65223 "ETC3" 65227 "DM02" 65228 "DM03" 65229 "DM04" 65230 "DM05" 65231 "DM06" 65234 "DM10" 65235 "DM11" 65236 "DM12" 65242 "SOFT" 65244 "IO" 65248 "VD" 65250 "TCFG" 65253 "HOURS" 65254 "TD" 65255 "VH" 65256 "VDS" 65257 "LFC1" 65258 "VW" 65259 "CI" 65260 "VI" 65261 "CCSS" 65284 "PB_DriversConsentOnPersonalData" 65340 "PB_HVESSCFG" 65376 "VehCfg" 65413 "PB_3CT" 65482 "PB_ID1" 65484 "PB_VNS" 65502 "Av2" 65520 "SCh" 65521 "DIS" 65524 "PB_IVA" ;
VAL_ 2565406598 Pgn_Nack_E8FF86 37120 "VLSI1" 40448 "DM29" 41216 "DM33" 41728 "DM31" 41984 "DM30" 47360 "PLLT (Plan List Lifetime)" 47872 "PLD (Plan List Distance)" 49408 "DM21" 49664 "DM20" 49920 "DM22" 53504 "MaintBcIc" 54016 "DM19" 60928 "ACL" 61184 "STOD" 64341 "HVESP3HIST" 64342 "HVESP3CFG" 64343 "HVESP2HIST" 64344 "HVESP2CFG" 64345 "HVESP1HIST" 64346 "HVESP1CFG" 64529 "TGFI" 64579 "TCSI" 64582 "TSIS" 64583 "MTI" 64605 "HVESSCFG" 64606 "HVESSHIST" 64653 "PII" 64701 "A1SCRSI2" 64782 "AT1OGC2" 64784 "AT1IGC2" 64839 "TML" 64879 "EEC8" 64896 "DM28" 64905 "VDS2" 64906 "J2012" 64912 "AETC" 64920 "AT1HI1" 64949 "DM23" 64950 "DM24" 64951 "DM25" 64952 "DM26" 64953 "TPRI" 64965 "ECUID" 64981 "EEC5" 65039 "LC" 65099 "TCFG2" 65109 "GFD" 65127 "CCC" 65131 "DI" 65136 "CVW" 65144 "TP1" 65145 "TP2" 65146 "TP3" 65195 "ETC6" 65196 "EBC4" 65199 "GFC" 65201 "EH" 65202 "GFI1" 65203 "LFI1" 65208 "GTFI" 65212 "CBI" 65214 "EEC4" 65216 "SERV" 65219 "ETC5" 65221 "ETC4" 65223 "ETC3" 65227 "DM02" 65228 "DM03" 65229 "DM04" 65230 "DM05" 65231 "DM06" 65234 "DM10" 65235 "DM11" 65236 "DM12" 65242 "SOFT" 65244 "IO" 65248 "VD" 65250 "TCFG" 65253 "HOURS" 65254 "TD" 65255 "VH" 65256 "VDS" 65257 "LFC1" 65258 "VW" 65259 "CI" 65260 "VI" 65261 "CCSS" 65284 "PB_DriversConsentOnPersonalData" 65340 "PB_HVESSCFG" 65376 "VehCfg" 65413 "PB_3CT" 65482 "PB_ID1" 65484 "PB_VNS" 65502 "Av2" 65520 "SCh" 65521 "DIS" 65524 "PB_IVA" ;
VAL_ 2565406598 Pgn_Ad_E8FF86 37120 "VLSI1" 40448 "DM29" 41216 "DM33" 41728 "DM31" 41984 "DM30" 47360 "PLLT (Plan List Lifetime)" 47872 "PLD (Plan List Distance)" 49408 "DM21" 49664 "DM20" 49920 "DM22" 53504 "MaintBcIc" 54016 "DM19" 60928 "ACL" 61184 "STOD" 64341 "HVESP3HIST" 64342 "HVESP3CFG" 64343 "HVESP2HIST" 64344 "HVESP2CFG" 64345 "HVESP1HIST" 64346 "HVESP1CFG" 64529 "TGFI" 64579 "TCSI" 64582 "TSIS" 64583 "MTI" 64605 "HVESSCFG" 64606 "HVESSHIST" 64653 "PII" 64701 "A1SCRSI2" 64782 "AT1OGC2" 64784 "AT1IGC2" 64839 "TML" 64879 "EEC8" 64896 "DM28" 64905 "VDS2" 64906 "J2012" 64912 "AETC" 64920 "AT1HI1" 64949 "DM23" 64950 "DM24" 64951 "DM25" 64952 "DM26" 64953 "TPRI" 64965 "ECUID" 64981 "EEC5" 65039 "LC" 65099 "TCFG2" 65109 "GFD" 65127 "CCC" 65131 "DI" 65136 "CVW" 65144 "TP1" 65145 "TP2" 65146 "TP3" 65195 "ETC6" 65196 "EBC4" 65199 "GFC" 65201 "EH" 65202 "GFI1" 65203 "LFI1" 65208 "GTFI" 65212 "CBI" 65214 "EEC4" 65216 "SERV" 65219 "ETC5" 65221 "ETC4" 65223 "ETC3" 65227 "DM02" 65228 "DM03" 65229 "DM04" 65230 "DM05" 65231 "DM06" 65234 "DM10" 65235 "DM11" 65236 "DM12" 65242 "SOFT" 65244 "IO" 65248 "VD" 65250 "TCFG" 65253 "HOURS" 65254 "TD" 65255 "VH" 65256 "VDS" 65257 "LFC1" 65258 "VW" 65259 "CI" 65260 "VI" 65261 "CCSS" 65284 "PB_DriversConsentOnPersonalData" 65340 "PB_HVESSCFG" 65376 "VehCfg" 65413 "PB_3CT" 65482 "PB_ID1" 65484 "PB_VNS" 65502 "Av2" 65520 "SCh" 65521 "DIS" 65524 "PB_IVA" ;
VAL_ 2565406598 Pgn_Busy_E8FF86 37120 "VLSI1" 40448 "DM29" 41216 "DM33" 41728 "DM31" 41984 "DM30" 47360 "PLLT (Plan List Lifetime)" 47872 "PLD (Plan List Distance)" 49408 "DM21" 49664 "DM20" 49920 "DM22" 53504 "MaintBcIc" 54016 "DM19" 60928 "ACL" 61184 "STOD" 64341 "HVESP3HIST" 64342 "HVESP3CFG" 64343 "HVESP2HIST" 64344 "HVESP2CFG" 64345 "HVESP1HIST" 64346 "HVESP1CFG" 64529 "TGFI" 64579 "TCSI" 64582 "TSIS" 64583 "MTI" 64605 "HVESSCFG" 64606 "HVESSHIST" 64653 "PII" 64701 "A1SCRSI2" 64782 "AT1OGC2" 64784 "AT1IGC2" 64839 "TML" 64879 "EEC8" 64896 "DM28" 64905 "VDS2" 64906 "J2012" 64912 "AETC" 64920 "AT1HI1" 64949 "DM23" 64950 "DM24" 64951 "DM25" 64952 "DM26" 64953 "TPRI" 64965 "ECUID" 64981 "EEC5" 65039 "LC" 65099 "TCFG2" 65109 "GFD" 65127 "CCC" 65131 "DI" 65136 "CVW" 65144 "TP1" 65145 "TP2" 65146 "TP3" 65195 "ETC6" 65196 "EBC4" 65199 "GFC" 65201 "EH" 65202 "GFI1" 65203 "LFI1" 65208 "GTFI" 65212 "CBI" 65214 "EEC4" 65216 "SERV" 65219 "ETC5" 65221 "ETC4" 65223 "ETC3" 65227 "DM02" 65228 "DM03" 65229 "DM04" 65230 "DM05" 65231 "DM06" 65234 "DM10" 65235 "DM11" 65236 "DM12" 65242 "SOFT" 65244 "IO" 65248 "VD" 65250 "TCFG" 65253 "HOURS" 65254 "TD" 65255 "VH" 65256 "VDS" 65257 "LFC1" 65258 "VW" 65259 "CI" 65260 "VI" 65261 "CCSS" 65284 "PB_DriversConsentOnPersonalData" 65340 "PB_HVESSCFG" 65376 "VehCfg" 65413 "PB_3CT" 65482 "PB_ID1" 65484 "PB_VNS" 65502 "Av2" 65520 "SCh" 65521 "DIS" 65524 "PB_IVA" ;
VAL_ 2565406599 Pgn_Ack_E8FF87 37120 "VLSI1" 40448 "DM29" 41216 "DM33" 41728 "DM31" 41984 "DM30" 47360 "PLLT (Plan List Lifetime)" 47872 "PLD (Plan List Distance)" 49408 "DM21" 49664 "DM20" 49920 "DM22" 53504 "MaintBcIc" 54016 "DM19" 60928 "ACL" 61184 "STOD" 64341 "HVESP3HIST" 64342 "HVESP3CFG" 64343 "HVESP2HIST" 64344 "HVESP2CFG" 64345 "HVESP1HIST" 64346 "HVESP1CFG" 64529 "TGFI" 64579 "TCSI" 64582 "TSIS" 64583 "MTI" 64605 "HVESSCFG" 64606 "HVESSHIST" 64653 "PII" 64701 "A1SCRSI2" 64782 "AT1OGC2" 64784 "AT1IGC2" 64839 "TML" 64879 "EEC8" 64896 "DM28" 64905 "VDS2" 64906 "J2012" 64912 "AETC" 64920 "AT1HI1" 64949 "DM23" 64950 "DM24" 64951 "DM25" 64952 "DM26" 64953 "TPRI" 64965 "ECUID" 64981 "EEC5" 65039 "LC" 65099 "TCFG2" 65109 "GFD" 65127 "CCC" 65131 "DI" 65136 "CVW" 65144 "TP1" 65145 "TP2" 65146 "TP3" 65195 "ETC6" 65196 "EBC4" 65199 "GFC" 65201 "EH" 65202 "GFI1" 65203 "LFI1" 65208 "GTFI" 65212 "CBI" 65214 "EEC4" 65216 "SERV" 65219 "ETC5" 65221 "ETC4" 65223 "ETC3" 65227 "DM02" 65228 "DM03" 65229 "DM04" 65230 "DM05" 65231 "DM06" 65234 "DM10" 65235 "DM11" 65236 "DM12" 65242 "SOFT" 65244 "IO" 65248 "VD" 65250 "TCFG" 65253 "HOURS" 65254 "TD" 65255 "VH" 65256 "VDS" 65257 "LFC1" 65258 "VW" 65259 "CI" 65260 "VI" 65261 "CCSS" 65284 "PB_DriversConsentOnPersonalData" 65340 "PB_HVESSCFG" 65376 "VehCfg" 65413 "PB_3CT" 65482 "PB_ID1" 65484 "PB_VNS" 65502 "Av2" 65520 "SCh" 65521 "DIS" 65524 "PB_IVA" ;
VAL_ 2565406599 Pgn_Nack_E8FF87 37120 "VLSI1" 40448 "DM29" 41216 "DM33" 41728 "DM31" 41984 "DM30" 47360 "PLLT (Plan List Lifetime)" 47872 "PLD (Plan List Distance)" 49408 "DM21" 49664 "DM20" 49920 "DM22" 53504 "MaintBcIc" 54016 "DM19" 60928 "ACL" 61184 "STOD" 64341 "HVESP3HIST" 64342 "HVESP3CFG" 64343 "HVESP2HIST" 64344 "HVESP2CFG" 64345 "HVESP1HIST" 64346 "HVESP1CFG" 64529 "TGFI" 64579 "TCSI" 64582 "TSIS" 64583 "MTI" 64605 "HVESSCFG" 64606 "HVESSHIST" 64653 "PII" 64701 "A1SCRSI2" 64782 "AT1OGC2" 64784 "AT1IGC2" 64839 "TML" 64879 "EEC8" 64896 "DM28" 64905 "VDS2" 64906 "J2012" 64912 "AETC" 64920 "AT1HI1" 64949 "DM23" 64950 "DM24" 64951 "DM25" 64952 "DM26" 64953 "TPRI" 64965 "ECUID" 64981 "EEC5" 65039 "LC" 65099 "TCFG2" 65109 "GFD" 65127 "CCC" 65131 "DI" 65136 "CVW" 65144 "TP1" 65145 "TP2" 65146 "TP3" 65195 "ETC6" 65196 "EBC4" 65199 "GFC" 65201 "EH" 65202 "GFI1" 65203 "LFI1" 65208 "GTFI" 65212 "CBI" 65214 "EEC4" 65216 "SERV" 65219 "ETC5" 65221 "ETC4" 65223 "ETC3" 65227 "DM02" 65228 "DM03" 65229 "DM04" 65230 "DM05" 65231 "DM06" 65234 "DM10" 65235 "DM11" 65236 "DM12" 65242 "SOFT" 65244 "IO" 65248 "VD" 65250 "TCFG" 65253 "HOURS" 65254 "TD" 65255 "VH" 65256 "VDS" 65257 "LFC1" 65258 "VW" 65259 "CI" 65260 "VI" 65261 "CCSS" 65284 "PB_DriversConsentOnPersonalData" 65340 "PB_HVESSCFG" 65376 "VehCfg" 65413 "PB_3CT" 65482 "PB_ID1" 65484 "PB_VNS" 65502 "Av2" 65520 "SCh" 65521 "DIS" 65524 "PB_IVA" ;
VAL_ 2565406599 Pgn_Ad_E8FF87 37120 "VLSI1" 40448 "DM29" 41216 "DM33" 41728 "DM31" 41984 "DM30" 47360 "PLLT (Plan List Lifetime)" 47872 "PLD (Plan List Distance)" 49408 "DM21" 49664 "DM20" 49920 "DM22" 53504 "MaintBcIc" 54016 "DM19" 60928 "ACL" 61184 "STOD" 64341 "HVESP3HIST" 64342 "HVESP3CFG" 64343 "HVESP2HIST" 64344 "HVESP2CFG" 64345 "HVESP1HIST" 64346 "HVESP1CFG" 64529 "TGFI" 64579 "TCSI" 64582 "TSIS" 64583 "MTI" 64605 "HVESSCFG" 64606 "HVESSHIST" 64653 "PII" 64701 "A1SCRSI2" 64782 "AT1OGC2" 64784 "AT1IGC2" 64839 "TML" 64879 "EEC8" 64896 "DM28" 64905 "VDS2" 64906 "J2012" 64912 "AETC" 64920 "AT1HI1" 64949 "DM23" 64950 "DM24" 64951 "DM25" 64952 "DM26" 64953 "TPRI" 64965 "ECUID" 64981 "EEC5" 65039 "LC" 65099 "TCFG2" 65109 "GFD" 65127 "CCC" 65131 "DI" 65136 "CVW" 65144 "TP1" 65145 "TP2" 65146 "TP3" 65195 "ETC6" 65196 "EBC4" 65199 "GFC" 65201 "EH" 65202 "GFI1" 65203 "LFI1" 65208 "GTFI" 65212 "CBI" 65214 "EEC4" 65216 "SERV" 65219 "ETC5" 65221 "ETC4" 65223 "ETC3" 65227 "DM02" 65228 "DM03" 65229 "DM04" 65230 "DM05" 65231 "DM06" 65234 "DM10" 65235 "DM11" 65236 "DM12" 65242 "SOFT" 65244 "IO" 65248 "VD" 65250 "TCFG" 65253 "HOURS" 65254 "TD" 65255 "VH" 65256 "VDS" 65257 "LFC1" 65258 "VW" 65259 "CI" 65260 "VI" 65261 "CCSS" 65284 "PB_DriversConsentOnPersonalData" 65340 "PB_HVESSCFG" 65376 "VehCfg" 65413 "PB_3CT" 65482 "PB_ID1" 65484 "PB_VNS" 65502 "Av2" 65520 "SCh" 65521 "DIS" 65524 "PB_IVA" ;
VAL_ 2565406599 Pgn_Busy_E8FF87 37120 "VLSI1" 40448 "DM29" 41216 "DM33" 41728 "DM31" 41984 "DM30" 47360 "PLLT (Plan List Lifetime)" 47872 "PLD (Plan List Distance)" 49408 "DM21" 49664 "DM20" 49920 "DM22" 53504 "MaintBcIc" 54016 "DM19" 60928 "ACL" 61184 "STOD" 64341 "HVESP3HIST" 64342 "HVESP3CFG" 64343 "HVESP2HIST" 64344 "HVESP2CFG" 64345 "HVESP1HIST" 64346 "HVESP1CFG" 64529 "TGFI" 64579 "TCSI" 64582 "TSIS" 64583 "MTI" 64605 "HVESSCFG" 64606 "HVESSHIST" 64653 "PII" 64701 "A1SCRSI2" 64782 "AT1OGC2" 64784 "AT1IGC2" 64839 "TML" 64879 "EEC8" 64896 "DM28" 64905 "VDS2" 64906 "J2012" 64912 "AETC" 64920 "AT1HI1" 64949 "DM23" 64950 "DM24" 64951 "DM25" 64952 "DM26" 64953 "TPRI" 64965 "ECUID" 64981 "EEC5" 65039 "LC" 65099 "TCFG2" 65109 "GFD" 65127 "CCC" 65131 "DI" 65136 "CVW" 65144 "TP1" 65145 "TP2" 65146 "TP3" 65195 "ETC6" 65196 "EBC4" 65199 "GFC" 65201 "EH" 65202 "GFI1" 65203 "LFI1" 65208 "GTFI" 65212 "CBI" 65214 "EEC4" 65216 "SERV" 65219 "ETC5" 65221 "ETC4" 65223 "ETC3" 65227 "DM02" 65228 "DM03" 65229 "DM04" 65230 "DM05" 65231 "DM06" 65234 "DM10" 65235 "DM11" 65236 "DM12" 65242 "SOFT" 65244 "IO" 65248 "VD" 65250 "TCFG" 65253 "HOURS" 65254 "TD" 65255 "VH" 65256 "VDS" 65257 "LFC1" 65258 "VW" 65259 "CI" 65260 "VI" 65261 "CCSS" 65284 "PB_DriversConsentOnPersonalData" 65340 "PB_HVESSCFG" 65376 "VehCfg" 65413 "PB_3CT" 65482 "PB_ID1" 65484 "PB_VNS" 65502 "Av2" 65520 "SCh" 65521 "DIS" 65524 "PB_IVA" ;
VAL_ 2565406702 Pgn_Ack_E8FFEE 37120 "VLSI1" 40448 "DM29" 41216 "DM33" 41728 "DM31" 41984 "DM30" 47360 "PLLT (Plan List Lifetime)" 47872 "PLD (Plan List Distance)" 49408 "DM21" 49664 "DM20" 49920 "DM22" 53504 "MaintBcIc" 54016 "DM19" 60928 "ACL" 61184 "STOD" 64341 "HVESP3HIST" 64342 "HVESP3CFG" 64343 "HVESP2HIST" 64344 "HVESP2CFG" 64345 "HVESP1HIST" 64346 "HVESP1CFG" 64529 "TGFI" 64579 "TCSI" 64582 "TSIS" 64583 "MTI" 64605 "HVESSCFG" 64606 "HVESSHIST" 64653 "PII" 64701 "A1SCRSI2" 64782 "AT1OGC2" 64784 "AT1IGC2" 64839 "TML" 64879 "EEC8" 64896 "DM28" 64905 "VDS2" 64906 "J2012" 64912 "AETC" 64920 "AT1HI1" 64949 "DM23" 64950 "DM24" 64951 "DM25" 64952 "DM26" 64953 "TPRI" 64965 "ECUID" 64981 "EEC5" 65039 "LC" 65099 "TCFG2" 65109 "GFD" 65127 "CCC" 65131 "DI" 65136 "CVW" 65144 "TP1" 65145 "TP2" 65146 "TP3" 65195 "ETC6" 65196 "EBC4" 65199 "GFC" 65201 "EH" 65202 "GFI1" 65203 "LFI1" 65208 "GTFI" 65212 "CBI" 65214 "EEC4" 65216 "SERV" 65219 "ETC5" 65221 "ETC4" 65223 "ETC3" 65227 "DM02" 65228 "DM03" 65229 "DM04" 65230 "DM05" 65231 "DM06" 65234 "DM10" 65235 "DM11" 65236 "DM12" 65242 "SOFT" 65244 "IO" 65248 "VD" 65250 "TCFG" 65253 "HOURS" 65254 "TD" 65255 "VH" 65256 "VDS" 65257 "LFC1" 65258 "VW" 65259 "CI" 65260 "VI" 65261 "CCSS" 65284 "PB_DriversConsentOnPersonalData" 65340 "PB_HVESSCFG" 65376 "VehCfg" 65413 "PB_3CT" 65482 "PB_ID1" 65484 "PB_VNS" 65502 "Av2" 65520 "SCh" 65521 "DIS" 65524 "PB_IVA" ;
VAL_ 2565406702 Pgn_Nack_E8FFEE 37120 "VLSI1" 40448 "DM29" 41216 "DM33" 41728 "DM31" 41984 "DM30" 47360 "PLLT (Plan List Lifetime)" 47872 "PLD (Plan List Distance)" 49408 "DM21" 49664 "DM20" 49920 "DM22" 53504 "MaintBcIc" 54016 "DM19" 60928 "ACL" 61184 "STOD" 64341 "HVESP3HIST" 64342 "HVESP3CFG" 64343 "HVESP2HIST" 64344 "HVESP2CFG" 64345 "HVESP1HIST" 64346 "HVESP1CFG" 64529 "TGFI" 64579 "TCSI" 64582 "TSIS" 64583 "MTI" 64605 "HVESSCFG" 64606 "HVESSHIST" 64653 "PII" 64701 "A1SCRSI2" 64782 "AT1OGC2" 64784 "AT1IGC2" 64839 "TML" 64879 "EEC8" 64896 "DM28" 64905 "VDS2" 64906 "J2012" 64912 "AETC" 64920 "AT1HI1" 64949 "DM23" 64950 "DM24" 64951 "DM25" 64952 "DM26" 64953 "TPRI" 64965 "ECUID" 64981 "EEC5" 65039 "LC" 65099 "TCFG2" 65109 "GFD" 65127 "CCC" 65131 "DI" 65136 "CVW" 65144 "TP1" 65145 "TP2" 65146 "TP3" 65195 "ETC6" 65196 "EBC4" 65199 "GFC" 65201 "EH" 65202 "GFI1" 65203 "LFI1" 65208 "GTFI" 65212 "CBI" 65214 "EEC4" 65216 "SERV" 65219 "ETC5" 65221 "ETC4" 65223 "ETC3" 65227 "DM02" 65228 "DM03" 65229 "DM04" 65230 "DM05" 65231 "DM06" 65234 "DM10" 65235 "DM11" 65236 "DM12" 65242 "SOFT" 65244 "IO" 65248 "VD" 65250 "TCFG" 65253 "HOURS" 65254 "TD" 65255 "VH" 65256 "VDS" 65257 "LFC1" 65258 "VW" 65259 "CI" 65260 "VI" 65261 "CCSS" 65284 "PB_DriversConsentOnPersonalData" 65340 "PB_HVESSCFG" 65376 "VehCfg" 65413 "PB_3CT" 65482 "PB_ID1" 65484 "PB_VNS" 65502 "Av2" 65520 "SCh" 65521 "DIS" 65524 "PB_IVA" ;
VAL_ 2565406702 Pgn_Ad_E8FFEE 37120 "VLSI1" 40448 "DM29" 41216 "DM33" 41728 "DM31" 41984 "DM30" 47360 "PLLT (Plan List Lifetime)" 47872 "PLD (Plan List Distance)" 49408 "DM21" 49664 "DM20" 49920 "DM22" 53504 "MaintBcIc" 54016 "DM19" 60928 "ACL" 61184 "STOD" 64341 "HVESP3HIST" 64342 "HVESP3CFG" 64343 "HVESP2HIST" 64344 "HVESP2CFG" 64345 "HVESP1HIST" 64346 "HVESP1CFG" 64529 "TGFI" 64579 "TCSI" 64582 "TSIS" 64583 "MTI" 64605 "HVESSCFG" 64606 "HVESSHIST" 64653 "PII" 64701 "A1SCRSI2" 64782 "AT1OGC2" 64784 "AT1IGC2" 64839 "TML" 64879 "EEC8" 64896 "DM28" 64905 "VDS2" 64906 "J2012" 64912 "AETC" 64920 "AT1HI1" 64949 "DM23" 64950 "DM24" 64951 "DM25" 64952 "DM26" 64953 "TPRI" 64965 "ECUID" 64981 "EEC5" 65039 "LC" 65099 "TCFG2" 65109 "GFD" 65127 "CCC" 65131 "DI" 65136 "CVW" 65144 "TP1" 65145 "TP2" 65146 "TP3" 65195 "ETC6" 65196 "EBC4" 65199 "GFC" 65201 "EH" 65202 "GFI1" 65203 "LFI1" 65208 "GTFI" 65212 "CBI" 65214 "EEC4" 65216 "SERV" 65219 "ETC5" 65221 "ETC4" 65223 "ETC3" 65227 "DM02" 65228 "DM03" 65229 "DM04" 65230 "DM05" 65231 "DM06" 65234 "DM10" 65235 "DM11" 65236 "DM12" 65242 "SOFT" 65244 "IO" 65248 "VD" 65250 "TCFG" 65253 "HOURS" 65254 "TD" 65255 "VH" 65256 "VDS" 65257 "LFC1" 65258 "VW" 65259 "CI" 65260 "VI" 65261 "CCSS" 65284 "PB_DriversConsentOnPersonalData" 65340 "PB_HVESSCFG" 65376 "VehCfg" 65413 "PB_3CT" 65482 "PB_ID1" 65484 "PB_VNS" 65502 "Av2" 65520 "SCh" 65521 "DIS" 65524 "PB_IVA" ;
VAL_ 2565406702 Pgn_Busy_E8FFEE 37120 "VLSI1" 40448 "DM29" 41216 "DM33" 41728 "DM31" 41984 "DM30" 47360 "PLLT (Plan List Lifetime)" 47872 "PLD (Plan List Distance)" 49408 "DM21" 49664 "DM20" 49920 "DM22" 53504 "MaintBcIc" 54016 "DM19" 60928 "ACL" 61184 "STOD" 64341 "HVESP3HIST" 64342 "HVESP3CFG" 64343 "HVESP2HIST" 64344 "HVESP2CFG" 64345 "HVESP1HIST" 64346 "HVESP1CFG" 64529 "TGFI" 64579 "TCSI" 64582 "TSIS" 64583 "MTI" 64605 "HVESSCFG" 64606 "HVESSHIST" 64653 "PII" 64701 "A1SCRSI2" 64782 "AT1OGC2" 64784 "AT1IGC2" 64839 "TML" 64879 "EEC8" 64896 "DM28" 64905 "VDS2" 64906 "J2012" 64912 "AETC" 64920 "AT1HI1" 64949 "DM23" 64950 "DM24" 64951 "DM25" 64952 "DM26" 64953 "TPRI" 64965 "ECUID" 64981 "EEC5" 65039 "LC" 65099 "TCFG2" 65109 "GFD" 65127 "CCC" 65131 "DI" 65136 "CVW" 65144 "TP1" 65145 "TP2" 65146 "TP3" 65195 "ETC6" 65196 "EBC4" 65199 "GFC" 65201 "EH" 65202 "GFI1" 65203 "LFI1" 65208 "GTFI" 65212 "CBI" 65214 "EEC4" 65216 "SERV" 65219 "ETC5" 65221 "ETC4" 65223 "ETC3" 65227 "DM02" 65228 "DM03" 65229 "DM04" 65230 "DM05" 65231 "DM06" 65234 "DM10" 65235 "DM11" 65236 "DM12" 65242 "SOFT" 65244 "IO" 65248 "VD" 65250 "TCFG" 65253 "HOURS" 65254 "TD" 65255 "VH" 65256 "VDS" 65257 "LFC1" 65258 "VW" 65259 "CI" 65260 "VI" 65261 "CCSS" 65284 "PB_DriversConsentOnPersonalData" 65340 "PB_HVESSCFG" 65376 "VehCfg" 65413 "PB_3CT" 65482 "PB_ID1" 65484 "PB_VNS" 65502 "Av2" 65520 "SCh" 65521 "DIS" 65524 "PB_IVA" ;
VAL_ 2565406703 Pgn_Ack_E8FFEF 37120 "VLSI1" 40448 "DM29" 41216 "DM33" 41728 "DM31" 41984 "DM30" 47360 "PLLT (Plan List Lifetime)" 47872 "PLD (Plan List Distance)" 49408 "DM21" 49664 "DM20" 49920 "DM22" 53504 "MaintBcIc" 54016 "DM19" 60928 "ACL" 61184 "STOD" 64341 "HVESP3HIST" 64342 "HVESP3CFG" 64343 "HVESP2HIST" 64344 "HVESP2CFG" 64345 "HVESP1HIST" 64346 "HVESP1CFG" 64529 "TGFI" 64579 "TCSI" 64582 "TSIS" 64583 "MTI" 64605 "HVESSCFG" 64606 "HVESSHIST" 64653 "PII" 64701 "A1SCRSI2" 64782 "AT1OGC2" 64784 "AT1IGC2" 64839 "TML" 64879 "EEC8" 64896 "DM28" 64905 "VDS2" 64906 "J2012" 64912 "AETC" 64920 "AT1HI1" 64949 "DM23" 64950 "DM24" 64951 "DM25" 64952 "DM26" 64953 "TPRI" 64965 "ECUID" 64981 "EEC5" 65039 "LC" 65099 "TCFG2" 65109 "GFD" 65127 "CCC" 65131 "DI" 65136 "CVW" 65144 "TP1" 65145 "TP2" 65146 "TP3" 65195 "ETC6" 65196 "EBC4" 65199 "GFC" 65201 "EH" 65202 "GFI1" 65203 "LFI1" 65208 "GTFI" 65212 "CBI" 65214 "EEC4" 65216 "SERV" 65219 "ETC5" 65221 "ETC4" 65223 "ETC3" 65227 "DM02" 65228 "DM03" 65229 "DM04" 65230 "DM05" 65231 "DM06" 65234 "DM10" 65235 "DM11" 65236 "DM12" 65242 "SOFT" 65244 "IO" 65248 "VD" 65250 "TCFG" 65253 "HOURS" 65254 "TD" 65255 "VH" 65256 "VDS" 65257 "LFC1" 65258 "VW" 65259 "CI" 65260 "VI" 65261 "CCSS" 65284 "PB_DriversConsentOnPersonalData" 65340 "PB_HVESSCFG" 65376 "VehCfg" 65413 "PB_3CT" 65482 "PB_ID1" 65484 "PB_VNS" 65502 "Av2" 65520 "SCh" 65521 "DIS" 65524 "PB_IVA" ;
VAL_ 2565406703 Pgn_Nack_E8FFEF 37120 "VLSI1" 40448 "DM29" 41216 "DM33" 41728 "DM31" 41984 "DM30" 47360 "PLLT (Plan List Lifetime)" 47872 "PLD (Plan List Distance)" 49408 "DM21" 49664 "DM20" 49920 "DM22" 53504 "MaintBcIc" 54016 "DM19" 60928 "ACL" 61184 "STOD" 64341 "HVESP3HIST" 64342 "HVESP3CFG" 64343 "HVESP2HIST" 64344 "HVESP2CFG" 64345 "HVESP1HIST" 64346 "HVESP1CFG" 64529 "TGFI" 64579 "TCSI" 64582 "TSIS" 64583 "MTI" 64605 "HVESSCFG" 64606 "HVESSHIST" 64653 "PII" 64701 "A1SCRSI2" 64782 "AT1OGC2" 64784 "AT1IGC2" 64839 "TML" 64879 "EEC8" 64896 "DM28" 64905 "VDS2" 64906 "J2012" 64912 "AETC" 64920 "AT1HI1" 64949 "DM23" 64950 "DM24" 64951 "DM25" 64952 "DM26" 64953 "TPRI" 64965 "ECUID" 64981 "EEC5" 65039 "LC" 65099 "TCFG2" 65109 "GFD" 65127 "CCC" 65131 "DI" 65136 "CVW" 65144 "TP1" 65145 "TP2" 65146 "TP3" 65195 "ETC6" 65196 "EBC4" 65199 "GFC" 65201 "EH" 65202 "GFI1" 65203 "LFI1" 65208 "GTFI" 65212 "CBI" 65214 "EEC4" 65216 "SERV" 65219 "ETC5" 65221 "ETC4" 65223 "ETC3" 65227 "DM02" 65228 "DM03" 65229 "DM04" 65230 "DM05" 65231 "DM06" 65234 "DM10" 65235 "DM11" 65236 "DM12" 65242 "SOFT" 65244 "IO" 65248 "VD" 65250 "TCFG" 65253 "HOURS" 65254 "TD" 65255 "VH" 65256 "VDS" 65257 "LFC1" 65258 "VW" 65259 "CI" 65260 "VI" 65261 "CCSS" 65284 "PB_DriversConsentOnPersonalData" 65340 "PB_HVESSCFG" 65376 "VehCfg" 65413 "PB_3CT" 65482 "PB_ID1" 65484 "PB_VNS" 65502 "Av2" 65520 "SCh" 65521 "DIS" 65524 "PB_IVA" ;
VAL_ 2565406703 Pgn_Ad_E8FFEF 37120 "VLSI1" 40448 "DM29" 41216 "DM33" 41728 "DM31" 41984 "DM30" 47360 "PLLT (Plan List Lifetime)" 47872 "PLD (Plan List Distance)" 49408 "DM21" 49664 "DM20" 49920 "DM22" 53504 "MaintBcIc" 54016 "DM19" 60928 "ACL" 61184 "STOD" 64341 "HVESP3HIST" 64342 "HVESP3CFG" 64343 "HVESP2HIST" 64344 "HVESP2CFG" 64345 "HVESP1HIST" 64346 "HVESP1CFG" 64529 "TGFI" 64579 "TCSI" 64582 "TSIS" 64583 "MTI" 64605 "HVESSCFG" 64606 "HVESSHIST" 64653 "PII" 64701 "A1SCRSI2" 64782 "AT1OGC2" 64784 "AT1IGC2" 64839 "TML" 64879 "EEC8" 64896 "DM28" 64905 "VDS2" 64906 "J2012" 64912 "AETC" 64920 "AT1HI1" 64949 "DM23" 64950 "DM24" 64951 "DM25" 64952 "DM26" 64953 "TPRI" 64965 "ECUID" 64981 "EEC5" 65039 "LC" 65099 "TCFG2" 65109 "GFD" 65127 "CCC" 65131 "DI" 65136 "CVW" 65144 "TP1" 65145 "TP2" 65146 "TP3" 65195 "ETC6" 65196 "EBC4" 65199 "GFC" 65201 "EH" 65202 "GFI1" 65203 "LFI1" 65208 "GTFI" 65212 "CBI" 65214 "EEC4" 65216 "SERV" 65219 "ETC5" 65221 "ETC4" 65223 "ETC3" 65227 "DM02" 65228 "DM03" 65229 "DM04" 65230 "DM05" 65231 "DM06" 65234 "DM10" 65235 "DM11" 65236 "DM12" 65242 "SOFT" 65244 "IO" 65248 "VD" 65250 "TCFG" 65253 "HOURS" 65254 "TD" 65255 "VH" 65256 "VDS" 65257 "LFC1" 65258 "VW" 65259 "CI" 65260 "VI" 65261 "CCSS" 65284 "PB_DriversConsentOnPersonalData" 65340 "PB_HVESSCFG" 65376 "VehCfg" 65413 "PB_3CT" 65482 "PB_ID1" 65484 "PB_VNS" 65502 "Av2" 65520 "SCh" 65521 "DIS" 65524 "PB_IVA" ;
VAL_ 2565406703 Pgn_Busy_E8FFEF 37120 "VLSI1" 40448 "DM29" 41216 "DM33" 41728 "DM31" 41984 "DM30" 47360 "PLLT (Plan List Lifetime)" 47872 "PLD (Plan List Distance)" 49408 "DM21" 49664 "DM20" 49920 "DM22" 53504 "MaintBcIc" 54016 "DM19" 60928 "ACL" 61184 "STOD" 64341 "HVESP3HIST" 64342 "HVESP3CFG" 64343 "HVESP2HIST" 64344 "HVESP2CFG" 64345 "HVESP1HIST" 64346 "HVESP1CFG" 64529 "TGFI" 64579 "TCSI" 64582 "TSIS" 64583 "MTI" 64605 "HVESSCFG" 64606 "HVESSHIST" 64653 "PII" 64701 "A1SCRSI2" 64782 "AT1OGC2" 64784 "AT1IGC2" 64839 "TML" 64879 "EEC8" 64896 "DM28" 64905 "VDS2" 64906 "J2012" 64912 "AETC" 64920 "AT1HI1" 64949 "DM23" 64950 "DM24" 64951 "DM25" 64952 "DM26" 64953 "TPRI" 64965 "ECUID" 64981 "EEC5" 65039 "LC" 65099 "TCFG2" 65109 "GFD" 65127 "CCC" 65131 "DI" 65136 "CVW" 65144 "TP1" 65145 "TP2" 65146 "TP3" 65195 "ETC6" 65196 "EBC4" 65199 "GFC" 65201 "EH" 65202 "GFI1" 65203 "LFI1" 65208 "GTFI" 65212 "CBI" 65214 "EEC4" 65216 "SERV" 65219 "ETC5" 65221 "ETC4" 65223 "ETC3" 65227 "DM02" 65228 "DM03" 65229 "DM04" 65230 "DM05" 65231 "DM06" 65234 "DM10" 65235 "DM11" 65236 "DM12" 65242 "SOFT" 65244 "IO" 65248 "VD" 65250 "TCFG" 65253 "HOURS" 65254 "TD" 65255 "VH" 65256 "VDS" 65257 "LFC1" 65258 "VW" 65259 "CI" 65260 "VI" 65261 "CCSS" 65284 "PB_DriversConsentOnPersonalData" 65340 "PB_HVESSCFG" 65376 "VehCfg" 65413 "PB_3CT" 65482 "PB_ID1" 65484 "PB_VNS" 65502 "Av2" 65520 "SCh" 65521 "DIS" 65524 "PB_IVA" ;
VAL_ 2565406706 Pgn_Ack_E8FFF2 37120 "VLSI1" 40448 "DM29" 41216 "DM33" 41728 "DM31" 41984 "DM30" 47360 "PLLT (Plan List Lifetime)" 47872 "PLD (Plan List Distance)" 49408 "DM21" 49664 "DM20" 49920 "DM22" 53504 "MaintBcIc" 54016 "DM19" 60928 "ACL" 61184 "STOD" 64341 "HVESP3HIST" 64342 "HVESP3CFG" 64343 "HVESP2HIST" 64344 "HVESP2CFG" 64345 "HVESP1HIST" 64346 "HVESP1CFG" 64529 "TGFI" 64579 "TCSI" 64582 "TSIS" 64583 "MTI" 64605 "HVESSCFG" 64606 "HVESSHIST" 64653 "PII" 64701 "A1SCRSI2" 64782 "AT1OGC2" 64784 "AT1IGC2" 64839 "TML" 64879 "EEC8" 64896 "DM28" 64905 "VDS2" 64906 "J2012" 64912 "AETC" 64920 "AT1HI1" 64949 "DM23" 64950 "DM24" 64951 "DM25" 64952 "DM26" 64953 "TPRI" 64965 "ECUID" 64981 "EEC5" 65039 "LC" 65099 "TCFG2" 65109 "GFD" 65127 "CCC" 65131 "DI" 65136 "CVW" 65144 "TP1" 65145 "TP2" 65146 "TP3" 65195 "ETC6" 65196 "EBC4" 65199 "GFC" 65201 "EH" 65202 "GFI1" 65203 "LFI1" 65208 "GTFI" 65212 "CBI" 65214 "EEC4" 65216 "SERV" 65219 "ETC5" 65221 "ETC4" 65223 "ETC3" 65227 "DM02" 65228 "DM03" 65229 "DM04" 65230 "DM05" 65231 "DM06" 65234 "DM10" 65235 "DM11" 65236 "DM12" 65242 "SOFT" 65244 "IO" 65248 "VD" 65250 "TCFG" 65253 "HOURS" 65254 "TD" 65255 "VH" 65256 "VDS" 65257 "LFC1" 65258 "VW" 65259 "CI" 65260 "VI" 65261 "CCSS" 65284 "PB_DriversConsentOnPersonalData" 65340 "PB_HVESSCFG" 65376 "VehCfg" 65413 "PB_3CT" 65482 "PB_ID1" 65484 "PB_VNS" 65502 "Av2" 65520 "SCh" 65521 "DIS" 65524 "PB_IVA" ;
VAL_ 2565406706 Pgn_Nack_E8FFF2 37120 "VLSI1" 40448 "DM29" 41216 "DM33" 41728 "DM31" 41984 "DM30" 47360 "PLLT (Plan List Lifetime)" 47872 "PLD (Plan List Distance)" 49408 "DM21" 49664 "DM20" 49920 "DM22" 53504 "MaintBcIc" 54016 "DM19" 60928 "ACL" 61184 "STOD" 64341 "HVESP3HIST" 64342 "HVESP3CFG" 64343 "HVESP2HIST" 64344 "HVESP2CFG" 64345 "HVESP1HIST" 64346 "HVESP1CFG" 64529 "TGFI" 64579 "TCSI" 64582 "TSIS" 64583 "MTI" 64605 "HVESSCFG" 64606 "HVESSHIST" 64653 "PII" 64701 "A1SCRSI2" 64782 "AT1OGC2" 64784 "AT1IGC2" 64839 "TML" 64879 "EEC8" 64896 "DM28" 64905 "VDS2" 64906 "J2012" 64912 "AETC" 64920 "AT1HI1" 64949 "DM23" 64950 "DM24" 64951 "DM25" 64952 "DM26" 64953 "TPRI" 64965 "ECUID" 64981 "EEC5" 65039 "LC" 65099 "TCFG2" 65109 "GFD" 65127 "CCC" 65131 "DI" 65136 "CVW" 65144 "TP1" 65145 "TP2" 65146 "TP3" 65195 "ETC6" 65196 "EBC4" 65199 "GFC" 65201 "EH" 65202 "GFI1" 65203 "LFI1" 65208 "GTFI" 65212 "CBI" 65214 "EEC4" 65216 "SERV" 65219 "ETC5" 65221 "ETC4" 65223 "ETC3" 65227 "DM02" 65228 "DM03" 65229 "DM04" 65230 "DM05" 65231 "DM06" 65234 "DM10" 65235 "DM11" 65236 "DM12" 65242 "SOFT" 65244 "IO" 65248 "VD" 65250 "TCFG" 65253 "HOURS" 65254 "TD" 65255 "VH" 65256 "VDS" 65257 "LFC1" 65258 "VW" 65259 "CI" 65260 "VI" 65261 "CCSS" 65284 "PB_DriversConsentOnPersonalData" 65340 "PB_HVESSCFG" 65376 "VehCfg" 65413 "PB_3CT" 65482 "PB_ID1" 65484 "PB_VNS" 65502 "Av2" 65520 "SCh" 65521 "DIS" 65524 "PB_IVA" ;
VAL_ 2565406706 Pgn_Ad_E8FFF2 37120 "VLSI1" 40448 "DM29" 41216 "DM33" 41728 "DM31" 41984 "DM30" 47360 "PLLT (Plan List Lifetime)" 47872 "PLD (Plan List Distance)" 49408 "DM21" 49664 "DM20" 49920 "DM22" 53504 "MaintBcIc" 54016 "DM19" 60928 "ACL" 61184 "STOD" 64341 "HVESP3HIST" 64342 "HVESP3CFG" 64343 "HVESP2HIST" 64344 "HVESP2CFG" 64345 "HVESP1HIST" 64346 "HVESP1CFG" 64529 "TGFI" 64579 "TCSI" 64582 "TSIS" 64583 "MTI" 64605 "HVESSCFG" 64606 "HVESSHIST" 64653 "PII" 64701 "A1SCRSI2" 64782 "AT1OGC2" 64784 "AT1IGC2" 64839 "TML" 64879 "EEC8" 64896 "DM28" 64905 "VDS2" 64906 "J2012" 64912 "AETC" 64920 "AT1HI1" 64949 "DM23" 64950 "DM24" 64951 "DM25" 64952 "DM26" 64953 "TPRI" 64965 "ECUID" 64981 "EEC5" 65039 "LC" 65099 "TCFG2" 65109 "GFD" 65127 "CCC" 65131 "DI" 65136 "CVW" 65144 "TP1" 65145 "TP2" 65146 "TP3" 65195 "ETC6" 65196 "EBC4" 65199 "GFC" 65201 "EH" 65202 "GFI1" 65203 "LFI1" 65208 "GTFI" 65212 "CBI" 65214 "EEC4" 65216 "SERV" 65219 "ETC5" 65221 "ETC4" 65223 "ETC3" 65227 "DM02" 65228 "DM03" 65229 "DM04" 65230 "DM05" 65231 "DM06" 65234 "DM10" 65235 "DM11" 65236 "DM12" 65242 "SOFT" 65244 "IO" 65248 "VD" 65250 "TCFG" 65253 "HOURS" 65254 "TD" 65255 "VH" 65256 "VDS" 65257 "LFC1" 65258 "VW" 65259 "CI" 65260 "VI" 65261 "CCSS" 65284 "PB_DriversConsentOnPersonalData" 65340 "PB_HVESSCFG" 65376 "VehCfg" 65413 "PB_3CT" 65482 "PB_ID1" 65484 "PB_VNS" 65502 "Av2" 65520 "SCh" 65521 "DIS" 65524 "PB_IVA" ;
VAL_ 2565406706 Pgn_Busy_E8FFF2 37120 "VLSI1" 40448 "DM29" 41216 "DM33" 41728 "DM31" 41984 "DM30" 47360 "PLLT (Plan List Lifetime)" 47872 "PLD (Plan List Distance)" 49408 "DM21" 49664 "DM20" 49920 "DM22" 53504 "MaintBcIc" 54016 "DM19" 60928 "ACL" 61184 "STOD" 64341 "HVESP3HIST" 64342 "HVESP3CFG" 64343 "HVESP2HIST" 64344 "HVESP2CFG" 64345 "HVESP1HIST" 64346 "HVESP1CFG" 64529 "TGFI" 64579 "TCSI" 64582 "TSIS" 64583 "MTI" 64605 "HVESSCFG" 64606 "HVESSHIST" 64653 "PII" 64701 "A1SCRSI2" 64782 "AT1OGC2" 64784 "AT1IGC2" 64839 "TML" 64879 "EEC8" 64896 "DM28" 64905 "VDS2" 64906 "J2012" 64912 "AETC" 64920 "AT1HI1" 64949 "DM23" 64950 "DM24" 64951 "DM25" 64952 "DM26" 64953 "TPRI" 64965 "ECUID" 64981 "EEC5" 65039 "LC" 65099 "TCFG2" 65109 "GFD" 65127 "CCC" 65131 "DI" 65136 "CVW" 65144 "TP1" 65145 "TP2" 65146 "TP3" 65195 "ETC6" 65196 "EBC4" 65199 "GFC" 65201 "EH" 65202 "GFI1" 65203 "LFI1" 65208 "GTFI" 65212 "CBI" 65214 "EEC4" 65216 "SERV" 65219 "ETC5" 65221 "ETC4" 65223 "ETC3" 65227 "DM02" 65228 "DM03" 65229 "DM04" 65230 "DM05" 65231 "DM06" 65234 "DM10" 65235 "DM11" 65236 "DM12" 65242 "SOFT" 65244 "IO" 65248 "VD" 65250 "TCFG" 65253 "HOURS" 65254 "TD" 65255 "VH" 65256 "VDS" 65257 "LFC1" 65258 "VW" 65259 "CI" 65260 "VI" 65261 "CCSS" 65284 "PB_DriversConsentOnPersonalData" 65340 "PB_HVESSCFG" 65376 "VehCfg" 65413 "PB_3CT" 65482 "PB_ID1" 65484 "PB_VNS" 65502 "Av2" 65520 "SCh" 65521 "DIS" 65524 "PB_IVA" ;
VAL_ 2565406707 Pgn_Ack_E8FFF3 37120 "VLSI1" 40448 "DM29" 41216 "DM33" 41728 "DM31" 41984 "DM30" 47360 "PLLT (Plan List Lifetime)" 47872 "PLD (Plan List Distance)" 49408 "DM21" 49664 "DM20" 49920 "DM22" 53504 "MaintBcIc" 54016 "DM19" 60928 "ACL" 61184 "STOD" 64341 "HVESP3HIST" 64342 "HVESP3CFG" 64343 "HVESP2HIST" 64344 "HVESP2CFG" 64345 "HVESP1HIST" 64346 "HVESP1CFG" 64529 "TGFI" 64579 "TCSI" 64582 "TSIS" 64583 "MTI" 64605 "HVESSCFG" 64606 "HVESSHIST" 64653 "PII" 64701 "A1SCRSI2" 64782 "AT1OGC2" 64784 "AT1IGC2" 64839 "TML" 64879 "EEC8" 64896 "DM28" 64905 "VDS2" 64906 "J2012" 64912 "AETC" 64920 "AT1HI1" 64949 "DM23" 64950 "DM24" 64951 "DM25" 64952 "DM26" 64953 "TPRI" 64965 "ECUID" 64981 "EEC5" 65039 "LC" 65099 "TCFG2" 65109 "GFD" 65127 "CCC" 65131 "DI" 65136 "CVW" 65144 "TP1" 65145 "TP2" 65146 "TP3" 65195 "ETC6" 65196 "EBC4" 65199 "GFC" 65201 "EH" 65202 "GFI1" 65203 "LFI1" 65208 "GTFI" 65212 "CBI" 65214 "EEC4" 65216 "SERV" 65219 "ETC5" 65221 "ETC4" 65223 "ETC3" 65227 "DM02" 65228 "DM03" 65229 "DM04" 65230 "DM05" 65231 "DM06" 65234 "DM10" 65235 "DM11" 65236 "DM12" 65242 "SOFT" 65244 "IO" 65248 "VD" 65250 "TCFG" 65253 "HOURS" 65254 "TD" 65255 "VH" 65256 "VDS" 65257 "LFC1" 65258 "VW" 65259 "CI" 65260 "VI" 65261 "CCSS" 65284 "PB_DriversConsentOnPersonalData" 65340 "PB_HVESSCFG" 65376 "VehCfg" 65413 "PB_3CT" 65482 "PB_ID1" 65484 "PB_VNS" 65502 "Av2" 65520 "SCh" 65521 "DIS" 65524 "PB_IVA" ;
VAL_ 2565406707 Pgn_Nack_E8FFF3 37120 "VLSI1" 40448 "DM29" 41216 "DM33" 41728 "DM31" 41984 "DM30" 47360 "PLLT (Plan List Lifetime)" 47872 "PLD (Plan List Distance)" 49408 "DM21" 49664 "DM20" 49920 "DM22" 53504 "MaintBcIc" 54016 "DM19" 60928 "ACL" 61184 "STOD" 64341 "HVESP3HIST" 64342 "HVESP3CFG" 64343 "HVESP2HIST" 64344 "HVESP2CFG" 64345 "HVESP1HIST" 64346 "HVESP1CFG" 64529 "TGFI" 64579 "TCSI" 64582 "TSIS" 64583 "MTI" 64605 "HVESSCFG" 64606 "HVESSHIST" 64653 "PII" 64701 "A1SCRSI2" 64782 "AT1OGC2" 64784 "AT1IGC2" 64839 "TML" 64879 "EEC8" 64896 "DM28" 64905 "VDS2" 64906 "J2012" 64912 "AETC" 64920 "AT1HI1" 64949 "DM23" 64950 "DM24" 64951 "DM25" 64952 "DM26" 64953 "TPRI" 64965 "ECUID" 64981 "EEC5" 65039 "LC" 65099 "TCFG2" 65109 "GFD" 65127 "CCC" 65131 "DI" 65136 "CVW" 65144 "TP1" 65145 "TP2" 65146 "TP3" 65195 "ETC6" 65196 "EBC4" 65199 "GFC" 65201 "EH" 65202 "GFI1" 65203 "LFI1" 65208 "GTFI" 65212 "CBI" 65214 "EEC4" 65216 "SERV" 65219 "ETC5" 65221 "ETC4" 65223 "ETC3" 65227 "DM02" 65228 "DM03" 65229 "DM04" 65230 "DM05" 65231 "DM06" 65234 "DM10" 65235 "DM11" 65236 "DM12" 65242 "SOFT" 65244 "IO" 65248 "VD" 65250 "TCFG" 65253 "HOURS" 65254 "TD" 65255 "VH" 65256 "VDS" 65257 "LFC1" 65258 "VW" 65259 "CI" 65260 "VI" 65261 "CCSS" 65284 "PB_DriversConsentOnPersonalData" 65340 "PB_HVESSCFG" 65376 "VehCfg" 65413 "PB_3CT" 65482 "PB_ID1" 65484 "PB_VNS" 65502 "Av2" 65520 "SCh" 65521 "DIS" 65524 "PB_IVA" ;
VAL_ 2565406707 Pgn_Ad_E8FFF3 37120 "VLSI1" 40448 "DM29" 41216 "DM33" 41728 "DM31" 41984 "DM30" 47360 "PLLT (Plan List Lifetime)" 47872 "PLD (Plan List Distance)" 49408 "DM21" 49664 "DM20" 49920 "DM22" 53504 "MaintBcIc" 54016 "DM19" 60928 "ACL" 61184 "STOD" 64341 "HVESP3HIST" 64342 "HVESP3CFG" 64343 "HVESP2HIST" 64344 "HVESP2CFG" 64345 "HVESP1HIST" 64346 "HVESP1CFG" 64529 "TGFI" 64579 "TCSI" 64582 "TSIS" 64583 "MTI" 64605 "HVESSCFG" 64606 "HVESSHIST" 64653 "PII" 64701 "A1SCRSI2" 64782 "AT1OGC2" 64784 "AT1IGC2" 64839 "TML" 64879 "EEC8" 64896 "DM28" 64905 "VDS2" 64906 "J2012" 64912 "AETC" 64920 "AT1HI1" 64949 "DM23" 64950 "DM24" 64951 "DM25" 64952 "DM26" 64953 "TPRI" 64965 "ECUID" 64981 "EEC5" 65039 "LC" 65099 "TCFG2" 65109 "GFD" 65127 "CCC" 65131 "DI" 65136 "CVW" 65144 "TP1" 65145 "TP2" 65146 "TP3" 65195 "ETC6" 65196 "EBC4" 65199 "GFC" 65201 "EH" 65202 "GFI1" 65203 "LFI1" 65208 "GTFI" 65212 "CBI" 65214 "EEC4" 65216 "SERV" 65219 "ETC5" 65221 "ETC4" 65223 "ETC3" 65227 "DM02" 65228 "DM03" 65229 "DM04" 65230 "DM05" 65231 "DM06" 65234 "DM10" 65235 "DM11" 65236 "DM12" 65242 "SOFT" 65244 "IO" 65248 "VD" 65250 "TCFG" 65253 "HOURS" 65254 "TD" 65255 "VH" 65256 "VDS" 65257 "LFC1" 65258 "VW" 65259 "CI" 65260 "VI" 65261 "CCSS" 65284 "PB_DriversConsentOnPersonalData" 65340 "PB_HVESSCFG" 65376 "VehCfg" 65413 "PB_3CT" 65482 "PB_ID1" 65484 "PB_VNS" 65502 "Av2" 65520 "SCh" 65521 "DIS" 65524 "PB_IVA" ;
VAL_ 2565406707 Pgn_Busy_E8FFF3 37120 "VLSI1" 40448 "DM29" 41216 "DM33" 41728 "DM31" 41984 "DM30" 47360 "PLLT (Plan List Lifetime)" 47872 "PLD (Plan List Distance)" 49408 "DM21" 49664 "DM20" 49920 "DM22" 53504 "MaintBcIc" 54016 "DM19" 60928 "ACL" 61184 "STOD" 64341 "HVESP3HIST" 64342 "HVESP3CFG" 64343 "HVESP2HIST" 64344 "HVESP2CFG" 64345 "HVESP1HIST" 64346 "HVESP1CFG" 64529 "TGFI" 64579 "TCSI" 64582 "TSIS" 64583 "MTI" 64605 "HVESSCFG" 64606 "HVESSHIST" 64653 "PII" 64701 "A1SCRSI2" 64782 "AT1OGC2" 64784 "AT1IGC2" 64839 "TML" 64879 "EEC8" 64896 "DM28" 64905 "VDS2" 64906 "J2012" 64912 "AETC" 64920 "AT1HI1" 64949 "DM23" 64950 "DM24" 64951 "DM25" 64952 "DM26" 64953 "TPRI" 64965 "ECUID" 64981 "EEC5" 65039 "LC" 65099 "TCFG2" 65109 "GFD" 65127 "CCC" 65131 "DI" 65136 "CVW" 65144 "TP1" 65145 "TP2" 65146 "TP3" 65195 "ETC6" 65196 "EBC4" 65199 "GFC" 65201 "EH" 65202 "GFI1" 65203 "LFI1" 65208 "GTFI" 65212 "CBI" 65214 "EEC4" 65216 "SERV" 65219 "ETC5" 65221 "ETC4" 65223 "ETC3" 65227 "DM02" 65228 "DM03" 65229 "DM04" 65230 "DM05" 65231 "DM06" 65234 "DM10" 65235 "DM11" 65236 "DM12" 65242 "SOFT" 65244 "IO" 65248 "VD" 65250 "TCFG" 65253 "HOURS" 65254 "TD" 65255 "VH" 65256 "VDS" 65257 "LFC1" 65258 "VW" 65259 "CI" 65260 "VI" 65261 "CCSS" 65284 "PB_DriversConsentOnPersonalData" 65340 "PB_HVESSCFG" 65376 "VehCfg" 65413 "PB_3CT" 65482 "PB_ID1" 65484 "PB_VNS" 65502 "Av2" 65520 "SCh" 65521 "DIS" 65524 "PB_IVA" ;
VAL_ 2565406708 Pgn_Ack_E8FFF4 37120 "VLSI1" 40448 "DM29" 41216 "DM33" 41728 "DM31" 41984 "DM30" 47360 "PLLT (Plan List Lifetime)" 47872 "PLD (Plan List Distance)" 49408 "DM21" 49664 "DM20" 49920 "DM22" 53504 "MaintBcIc" 54016 "DM19" 60928 "ACL" 61184 "STOD" 64341 "HVESP3HIST" 64342 "HVESP3CFG" 64343 "HVESP2HIST" 64344 "HVESP2CFG" 64345 "HVESP1HIST" 64346 "HVESP1CFG" 64529 "TGFI" 64579 "TCSI" 64582 "TSIS" 64583 "MTI" 64605 "HVESSCFG" 64606 "HVESSHIST" 64653 "PII" 64701 "A1SCRSI2" 64782 "AT1OGC2" 64784 "AT1IGC2" 64839 "TML" 64879 "EEC8" 64896 "DM28" 64905 "VDS2" 64906 "J2012" 64912 "AETC" 64920 "AT1HI1" 64949 "DM23" 64950 "DM24" 64951 "DM25" 64952 "DM26" 64953 "TPRI" 64965 "ECUID" 64981 "EEC5" 65039 "LC" 65099 "TCFG2" 65109 "GFD" 65127 "CCC" 65131 "DI" 65136 "CVW" 65144 "TP1" 65145 "TP2" 65146 "TP3" 65195 "ETC6" 65196 "EBC4" 65199 "GFC" 65201 "EH" 65202 "GFI1" 65203 "LFI1" 65208 "GTFI" 65212 "CBI" 65214 "EEC4" 65216 "SERV" 65219 "ETC5" 65221 "ETC4" 65223 "ETC3" 65227 "DM02" 65228 "DM03" 65229 "DM04" 65230 "DM05" 65231 "DM06" 65234 "DM10" 65235 "DM11" 65236 "DM12" 65242 "SOFT" 65244 "IO" 65248 "VD" 65250 "TCFG" 65253 "HOURS" 65254 "TD" 65255 "VH" 65256 "VDS" 65257 "LFC1" 65258 "VW" 65259 "CI" 65260 "VI" 65261 "CCSS" 65284 "PB_DriversConsentOnPersonalData" 65340 "PB_HVESSCFG" 65376 "VehCfg" 65413 "PB_3CT" 65482 "PB_ID1" 65484 "PB_VNS" 65502 "Av2" 65520 "SCh" 65521 "DIS" 65524 "PB_IVA" ;
VAL_ 2565406708 Pgn_Nack_E8FFF4 37120 "VLSI1" 40448 "DM29" 41216 "DM33" 41728 "DM31" 41984 "DM30" 47360 "PLLT (Plan List Lifetime)" 47872 "PLD (Plan List Distance)" 49408 "DM21" 49664 "DM20" 49920 "DM22" 53504 "MaintBcIc" 54016 "DM19" 60928 "ACL" 61184 "STOD" 64341 "HVESP3HIST" 64342 "HVESP3CFG" 64343 "HVESP2HIST" 64344 "HVESP2CFG" 64345 "HVESP1HIST" 64346 "HVESP1CFG" 64529 "TGFI" 64579 "TCSI" 64582 "TSIS" 64583 "MTI" 64605 "HVESSCFG" 64606 "HVESSHIST" 64653 "PII" 64701 "A1SCRSI2" 64782 "AT1OGC2" 64784 "AT1IGC2" 64839 "TML" 64879 "EEC8" 64896 "DM28" 64905 "VDS2" 64906 "J2012" 64912 "AETC" 64920 "AT1HI1" 64949 "DM23" 64950 "DM24" 64951 "DM25" 64952 "DM26" 64953 "TPRI" 64965 "ECUID" 64981 "EEC5" 65039 "LC" 65099 "TCFG2" 65109 "GFD" 65127 "CCC" 65131 "DI" 65136 "CVW" 65144 "TP1" 65145 "TP2" 65146 "TP3" 65195 "ETC6" 65196 "EBC4" 65199 "GFC" 65201 "EH" 65202 "GFI1" 65203 "LFI1" 65208 "GTFI" 65212 "CBI" 65214 "EEC4" 65216 "SERV" 65219 "ETC5" 65221 "ETC4" 65223 "ETC3" 65227 "DM02" 65228 "DM03" 65229 "DM04" 65230 "DM05" 65231 "DM06" 65234 "DM10" 65235 "DM11" 65236 "DM12" 65242 "SOFT" 65244 "IO" 65248 "VD" 65250 "TCFG" 65253 "HOURS" 65254 "TD" 65255 "VH" 65256 "VDS" 65257 "LFC1" 65258 "VW" 65259 "CI" 65260 "VI" 65261 "CCSS" 65284 "PB_DriversConsentOnPersonalData" 65340 "PB_HVESSCFG" 65376 "VehCfg" 65413 "PB_3CT" 65482 "PB_ID1" 65484 "PB_VNS" 65502 "Av2" 65520 "SCh" 65521 "DIS" 65524 "PB_IVA" ;
VAL_ 2565406708 Pgn_Ad_E8FFF4 37120 "VLSI1" 40448 "DM29" 41216 "DM33" 41728 "DM31" 41984 "DM30" 47360 "PLLT (Plan List Lifetime)" 47872 "PLD (Plan List Distance)" 49408 "DM21" 49664 "DM20" 49920 "DM22" 53504 "MaintBcIc" 54016 "DM19" 60928 "ACL" 61184 "STOD" 64341 "HVESP3HIST" 64342 "HVESP3CFG" 64343 "HVESP2HIST" 64344 "HVESP2CFG" 64345 "HVESP1HIST" 64346 "HVESP1CFG" 64529 "TGFI" 64579 "TCSI" 64582 "TSIS" 64583 "MTI" 64605 "HVESSCFG" 64606 "HVESSHIST" 64653 "PII" 64701 "A1SCRSI2" 64782 "AT1OGC2" 64784 "AT1IGC2" 64839 "TML" 64879 "EEC8" 64896 "DM28" 64905 "VDS2" 64906 "J2012" 64912 "AETC" 64920 "AT1HI1" 64949 "DM23" 64950 "DM24" 64951 "DM25" 64952 "DM26" 64953 "TPRI" 64965 "ECUID" 64981 "EEC5" 65039 "LC" 65099 "TCFG2" 65109 "GFD" 65127 "CCC" 65131 "DI" 65136 "CVW" 65144 "TP1" 65145 "TP2" 65146 "TP3" 65195 "ETC6" 65196 "EBC4" 65199 "GFC" 65201 "EH" 65202 "GFI1" 65203 "LFI1" 65208 "GTFI" 65212 "CBI" 65214 "EEC4" 65216 "SERV" 65219 "ETC5" 65221 "ETC4" 65223 "ETC3" 65227 "DM02" 65228 "DM03" 65229 "DM04" 65230 "DM05" 65231 "DM06" 65234 "DM10" 65235 "DM11" 65236 "DM12" 65242 "SOFT" 65244 "IO" 65248 "VD" 65250 "TCFG" 65253 "HOURS" 65254 "TD" 65255 "VH" 65256 "VDS" 65257 "LFC1" 65258 "VW" 65259 "CI" 65260 "VI" 65261 "CCSS" 65284 "PB_DriversConsentOnPersonalData" 65340 "PB_HVESSCFG" 65376 "VehCfg" 65413 "PB_3CT" 65482 "PB_ID1" 65484 "PB_VNS" 65502 "Av2" 65520 "SCh" 65521 "DIS" 65524 "PB_IVA" ;
VAL_ 2565406708 Pgn_Busy_E8FFF4 37120 "VLSI1" 40448 "DM29" 41216 "DM33" 41728 "DM31" 41984 "DM30" 47360 "PLLT (Plan List Lifetime)" 47872 "PLD (Plan List Distance)" 49408 "DM21" 49664 "DM20" 49920 "DM22" 53504 "MaintBcIc" 54016 "DM19" 60928 "ACL" 61184 "STOD" 64341 "HVESP3HIST" 64342 "HVESP3CFG" 64343 "HVESP2HIST" 64344 "HVESP2CFG" 64345 "HVESP1HIST" 64346 "HVESP1CFG" 64529 "TGFI" 64579 "TCSI" 64582 "TSIS" 64583 "MTI" 64605 "HVESSCFG" 64606 "HVESSHIST" 64653 "PII" 64701 "A1SCRSI2" 64782 "AT1OGC2" 64784 "AT1IGC2" 64839 "TML" 64879 "EEC8" 64896 "DM28" 64905 "VDS2" 64906 "J2012" 64912 "AETC" 64920 "AT1HI1" 64949 "DM23" 64950 "DM24" 64951 "DM25" 64952 "DM26" 64953 "TPRI" 64965 "ECUID" 64981 "EEC5" 65039 "LC" 65099 "TCFG2" 65109 "GFD" 65127 "CCC" 65131 "DI" 65136 "CVW" 65144 "TP1" 65145 "TP2" 65146 "TP3" 65195 "ETC6" 65196 "EBC4" 65199 "GFC" 65201 "EH" 65202 "GFI1" 65203 "LFI1" 65208 "GTFI" 65212 "CBI" 65214 "EEC4" 65216 "SERV" 65219 "ETC5" 65221 "ETC4" 65223 "ETC3" 65227 "DM02" 65228 "DM03" 65229 "DM04" 65230 "DM05" 65231 "DM06" 65234 "DM10" 65235 "DM11" 65236 "DM12" 65242 "SOFT" 65244 "IO" 65248 "VD" 65250 "TCFG" 65253 "HOURS" 65254 "TD" 65255 "VH" 65256 "VDS" 65257 "LFC1" 65258 "VW" 65259 "CI" 65260 "VI" 65261 "CCSS" 65284 "PB_DriversConsentOnPersonalData" 65340 "PB_HVESSCFG" 65376 "VehCfg" 65413 "PB_3CT" 65482 "PB_ID1" 65484 "PB_VNS" 65502 "Av2" 65520 "SCh" 65521 "DIS" 65524 "PB_IVA" ;
